VERSION ""

NS_ :

BS_:

BU_: APIM_CISM DSP WCM HUD_ADV ACM GWM _delete APIM IPC GENERIC TSTR

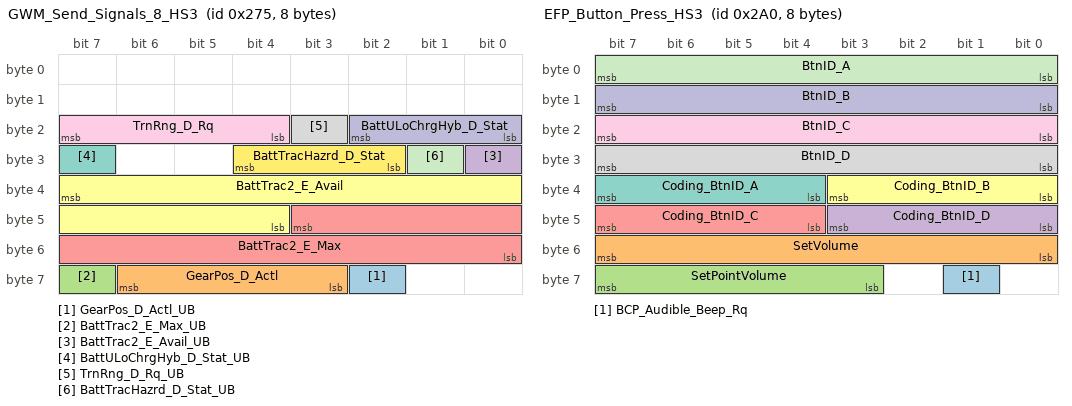
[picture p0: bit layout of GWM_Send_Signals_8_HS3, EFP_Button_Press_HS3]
BO_ 629 GWM_Send_Signals_8_HS3: 8 GWM
 SG_ GearPos_D_Actl_UB : 58|1@0+ (1,0) [0|1] "SED"  APIM_CISM,APIM
 SG_ GearPos_D_Actl : 62|4@0+ (1,0) [0|15] "SED"  APIM_CISM,APIM
 SG_ BattTrac2_E_Max_UB : 63|1@0+ (1,0) [0|1] "SED"  APIM_CISM,APIM
 SG_ BattTrac2_E_Avail_UB : 24|1@0+ (1,0) [0|1] "SED"  APIM
 SG_ BattTrac2_E_Max : 43|12@0+ (50,0) [0|204650] "watt*hour"  APIM_CISM,APIM
 SG_ BattTrac2_E_Avail : 39|12@0+ (50,0) [0|204650] "watt*hour"  APIM
 SG_ BattULoChrgHyb_D_Stat_UB : 31|1@0+ (1,0) [0|1] "SED"  IPC
 SG_ TrnRng_D_Rq_UB : 19|1@0+ (1,0) [0|1] "SED"  APIM_CISM,APIM
 SG_ TrnRng_D_Rq : 23|4@0+ (1,0) [0|15] "SED"  APIM_CISM,APIM
 SG_ BattULoChrgHyb_D_Stat : 18|3@0+ (1,0) [0|7] "SED"  IPC
 SG_ BattTracHazrd_D_Stat_UB : 25|1@0+ (1,0) [0|1] "SED"  IPC
 SG_ BattTracHazrd_D_Stat : 28|3@0+ (1,0) [0|7] "SED"  IPC

BO_ 672 EFP_Button_Press_HS3: 8 GWM
 SG_ BCP_Audible_Beep_Rq : 57|1@0+ (1,0) [0|1] "SED"  ACM,DSP
 SG_ SetVolume : 55|8@0+ (1,-30) [-30|30] "unitless"  DSP,ACM,APIM
 SG_ SetPointVolume : 63|5@0+ (1,0) [0|31] "unitless"  DSP,ACM,APIM
 SG_ Coding_BtnID_D : 43|4@0+ (1,0) [0|15] "SED"  ACM,APIM
 SG_ Coding_BtnID_C : 47|4@0+ (1,0) [0|15] "SED"  ACM,APIM
 SG_ Coding_BtnID_B : 35|4@0+ (1,0) [0|15] "SED"  ACM,APIM
 SG_ Coding_BtnID_A : 39|4@0+ (1,0) [0|15] "SED"  ACM,APIM
 SG_ BtnID_D : 31|8@0+ (1,0) [0|255] "unitless"  ACM,APIM
 SG_ BtnID_C : 23|8@0+ (1,0) [0|255] "unitless"  ACM,APIM
 SG_ BtnID_B : 15|8@0+ (1,0) [0|255] "unitless"  ACM,APIM
 SG_ BtnID_A : 7|8@0+ (1,0) [0|255] "unitless"  ACM,APIM

BO_ 1829 TesterPhysicalReqWCM: 8 TSTR
 SG_ TesterPhysicalReqWCM : 7|64@0+ (1,0) [0|1.84467E+019] "unitless"  WCM

BO_ 601 ECG_MC_WORD_Rx: 8 IPC
 SG_ ECG_MC_WORD_Rx : 7|64@0+ (1,0) [0|1.84467440737096E+019] "unitless"  GWM

BO_ 593 ECG_MC_WORD_Tx: 8 GWM
 SG_ ECG_MC_WORD_Tx : 7|64@0+ (1,0) [0|1.84467440737096E+019] "unitless"  IPC

BO_ 816 APIM_Send_Signals_3: 8 APIM
 SG_ Dimming_Lvl_RqMnu : 63|5@0+ (1,0) [0|31] "SED"  GWM
 SG_ DcacZone3Pw_D_Rq : 55|2@0+ (1,0) [0|3] "SED"  GWM
 SG_ DcacZone2Pw_D_Rq : 35|2@0+ (1,0) [0|3] "SED"  GWM
 SG_ DcacPwScnd_D_Rq : 53|2@0+ (1,0) [0|3] "SED"  GWM
 SG_ DcacPwResetScnd_B_Rq : 24|1@0+ (1,0) [0|1] "SED"  GWM
 SG_ DcacLoFuelLim_L_RqMnu : 32|9@0+ (1,0) [0|511] "kilometer"  GWM
 SG_ DcacAllZone_D_Rq : 37|2@0+ (1,0) [0|3] "SED"  GWM
 SG_ HybMdeSel_D_Rq : 58|3@0+ (1,0) [0|7] "SED"  GWM
 SG_ KeylessIdl_D_Rq : 39|2@0+ (1,0) [0|3] "SED"  GWM
 SG_ KeyPadCodeDgt7_D_Stat : 31|4@0+ (1,0) [0|15] "SED"  GWM
 SG_ KeyPadCodeDgt6_D_Stat : 19|4@0+ (1,0) [0|15] "SED"  GWM
 SG_ KeyPadCodeDgt5_D_Stat : 23|4@0+ (1,0) [0|15] "SED"  GWM
 SG_ KeyPadCodeDgt4_D_Stat : 11|4@0+ (1,0) [0|15] "SED"  GWM
 SG_ KeyPadCodeDgt3_D_Stat : 15|4@0+ (1,0) [0|15] "SED"  GWM
 SG_ KeyPadCodeDgt2_D_Stat : 3|4@0+ (1,0) [0|15] "SED"  GWM
 SG_ KeyPadCodeDgt1_D_Stat : 7|4@0+ (1,0) [0|15] "SED"  GWM
 SG_ CntrStk2_D_RqAssoc : 27|3@0+ (1,0) [0|7] "SED"  GWM

BO_ 636 TCU_Send_Signals_3_HS3: 8 GWM
 SG_ WifiHtsptFqBand_D_Stat : 60|2@0+ (1,0) [0|3] "SED"  APIM_CISM,ACM,APIM
 SG_ WifiHtspt_D_Falt : 51|4@0+ (1,0) [0|15] "SED"  APIM_CISM,ACM,APIM
 SG_ WifiNoDevcCnnct_No_Actl : 47|8@0+ (1,0) [0|255] "unitless"  APIM_CISM,APIM
 SG_ WifiHtsptCnnct_D_Stat : 26|2@0+ (1,0) [0|3] "SED"  APIM_CISM,APIM
 SG_ Telematics_D_Falt : 39|3@0+ (1,0) [0|7] "SED"  APIM_CISM,APIM
 SG_ WifiEnbl_D_Stat : 4|2@0+ (1,0) [0|3] "SED"  APIM_CISM,APIM
 SG_ WifiHtsptVisbl_D_Stat : 13|2@0+ (1,0) [0|3] "SED"  APIM_CISM,APIM
 SG_ WifiHtsptScrty_D_Stat : 15|2@0+ (1,0) [0|3] "SED"  APIM_CISM,APIM
 SG_ WifiHtsptEnbl_D_Stat : 2|2@0+ (1,0) [0|3] "SED"  APIM_CISM,APIM
 SG_ WifiDevcListNew_B_Stat : 5|1@0+ (1,0) [0|1] "SED"  APIM_CISM,APIM
 SG_ WifiDataUsage_Pc_Actl : 20|4@0+ (5,50) [50|125] "percent"  APIM_CISM,APIM
 SG_ WifiDataUsage_D_Stat : 7|2@0+ (1,0) [0|3] "SED"  APIM_CISM,APIM
 SG_ ModemSigStren_D_Stat : 11|3@0+ (1,0) [0|7] "SED"  APIM_CISM,ACM,APIM
 SG_ ModemTechnology_D2_Stat : 31|3@0+ (1,0) [0|7] "SED"  APIM_CISM,HUD_ADV,APIM
 SG_ WifiHtsptCrdntl_B_Stat : 0|1@0+ (1,0) [0|1] "SED"  APIM_CISM,APIM
 SG_ WifiHtsptFq_D_Avail : 63|3@0+ (1,0) [0|7] "SED"  APIM_CISM,ACM,APIM
 SG_ WifiDataUsageOn_D_Stat : 28|2@0+ (1,0) [0|3] "SED"  APIM_CISM,APIM

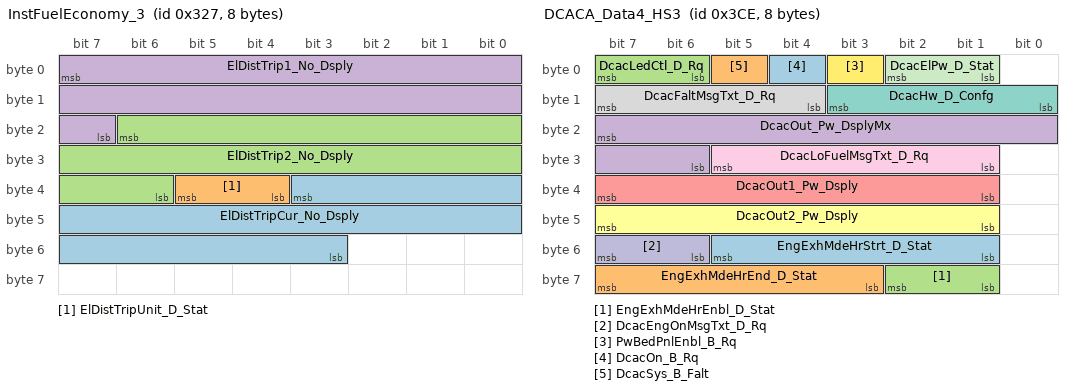
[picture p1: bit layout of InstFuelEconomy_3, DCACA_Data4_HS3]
BO_ 807 InstFuelEconomy_3: 8 IPC
 SG_ ElDistTripCur_No_Dsply : 35|17@0+ (0.1,0) [0|13107.1] "unitless"  APIM
 SG_ ElDistTripUnit_D_Stat : 37|2@0+ (1,0) [0|3] "SED"  APIM
 SG_ ElDistTrip2_No_Dsply : 22|17@0+ (0.1,0) [0|13107.1] "unitless"  APIM
 SG_ ElDistTrip1_No_Dsply : 7|17@0+ (0.1,0) [0|13107.1] "unitless"  APIM

BO_ 974 DCACA_Data4_HS3: 8 GWM
 SG_ EngExhMdeHrStrt_D_Stat : 53|5@0+ (1,0) [0|31] "SED"  APIM
 SG_ EngExhMdeHrEnd_D_Stat : 63|5@0+ (1,0) [0|31] "SED"  APIM
 SG_ EngExhMdeHrEnbl_D_Stat : 58|2@0+ (1,0) [0|3] "SED"  APIM
 SG_ DcacOut_Pw_DsplyMx : 23|10@0+ (10,0) [0|10220] "watts"  APIM
 SG_ DcacOut1_Pw_Dsply : 39|7@0+ (100,0) [0|12600] "watts"  APIM
 SG_ DcacOut2_Pw_Dsply : 47|7@0+ (100,0) [0|12600] "watts"  APIM
 SG_ DcacHw_D_Confg : 11|4@0+ (1,0) [0|15] "SED"  APIM
 SG_ DcacFaltMsgTxt_D_Rq : 15|4@0+ (1,0) [0|15] "SED"  APIM
 SG_ DcacLoFuelMsgTxt_D_Rq : 29|5@0+ (1,0) [0|31] "SED"  APIM
 SG_ DcacEngOnMsgTxt_D_Rq : 55|2@0+ (1,0) [0|3] "SED"  APIM
 SG_ DcacElPw_D_Stat : 2|2@0+ (1,0) [0|3] "SED"  APIM
 SG_ PwBedPnlEnbl_B_Rq : 3|1@0+ (1,0) [0|1] "SED"  GENERIC
 SG_ DcacOn_B_Rq : 4|1@0+ (1,0) [0|1] "SED"  GENERIC
 SG_ DcacSys_B_Falt : 5|1@0+ (1,0) [0|1] "SED"  GENERIC
 SG_ DcacLedCtl_D_Rq : 7|2@0+ (1,0) [0|3] "SED" Vector__XXX

BO_ 805 InstFuelEconomy_2: 8 IPC
 SG_ InstFeTripUnit_D_Stat : 23|4@0+ (1,0) [0|15] "SED"  APIM
 SG_ InstFe_No_Dsply : 7|14@0+ (0.1,0) [0|1638.3] "unitless"  APIM

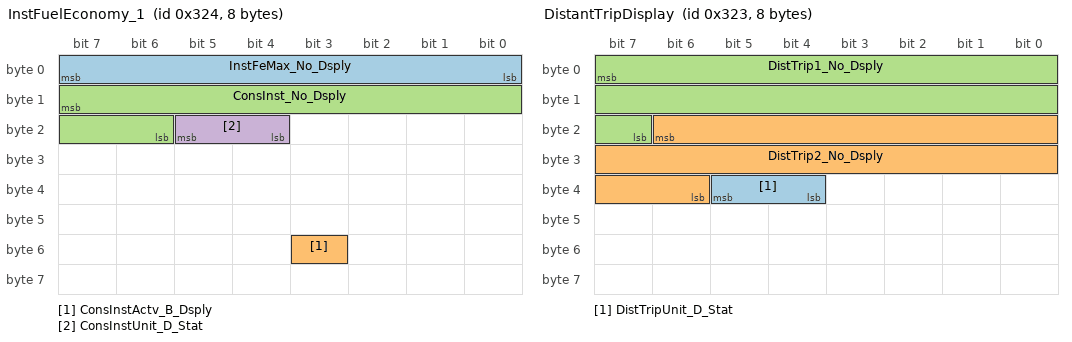
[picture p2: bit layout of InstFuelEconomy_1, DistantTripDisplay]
BO_ 804 InstFuelEconomy_1: 8 IPC
 SG_ InstFeMax_No_Dsply : 7|8@0+ (1,0) [0|255] "unitless"  APIM
 SG_ ConsInstActv_B_Dsply : 51|1@0+ (1,0) [0|1] "SED"  APIM
 SG_ ConsInst_No_Dsply : 15|10@0+ (0.1,0) [0|102.3] "percent"  APIM
 SG_ ConsInstUnit_D_Stat : 21|2@0+ (1,0) [0|3] "SED"  APIM

BO_ 803 DistantTripDisplay: 8 IPC
 SG_ DistTripUnit_D_Stat : 37|2@0+ (1,0) [0|3] "SED"  APIM
 SG_ DistTrip2_No_Dsply : 22|17@0+ (0.1,0) [0|13107.1] "unitless"  APIM
 SG_ DistTrip1_No_Dsply : 7|17@0+ (0.1,0) [0|13107.1] "unitless"  APIM

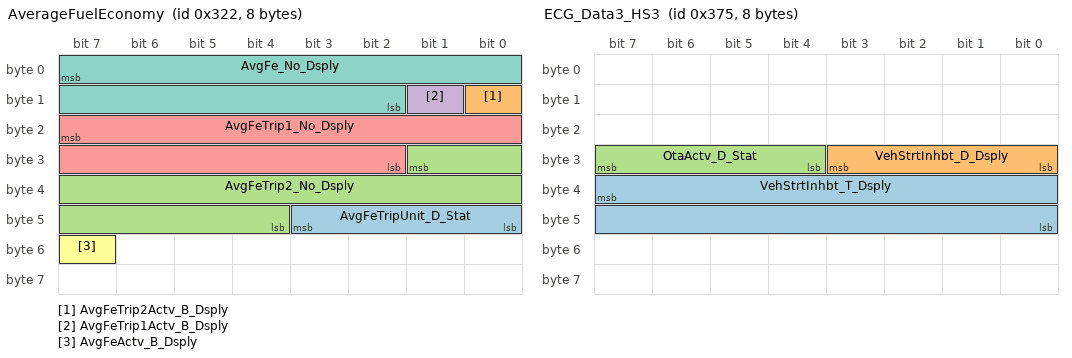
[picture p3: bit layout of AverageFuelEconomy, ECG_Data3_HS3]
BO_ 802 AverageFuelEconomy: 8 IPC
 SG_ AvgFeTripUnit_D_Stat : 43|4@0+ (1,0) [0|15] "SED"  APIM_CISM,APIM
 SG_ AvgFeTrip2Actv_B_Dsply : 8|1@0+ (1,0) [0|1] "SED"  APIM_CISM,APIM
 SG_ AvgFeTrip2_No_Dsply : 25|14@0+ (0.1,0) [0|1638.3] "unitless"  APIM_CISM,APIM
 SG_ AvgFeTrip1Actv_B_Dsply : 9|1@0+ (1,0) [0|1] "SED"  APIM_CISM,APIM
 SG_ AvgFeTrip1_No_Dsply : 23|14@0+ (0.1,0) [0|1638.3] "unitless"  APIM_CISM,APIM
 SG_ AvgFeActv_B_Dsply : 55|1@0+ (1,0) [0|1] "SED"  APIM_CISM,APIM
 SG_ AvgFe_No_Dsply : 7|14@0+ (0.1,0) [0|1638.3] "unitless"  APIM_CISM,APIM

BO_ 812 TimerDisplay_Data: 8 IPC
 SG_ TimerTrip2_T_Dsply : 29|26@0+ (1,0) [0|67108863] "second"  APIM
 SG_ TimerTrip1_T_Dsply : 7|26@0+ (1,0) [0|67108863] "second"  APIM

BO_ 885 ECG_Data3_HS3: 8 GWM
 SG_ VehStrtInhbt_T_Dsply : 39|16@0+ (1,0) [0|65535] "second"  IPC
 SG_ VehStrtInhbt_D_Dsply : 27|4@0+ (1,0) [0|15] "SED"  IPC
 SG_ OtaActv_D_Stat : 31|4@0+ (1,0) [0|15] "SED"  IPC

BO_ 1119 LocationServices_Data2: 8 APIM
 SG_ LocationServices_2 : 7|64@0+ (1,0) [0|1.84467440737096E+019] "unitless"  IPC,GWM

BO_ 1118 LocationServices_Data1: 8 APIM
 SG_ LocationServices_1 : 7|64@0+ (1,0) [0|1.84467440737096E+019] "unitless"  IPC,GWM

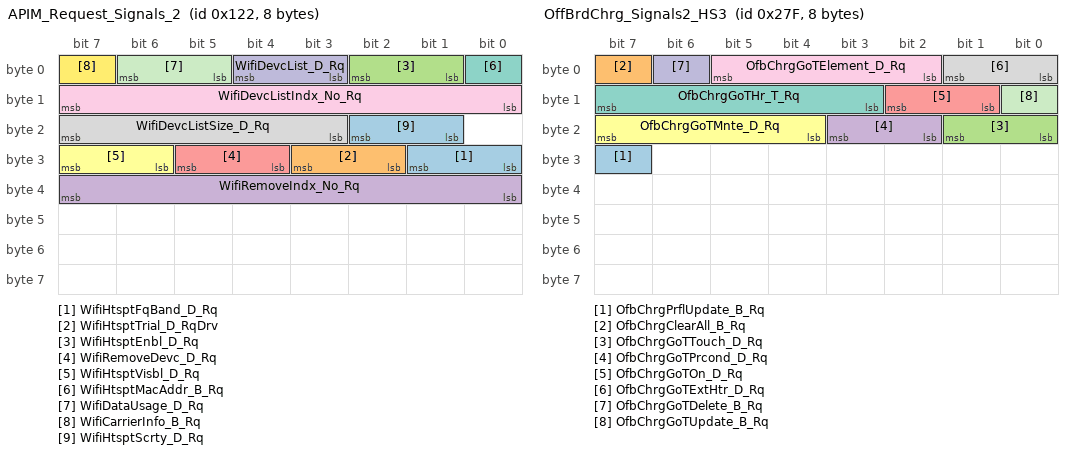
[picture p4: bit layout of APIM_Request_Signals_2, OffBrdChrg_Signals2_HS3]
BO_ 290 APIM_Request_Signals_2: 8 APIM
 SG_ WifiHtsptFqBand_D_Rq : 25|2@0+ (1,0) [0|3] "SED"  GWM
 SG_ WifiHtsptTrial_D_RqDrv : 27|2@0+ (1,0) [0|3] "SED"  GWM
 SG_ WifiHtsptEnbl_D_Rq : 2|2@0+ (1,0) [0|3] "SED"  GWM
 SG_ WifiRemoveIndx_No_Rq : 39|8@0+ (1,0) [0|255] "unitless"  GWM
 SG_ WifiRemoveDevc_D_Rq : 29|2@0+ (1,0) [0|3] "SED"  GWM
 SG_ WifiHtsptVisbl_D_Rq : 31|2@0+ (1,0) [0|3] "SED"  GWM
 SG_ WifiHtsptMacAddr_B_Rq : 0|1@0+ (1,0) [0|1] "SED"  GWM
 SG_ WifiDevcListSize_D_Rq : 23|5@0+ (1,0) [0|31] "unitless"  GWM
 SG_ WifiDevcListIndx_No_Rq : 15|8@0+ (1,0) [0|255] "unitless"  GWM
 SG_ WifiDevcList_D_Rq : 4|2@0+ (1,0) [0|3] "SED"  GWM
 SG_ WifiDataUsage_D_Rq : 6|2@0+ (1,0) [0|3] "SED"  GWM
 SG_ WifiCarrierInfo_B_Rq : 7|1@0+ (1,0) [0|1] "SED"  GWM
 SG_ WifiHtsptScrty_D_Rq : 18|2@0+ (1,0) [0|3] "SED"  GWM

BO_ 2612101336 PARSEDPushFcGWMtoIPC: 8 GWM
 SG_ PARSEDPushFcGWM_ECGtoIPC : 7|29@0+ (1,0) [0|536870911] "unitless"  IPC

BO_ 639 OffBrdChrg_Signals2_HS3: 8 GWM
 SG_ OfbChrgPrflUpdate_B_Rq : 31|1@0+ (1,0) [0|1] "SED"  APIM
 SG_ OfbChrgClearAll_B_Rq : 7|1@0+ (1,0) [0|1] "SED"  GENERIC
 SG_ OfbChrgGoTTouch_D_Rq : 17|2@0+ (1,0) [0|3] "SED"  GENERIC
 SG_ OfbChrgGoTPrcond_D_Rq : 19|2@0+ (1,0) [0|3] "SED"  GENERIC
 SG_ OfbChrgGoTOn_D_Rq : 10|2@0+ (1,0) [0|3] "SED"  GENERIC
 SG_ OfbChrgGoTMnte_D_Rq : 23|4@0+ (1,0) [0|15] "minute"  GENERIC
 SG_ OfbChrgGoTHr_T_Rq : 15|5@0+ (1,0) [0|29] "hour"  GENERIC
 SG_ OfbChrgGoTExtHtr_D_Rq : 1|2@0+ (1,0) [0|3] "SED"  GENERIC
 SG_ OfbChrgGoTElement_D_Rq : 5|4@0+ (1,0) [0|15] "Unitless"  GENERIC
 SG_ OfbChrgGoTDelete_B_Rq : 6|1@0+ (1,0) [0|1] "SED"  GENERIC
 SG_ OfbChrgGoTUpdate_B_Rq : 8|1@0+ (1,0) [0|1] "SED"  APIM

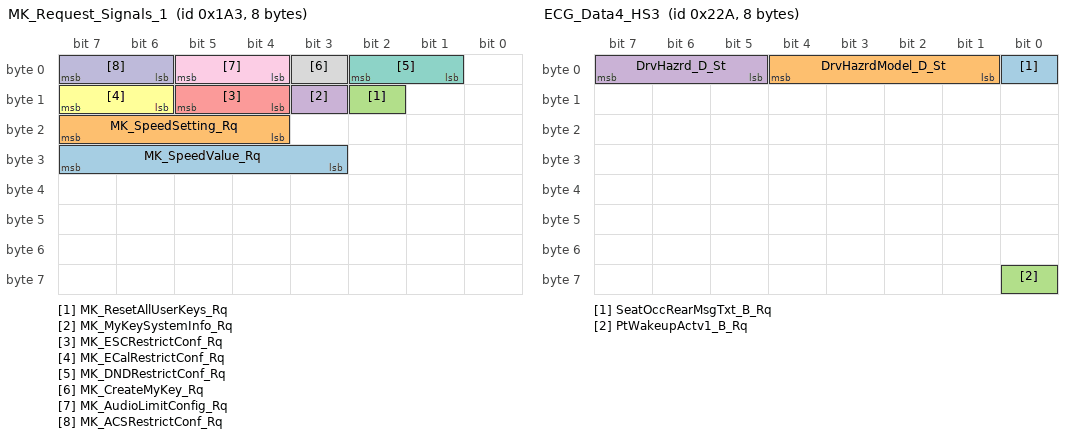
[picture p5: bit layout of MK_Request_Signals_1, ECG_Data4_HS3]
BO_ 419 MK_Request_Signals_1: 8 APIM
 SG_ MK_SpeedValue_Rq : 31|5@0+ (1,0) [0|31] "SED"  IPC
 SG_ MK_SpeedSetting_Rq : 23|4@0+ (1,0) [0|15] "SED"  IPC
 SG_ MK_ResetAllUserKeys_Rq : 10|1@0+ (1,0) [0|1] "SED"  IPC
 SG_ MK_MyKeySystemInfo_Rq : 11|1@0+ (1,0) [0|1] "SED"  IPC
 SG_ MK_ESCRestrictConf_Rq : 13|2@0+ (1,0) [0|3] "SED"  IPC
 SG_ MK_ECalRestrictConf_Rq : 15|2@0+ (1,0) [0|3] "SED"  IPC
 SG_ MK_DNDRestrictConf_Rq : 2|2@0+ (1,0) [0|3] "SED"  IPC
 SG_ MK_CreateMyKey_Rq : 3|1@0+ (1,0) [0|1] "SED"  IPC
 SG_ MK_AudioLimitConfig_Rq : 5|2@0+ (1,0) [0|3] "SED"  IPC
 SG_ MK_ACSRestrictConf_Rq : 7|2@0+ (1,0) [0|3] "SED"  IPC

BO_ 542 LocationServices_3_HS3: 8 GWM
 SG_ LocationServices_3 : 7|64@0+ (1,0) [0|1.84467440737096E+019] "unitless"  APIM_CISM,IPC,APIM,ACM

BO_ 554 ECG_Data4_HS3: 8 GWM
 SG_ SeatOccRearMsgTxt_B_Rq : 0|1@0+ (1,0) [0|1] "SED"  APIM_CISM,APIM
 SG_ DrvHazrdModel_D_St : 4|4@0+ (1,0) [0|15] "SED"  APIM_CISM,IPC,APIM
 SG_ PtWakeupActv1_B_Rq : 56|1@0+ (1,0) [0|1] "SED"  APIM_CISM,APIM
 SG_ DrvHazrd_D_St : 7|3@0+ (1,0) [0|7] "SED"  APIM_CISM,HUD_ADV,APIM,IPC

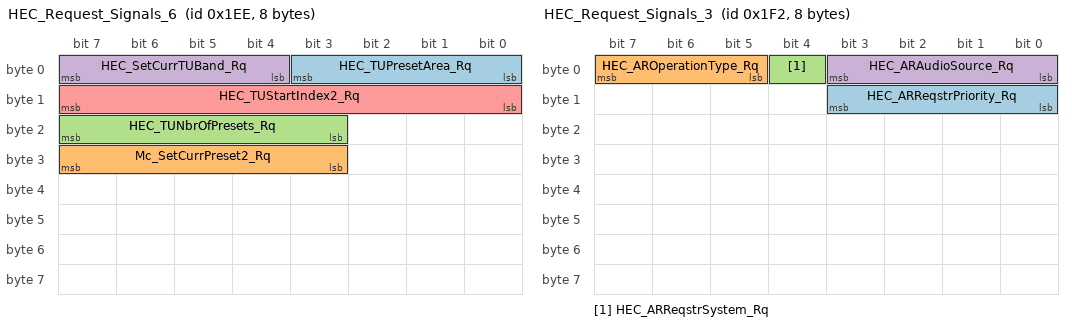
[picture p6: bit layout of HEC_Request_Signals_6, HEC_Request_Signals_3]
BO_ 494 HEC_Request_Signals_6: 8 IPC
 SG_ HEC_TUPresetArea_Rq : 3|4@0+ (1,0) [0|15] "SED"  ACM
 SG_ Mc_SetCurrPreset2_Rq : 31|5@0+ (1,0) [0|30] "SED"  ACM
 SG_ HEC_TUNbrOfPresets_Rq : 23|5@0+ (1,0) [0|30] "unitless"  ACM
 SG_ HEC_SetCurrTUBand_Rq : 7|4@0+ (1,0) [0|15] "SED"  ACM
 SG_ HEC_TUStartIndex2_Rq : 15|8@0+ (1,0) [0|255] "unitless"  ACM

BO_ 498 HEC_Request_Signals_3: 8 IPC
 SG_ HEC_ARReqstrPriority_Rq : 11|4@0+ (1,0) [0|15] "SED"  APIM_CISM,ACM
 SG_ HEC_AROperationType_Rq : 7|3@0+ (1,0) [0|7] "SED"  APIM_CISM,ACM
 SG_ HEC_ARReqstrSystem_Rq : 4|1@0+ (1,0) [0|1] "SED"  APIM_CISM,ACM
 SG_ HEC_ARAudioSource_Rq : 3|4@0+ (1,0) [0|15] "SED"  APIM_CISM,ACM

BO_ 644 GWM_Send_Signals_19_HS3: 8 GWM
 SG_ VehOnSrc_D_Stat_UB : 3|1@0+ (1,0) [0|1] "SED"  APIM_CISM,APIM,IPC
 SG_ VehOnSrc_D_Stat : 7|4@0+ (1,0) [0|15] "SED"  APIM_CISM,APIM,IPC

BO_ 643 GWM_Send_Signals_18_HS3: 8 GWM
 SG_ StrtInGearMsgTxt_D_Rq_UB : 48|1@0+ (1,0) [0|1] "SED"  IPC
 SG_ StrtInGearMsgTxt_D_Rq : 59|4@0+ (1,0) [0|15] "SED"  IPC
 SG_ StabBarCnnct_D_Stat_UB : 49|1@0+ (1,0) [0|1] "SED"  APIM
 SG_ StabBarCnnct_D_Stat : 63|4@0+ (1,0) [0|15] "SED"  APIM
 SG_ FstChrgCmplt_T_Est : 33|10@0+ (1,0) [0|1023] "minute"  IPC,APIM
 SG_ GearPos_D_Trg_UB : 23|1@0+ (1,0) [0|1] "SED"  APIM_CISM,APIM
 SG_ GearPos_D_Trg : 11|4@0+ (1,0) [0|15] "SED"  APIM_CISM,APIM
 SG_ PwTgateStepMsgTxt_B_Rq : 13|1@0+ (1,0) [0|1] "SED"  IPC
 SG_ PwTgateStepMsgTxt_B_Rq_UB : 12|1@0+ (1,0) [0|1] "SED"  IPC
 SG_ PwTgateMsgTxt_B_Rq_UB : 14|1@0+ (1,0) [0|1] "SED"  IPC
 SG_ PwTgateLamp_B_Rq_UB : 0|1@0+ (1,0) [0|1] "SED"  IPC
 SG_ PwTgateMsgTxt_B_Rq : 15|1@0+ (1,0) [0|1] "SED"  IPC
 SG_ PwTgateLamp_B_Rq : 1|1@0+ (1,0) [0|1] "SED"  IPC
 SG_ PwRnngBoardSwtch_D_Stat_UB : 5|1@0+ (1,0) [0|1] "SED"  IPC,APIM
 SG_ PwRnngBoardT_D_Stat_UB : 2|1@0+ (1,0) [0|1] "SED"  IPC,APIM
 SG_ PwRnngBoardT_D_Stat : 4|2@0+ (1,0) [0|3] "SED"  IPC,APIM
 SG_ PwRnngBoardSwtch_D_Stat : 7|2@0+ (1,0) [0|3] "SED"  IPC,APIM
 SG_ OnePdlDrvLamp_B_Rq_UB : 52|1@0+ (1,0) [0|1] "SED"  IPC
 SG_ OnePdlDrv_D_Dsply_UB : 53|1@0+ (1,0) [0|1] "SED"  IPC,APIM
 SG_ OnePdlDrvLamp_B_Rq : 34|1@0+ (1,0) [0|1] "SED"  IPC
 SG_ OnePdlDrv_D_Dsply : 55|2@0+ (1,0) [0|3] "SED"  IPC,APIM
 SG_ SeatSlprPosMsgTxt_B_Rq_UB : 50|1@0+ (1,0) [0|1] "SED"  IPC
 SG_ SeatSlprPosMsgTxt_B_Rq : 51|1@0+ (1,0) [0|1] "SED"  IPC
 SG_ DrPrsntRearPsngr_D_Stat_UB : 36|1@0+ (1,0) [0|1] "SED"  APIM_CISM,IPC,APIM
 SG_ DrPrsntPsngr_D_Stat_UB : 37|1@0+ (1,0) [0|1] "SED"  APIM_CISM,IPC,APIM
 SG_ DrPsngrMsgTxt_B_Rq_UB : 38|1@0+ (1,0) [0|1] "SED"  IPC
 SG_ DrPsngrMsgTxt_B_Rq : 39|1@0+ (1,0) [0|1] "SED"  IPC
 SG_ DrPrsntRearPsngr_D_Stat : 25|2@0+ (1,0) [0|3] "SED"  APIM_CISM,IPC,APIM
 SG_ DrPrsntPsngr_D_Stat : 27|2@0+ (1,0) [0|3] "SED"  APIM_CISM,IPC,APIM
 SG_ DrPrsntRearDrv_D_Stat_UB : 30|1@0+ (1,0) [0|1] "SED"  APIM_CISM,IPC,APIM
 SG_ DrDrvMsgTxt_B_Rq_UB : 28|1@0+ (1,0) [0|1] "SED"  IPC
 SG_ DrPrsntDrv_D_Stat_UB : 31|1@0+ (1,0) [0|1] "SED"  APIM_CISM,APIM,IPC
 SG_ DrPrsntDrv_D_Stat : 19|2@0+ (1,0) [0|3] "SED"  APIM_CISM,APIM,IPC
 SG_ DrPrsntRearDrv_D_Stat : 17|2@0+ (1,0) [0|3] "SED"  APIM_CISM,IPC,APIM
 SG_ DrDrvMsgTxt_B_Rq : 29|1@0+ (1,0) [0|1] "SED"  IPC
 SG_ FstChrgCmplt_T_Est_UB : 35|1@0+ (1,0) [0|1] "SED"  IPC,APIM
 SG_ TrunkFrontOpen_D_Stat_UB : 20|1@0+ (1,0) [0|1] "SED"  APIM
 SG_ TrunkFrontOpen_D_Stat : 22|2@0+ (1,0) [0|3] "SED"  APIM

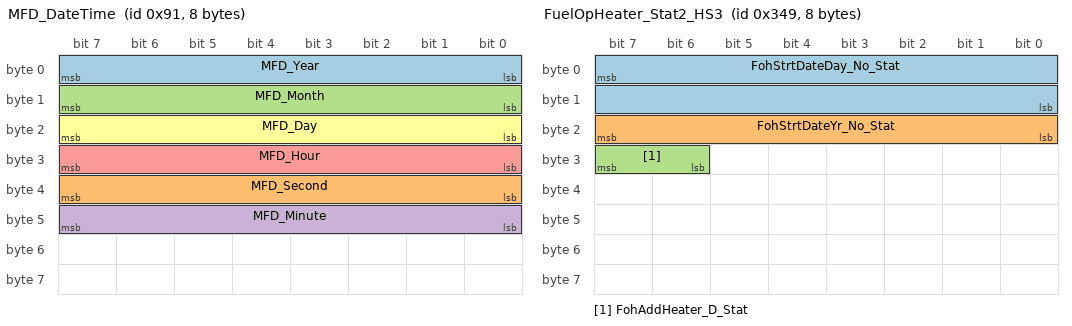
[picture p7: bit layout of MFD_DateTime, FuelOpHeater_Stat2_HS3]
BO_ 145 MFD_DateTime: 8 APIM
 SG_ MFD_Year : 7|8@0+ (1,2000) [2000|2254] "year"  IPC,DSP
 SG_ MFD_Second : 39|8@0+ (1,0) [0|59] "second"  IPC,DSP
 SG_ MFD_Month : 15|8@0+ (1,0) [0|12] "month"  IPC,DSP
 SG_ MFD_Minute : 47|8@0+ (1,0) [0|59] "minute"  IPC,DSP
 SG_ MFD_Hour : 31|8@0+ (1,0) [0|23] "hour"  IPC,DSP
 SG_ MFD_Day : 23|8@0+ (1,0) [0|31] "day"  IPC,DSP

BO_ 841 FuelOpHeater_Stat2_HS3: 8 GWM
 SG_ FohStrtDateDay_No_Stat : 7|16@0+ (1,0) [0|65535] "julian day"  IPC
 SG_ FohStrtDateYr_No_Stat : 23|8@0+ (1,2000) [2000|2255] "year"  IPC
 SG_ FohAddHeater_D_Stat : 31|2@0+ (1,0) [0|3] "SED"  IPC

BO_ 545 DSPAMP_Send_Signals_1: 8 DSP
 SG_ SpkrDgtlRight_D_Stat : 47|2@0+ (1,0) [0|3] "SED" Vector__XXX
 SG_ SpkrDgtlLeft_D_Stat : 45|2@0+ (1,0) [0|3] "SED" Vector__XXX
 SG_ SpkrDgtlCntr_D_Stat : 43|2@0+ (1,0) [0|3] "SED"  APIM_CISM,ACM
 SG_ SurndSndUpmix2_D_Stat : 34|3@0+ (1,0) [0|7] "SED"  APIM_CISM,APIM
 SG_ DSP_Bezel_Diag_St : 23|4@0+ (1,0) [0|15] "SED"  APIM_CISM,APIM
 SG_ SndImmrsnLvl_D_Stat : 55|8@0+ (1,0) [0|255] "SED"  APIM_CISM,APIM
 SG_ DSP_Sur_Sound_st : 7|2@0+ (1,0) [0|3] "SED"  APIM_CISM,APIM
 SG_ DSP_MyKeyVolLimitUp_St : 19|2@0+ (1,0) [0|3] "SED"  APIM_CISM,APIM
 SG_ DSP_MyKeyVolLim_St : 2|2@0+ (1,0) [0|3] "SED"  APIM_CISM,APIM
 SG_ DSP_BeltminderAudio_St : 4|2@0+ (1,0) [0|3] "SED"  APIM_CISM,APIM
 SG_ DSP_Audio_Volume_Up_St : 9|1@0+ (1,0) [0|1] "SED"  APIM_CISM,IPC,HUD_ADV,GWM,APIM
 SG_ DSP_Audio_Vol_Level_St : 15|5@0+ (1,0) [0|30] "unitless"  APIM_CISM,GWM,IPC,WCM,HUD_ADV,ACM,APIM
 SG_ AutoConfigOcc_Rear : 28|1@0+ (1,0) [0|1] "SED"  APIM_CISM,APIM
 SG_ AutoConfigOcc_Front : 30|1@0+ (1,0) [0|1] "SED"  APIM_CISM,APIM
 SG_ AutoConfigOcc_Driver : 31|1@0+ (1,0) [0|1] "SED"  APIM_CISM,APIM
 SG_ AutoConfigOcc_AllSeats : 29|1@0+ (1,0) [0|1] "SED"  APIM_CISM,APIM
 SG_ AudioOccMde_D_Stat : 39|5@0+ (1,0) [0|31] "SED"  APIM_CISM,APIM

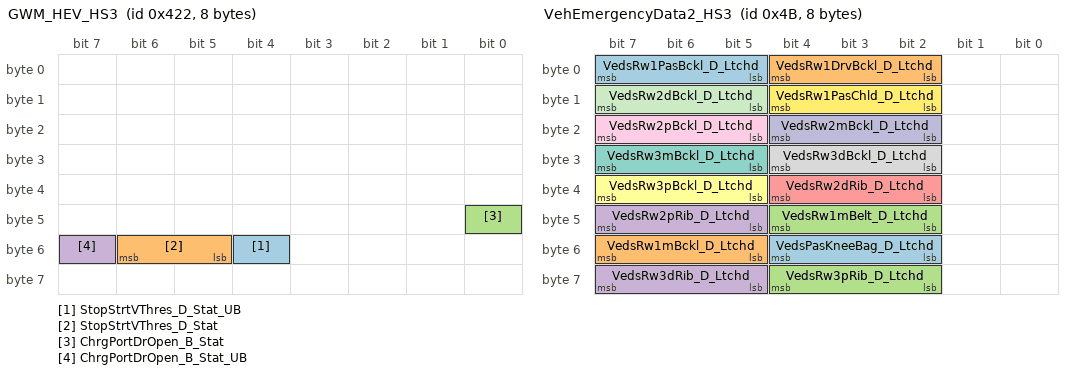
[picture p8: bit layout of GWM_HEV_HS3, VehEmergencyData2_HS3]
BO_ 1058 GWM_HEV_HS3: 8 GWM
 SG_ StopStrtVThres_D_Stat_UB : 52|1@0+ (1,0) [0|1] "SED"  APIM,IPC
 SG_ StopStrtVThres_D_Stat : 54|2@0+ (1,0) [0|3] "SED"  APIM,IPC
 SG_ ChrgPortDrOpen_B_Stat : 40|1@0+ (1,0) [0|1] "SED"  IPC
 SG_ ChrgPortDrOpen_B_Stat_UB : 55|1@0+ (1,0) [0|1] "SED"  IPC

BO_ 633 GWM_Send_Signals_6_HS3: 8 GWM
 SG_ RearDiffLckMsg2_D_Rq_UB : 63|1@0+ (1,0) [0|1] "SED"  IPC
 SG_ RearDiffLckMsg2_D_Rq : 21|4@0+ (1,0) [0|15] "SED"  IPC
 SG_ PwStepMsgTxt_D_Rq_UB : 5|1@0+ (1,0) [0|1] "SED"  IPC
 SG_ PwStepMsgTxt_D_Rq : 7|2@0+ (1,0) [0|3] "SED"  IPC
 SG_ RearDiffLck_D_RqDrv : 39|2@0+ (1,0) [0|3] "SED"  IPC
 SG_ AwdMde_D_RqDrv : 37|3@0+ (1,0) [0|7] "SED"  IPC
 SG_ RearDiffLck_D_RqDrv_UB : 34|1@0+ (1,0) [0|1] "SED"  IPC
 SG_ TsrRegionTxt_D_Stat_UB : 10|1@0+ (1,0) [0|1] "SED"  HUD_ADV,IPC
 SG_ AwdMde_D_RqDrv_UB : 53|1@0+ (1,0) [0|1] "SED"  IPC
 SG_ TsrRegionTxt_D_Stat : 15|5@0+ (1,0) [0|31] "SED"  HUD_ADV,IPC
 SG_ GsmGearMsgTxt_D_Rq_UB : 57|1@0+ (1,0) [0|1] "SED"  IPC
 SG_ GsmGearMsgTxt_D_Rq : 59|2@0+ (1,0) [0|3] "SED"  IPC
 SG_ RearDiffLckLamp_D_Rq2_UB : 54|1@0+ (1,0) [0|1] "SED"  IPC
 SG_ RearDiffLckLamp_D_Rq2 : 23|2@0+ (1,0) [0|3] "SED"  IPC
 SG_ DasAlrtInfo_D_Dsply_UB : 60|1@0+ (1,0) [0|1] "SED"  APIM
 SG_ DasAlrtInfo_D_Dsply : 62|2@0+ (1,0) [0|3] "SED"  APIM
 SG_ Shed_Feature_Group_ID_UB : 56|1@0+ (1,0) [0|1] "SED" Vector__XXX
 SG_ Shed_Feature_Group_ID : 4|5@0+ (1,0) [0|31] "SED" Vector__XXX

BO_ 936 ParkAid_Data_HS3: 8 GWM
 SG_ SAPPStatusCoding : 7|8@0+ (1,0) [0|255] "unitless"  APIM_CISM,APIM
 SG_ ApaButtnPrssd_B_Stat : 58|1@0+ (1,0) [0|1] "SED"  GENERIC
 SG_ ApaSys_D_Stat : 61|3@0+ (1,0) [0|7] "SED"  APIM_CISM,IPC,ACM,APIM
 SG_ ApaSteWhl_D_RqDrv : 63|2@0+ (1,0) [0|3] "SED"  APIM_CISM,ACM,APIM
 SG_ ApaSteScanMde_D_Stat : 49|2@0+ (1,0) [0|3] "SED"  APIM_CISM,ACM,APIM
 SG_ ApaSelSapp_D_Stat : 51|2@0+ (1,0) [0|3] "SED"  APIM_CISM,ACM,APIM
 SG_ ApaSelPpa_D_Stat : 53|2@0+ (1,0) [0|3] "SED"  APIM_CISM,ACM,APIM
 SG_ ApaSelPoa_D_Stat : 55|2@0+ (1,0) [0|3] "SED"  APIM_CISM,ACM,APIM
 SG_ ApaScan_D_Stat : 41|2@0+ (1,0) [0|3] "SED"  APIM_CISM,ACM,APIM
 SG_ ApaLongCtl_D_RqDrv : 44|3@0+ (1,0) [0|7] "SED"  APIM_CISM,ACM,APIM
 SG_ ApaGearShif_D_RqDrv : 47|3@0+ (1,0) [0|7] "SED"  APIM_CISM,ACM,APIM
 SG_ ApaActvSide2_D_Stat : 33|2@0+ (1,0) [0|3] "SED"  APIM_CISM,ACM,APIM
 SG_ ApaAcsy_D_RqDrv : 36|3@0+ (1,0) [0|7] "SED"  APIM_CISM,ACM,APIM
 SG_ ApaChime_D_Rq : 39|3@0+ (1,0) [0|7] "SED"  IPC
 SG_ EPASExtAngleStatReq : 23|1@0+ (1,0) [0|1] "SED" Vector__XXX
 SG_ ExtSteeringAngleReq2 : 22|15@0+ (0.1,-1000) [-1000|2276.5] "Degrees" Vector__XXX
 SG_ ApaTrgtDist_D_Stat : 11|4@0+ (1,0) [0|15] "SED"  APIM_CISM,APIM,ACM
 SG_ ApaMsgTxt_D_Rq : 15|4@0+ (1,0) [0|15] "SED"  APIM_CISM,APIM,ACM

BO_ 75 VehEmergencyData2_HS3: 8 GWM
 SG_ VedsPasKneeBag_D_Ltchd : 52|3@0+ (1,0) [0|7] "SED"  APIM_CISM,APIM,ACM
 SG_ VedsRw1mBckl_D_Ltchd : 55|3@0+ (1,0) [0|7] "SED"  APIM_CISM,APIM
 SG_ VedsRw1mBelt_D_Ltchd : 44|3@0+ (1,0) [0|7] "SED"  APIM_CISM,APIM
 SG_ VedsRw2pRib_D_Ltchd : 47|3@0+ (1,0) [0|7] "SED"  APIM_CISM,APIM
 SG_ VedsRw2dRib_D_Ltchd : 36|3@0+ (1,0) [0|7] "SED"  APIM_CISM,APIM
 SG_ VedsRw3pBckl_D_Ltchd : 39|3@0+ (1,0) [0|7] "SED"  APIM_CISM,APIM
 SG_ VedsRw3mBckl_D_Ltchd : 31|3@0+ (1,0) [0|7] "SED"  APIM_CISM,APIM
 SG_ VedsRw3dBckl_D_Ltchd : 28|3@0+ (1,0) [0|7] "SED"  APIM_CISM,APIM
 SG_ VedsRw2pBckl_D_Ltchd : 23|3@0+ (1,0) [0|7] "SED"  APIM_CISM,APIM
 SG_ VedsRw2mBckl_D_Ltchd : 20|3@0+ (1,0) [0|7] "SED"  APIM_CISM,APIM
 SG_ VedsRw2dBckl_D_Ltchd : 15|3@0+ (1,0) [0|7] "SED"  APIM_CISM,APIM
 SG_ VedsRw1PasChld_D_Ltchd : 12|3@0+ (1,0) [0|7] "SED"  APIM_CISM,APIM
 SG_ VedsRw1PasBckl_D_Ltchd : 7|3@0+ (1,0) [0|7] "SED"  APIM_CISM,APIM
 SG_ VedsRw1DrvBckl_D_Ltchd : 4|3@0+ (1,0) [0|7] "SED"  APIM_CISM,APIM
 SG_ VedsRw3pRib_D_Ltchd : 60|3@0+ (1,0) [0|7] "SED"  APIM_CISM,APIM
 SG_ VedsRw3dRib_D_Ltchd : 63|3@0+ (1,0) [0|7] "SED"  APIM_CISM,APIM

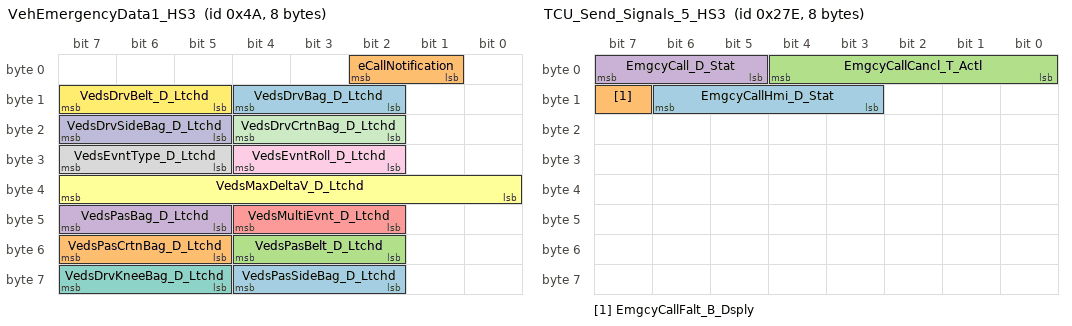
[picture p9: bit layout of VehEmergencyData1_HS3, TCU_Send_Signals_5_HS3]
BO_ 74 VehEmergencyData1_HS3: 8 GWM
 SG_ VedsPasSideBag_D_Ltchd : 60|3@0+ (1,0) [0|7] "SED"  APIM_CISM,APIM
 SG_ VedsPasCrtnBag_D_Ltchd : 55|3@0+ (1,0) [0|7] "SED"  APIM_CISM,APIM
 SG_ VedsPasBelt_D_Ltchd : 52|3@0+ (1,0) [0|7] "SED"  APIM_CISM,APIM
 SG_ VedsPasBag_D_Ltchd : 47|3@0+ (1,0) [0|7] "SED"  APIM_CISM,APIM
 SG_ VedsMultiEvnt_D_Ltchd : 44|3@0+ (1,0) [0|7] "SED"  APIM_CISM,APIM
 SG_ VedsMaxDeltaV_D_Ltchd : 39|8@0+ (1,0) [0|255] "kph"  APIM_CISM,APIM
 SG_ VedsDrvKneeBag_D_Ltchd : 63|3@0+ (1,0) [0|7] "SED"  APIM_CISM,APIM
 SG_ VedsEvntType_D_Ltchd : 31|3@0+ (1,0) [0|7] "SED"  APIM_CISM,APIM
 SG_ VedsEvntRoll_D_Ltchd : 28|3@0+ (1,0) [0|7] "SED"  APIM_CISM,APIM
 SG_ VedsDrvSideBag_D_Ltchd : 23|3@0+ (1,0) [0|7] "SED"  APIM_CISM,APIM
 SG_ VedsDrvCrtnBag_D_Ltchd : 20|3@0+ (1,0) [0|7] "SED"  APIM_CISM,APIM
 SG_ VedsDrvBelt_D_Ltchd : 15|3@0+ (1,0) [0|7] "SED"  APIM_CISM,APIM
 SG_ VedsDrvBag_D_Ltchd : 12|3@0+ (1,0) [0|7] "SED"  APIM_CISM,APIM,ACM
 SG_ eCallNotification : 2|2@0+ (1,0) [0|3] "SED"  APIM_CISM,APIM

BO_ 638 TCU_Send_Signals_5_HS3: 8 GWM
 SG_ EmgcyCallHmi_D_Stat : 14|4@0+ (1,0) [0|15] "SED"  APIM_CISM,APIM
 SG_ EmgcyCallFalt_B_Dsply : 15|1@0+ (1,0) [0|1] "SED"  IPC
 SG_ EmgcyCallCancl_T_Actl : 4|5@0+ (1,0) [0|31] "second"  APIM_CISM,APIM
 SG_ EmgcyCall_D_Stat : 7|3@0+ (1,0) [0|7] "SED"  APIM_CISM,APIM

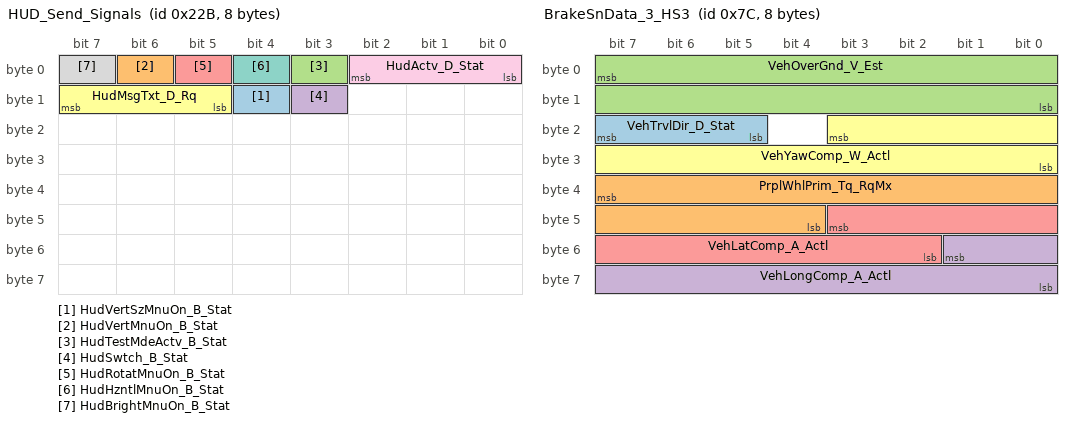
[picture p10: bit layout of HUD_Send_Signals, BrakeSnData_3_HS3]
BO_ 555 HUD_Send_Signals: 8 HUD_ADV
 SG_ HudVertSzMnuOn_B_Stat : 12|1@0+ (1,0) [0|1] "SED"  IPC
 SG_ HudVertMnuOn_B_Stat : 6|1@0+ (1,0) [0|1] "SED"  IPC
 SG_ HudTestMdeActv_B_Stat : 3|1@0+ (1,0) [0|1] "SED"  IPC
 SG_ HudSwtch_B_Stat : 11|1@0+ (1,0) [0|1] "SED"  IPC
 SG_ HudRotatMnuOn_B_Stat : 5|1@0+ (1,0) [0|1] "SED"  IPC
 SG_ HudMsgTxt_D_Rq : 15|3@0+ (1,0) [0|7] "SED"  IPC
 SG_ HudHzntlMnuOn_B_Stat : 4|1@0+ (1,0) [0|1] "SED"  IPC
 SG_ HudBrightMnuOn_B_Stat : 7|1@0+ (1,0) [0|1] "SED"  IPC
 SG_ HudActv_D_Stat : 2|3@0+ (1,0) [0|7] "SED"  IPC

BO_ 124 BrakeSnData_3_HS3: 8 GWM
 SG_ VehTrvlDir_D_Stat : 23|3@0+ (1,0) [0|7] "SED"  GENERIC
 SG_ PrplWhlPrim_Tq_RqMx : 39|12@0+ (8,0) [0|32760] "Nm"  GENERIC
 SG_ VehOverGnd_V_Est : 7|16@0+ (0.01,0) [0|655.33] "kph"  IPC,APIM
 SG_ VehLongComp_A_Actl : 49|10@0+ (0.035,-17.9) [-17.9|17.835] "m/s^2"  IPC,APIM
 SG_ VehLatComp_A_Actl : 43|10@0+ (0.035,-17.9) [-17.9|17.835] "m/s^2"  IPC,APIM
 SG_ VehYawComp_W_Actl : 19|12@0+ (0.03663,-75) [-75|74.92659] "deg/s"  IPC,APIM

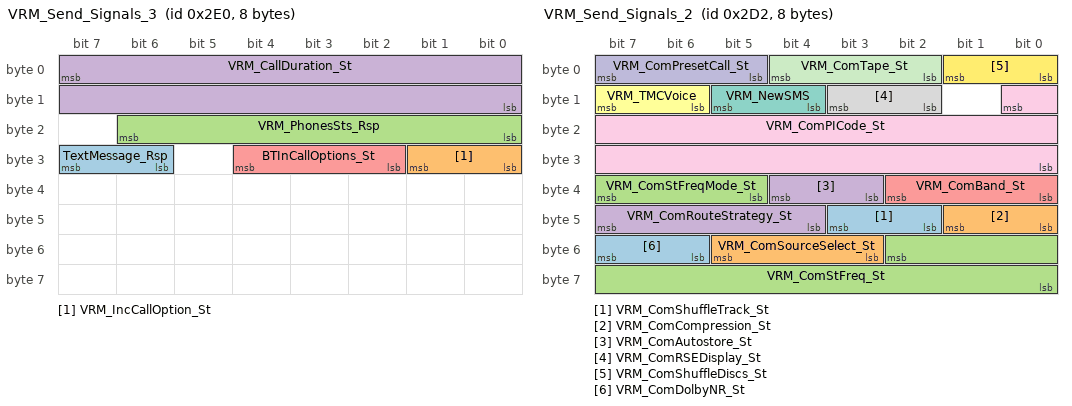
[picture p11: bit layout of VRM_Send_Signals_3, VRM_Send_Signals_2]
BO_ 736 VRM_Send_Signals_3: 8 APIM
 SG_ TextMessage_Rsp : 31|2@0+ (1,0) [0|3] "SED"  IPC,HUD_ADV
 SG_ VRM_IncCallOption_St : 25|2@0+ (1,0) [0|3] "SED"  GENERIC
 SG_ VRM_PhonesSts_Rsp : 22|7@0+ (1,0) [0|127] "unitless"  GENERIC
 SG_ VRM_CallDuration_St : 7|16@0+ (1,0) [0|65534] "second"  IPC
 SG_ BTInCallOptions_St : 28|3@0+ (1,0) [0|7] "SED"  IPC,HUD_ADV

BO_ 722 VRM_Send_Signals_2: 8 APIM
 SG_ VRM_ComShuffleTrack_St : 43|2@0+ (1,0) [0|3] "SED"  GENERIC
 SG_ VRM_ComCompression_St : 41|2@0+ (1,0) [0|3] "SED"  GENERIC
 SG_ VRM_ComStFreqMode_St : 39|3@0+ (1,0) [0|7] "SED"  GENERIC
 SG_ VRM_ComAutostore_St : 36|2@0+ (1,0) [0|3] "SED"  GENERIC
 SG_ VRM_ComBand_St : 34|3@0+ (1,0) [0|7] "SED"  GENERIC
 SG_ VRM_TMCVoice : 15|2@0+ (1,0) [0|3] "SED"  GENERIC
 SG_ VRM_NewSMS : 13|2@0+ (1,0) [0|3] "SED"  IPC,HUD_ADV
 SG_ VRM_ComRSEDisplay_St : 11|2@0+ (1,0) [0|3] "SED"  GENERIC
 SG_ VRM_ComPICode_St : 8|17@0+ (1,0) [0|65535] "unitless"  GENERIC
 SG_ VRM_ComPresetCall_St : 7|3@0+ (1,0) [0|7] "SED"  GENERIC
 SG_ VRM_ComTape_St : 4|3@0+ (1,0) [0|7] "SED"  GENERIC
 SG_ VRM_ComShuffleDiscs_St : 1|2@0+ (1,0) [0|3] "SED"  GENERIC
 SG_ VRM_ComDolbyNR_St : 55|2@0+ (1,0) [0|3] "SED"  GENERIC
 SG_ VRM_ComSourceSelect_St : 53|3@0+ (1,0) [0|7] "SED"  GENERIC
 SG_ VRM_ComStFreq_St : 50|11@0+ (1,0) [0|1557] "unitless"  GENERIC
 SG_ VRM_ComRouteStrategy_St : 47|4@0+ (1,0) [0|15] "SED"  GENERIC

BO_ 721 VRM_Send_Signals_1: 8 APIM
 SG_ VRM_BTDefaultPhone_St : 63|4@0+ (1,0) [0|15] "SED"  IPC
 SG_ VRM_DetourUnit_st : 59|2@0+ (1,0) [0|3] "SED"  GENERIC
 SG_ VRM_Zoom_Option_St : 57|2@0+ (1,0) [0|3] "SED"  GENERIC
 SG_ VRM_ComBTDTMFTone_St : 55|4@0+ (1,0) [0|15] "SED"  GENERIC
 SG_ VRM_SuggestedRoute_St : 51|2@0+ (1,0) [0|3] "SED"  GENERIC
 SG_ VRM_ComDelWaypoint_St : 49|2@0+ (1,0) [0|3] "SED"  GENERIC
 SG_ VRM_ComSelectDisc_St : 47|3@0+ (1,0) [0|7] "SED"  GENERIC
 SG_ VRM_ComTelService_St : 44|3@0+ (1,0) [0|7] "SED"  GENERIC
 SG_ VRM_ComDestHome_St : 41|2@0+ (1,0) [0|3] "SED"  GENERIC
 SG_ VRM_ComSelectTrack_St : 39|7@0+ (1,0) [0|100] "unitless"  GENERIC
 SG_ VRM_ComShowNavInfo_St : 31|3@0+ (1,0) [0|7] "SED"  GENERIC
 SG_ VRM_VoiceRecStatus_St : 28|3@0+ (1,0) [0|7] "SED"  IPC
 SG_ VRM_ComSelTrackSource_St : 25|2@0+ (1,0) [0|3] "SED"  GENERIC
 SG_ VRM_ComDetour_St : 23|4@0+ (1,0) [0|15] "SED"  GENERIC
 SG_ VRM_ComDisplay_St : 19|3@0+ (1,0) [0|7] "SED"  GENERIC
 SG_ VRM_ComDynamicGuidande_St : 15|2@0+ (1,0) [0|3] "SED"  GENERIC
 SG_ VRM_ComZoom_St : 12|5@0+ (1,0) [0|31] "SED"  GENERIC
 SG_ VRM_ComCallControl_St : 7|3@0+ (1,0) [0|7] "SED"  GENERIC
 SG_ VRM_ComGuidance_St : 4|3@0+ (1,0) [0|7] "SED"  GENERIC
 SG_ VRM_ComTrafficInfDsp_St : 1|2@0+ (1,0) [0|3] "SED"  GENERIC

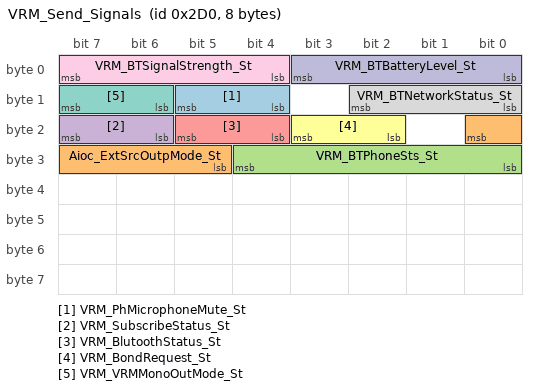
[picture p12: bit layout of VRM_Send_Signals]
BO_ 720 VRM_Send_Signals: 8 APIM
 SG_ VRM_PhMicrophoneMute_St : 13|2@0+ (1,0) [0|3] "SED"  IPC
 SG_ Aioc_ExtSrcOutpMode_St : 16|4@0+ (1,0) [0|15] "SED"  GENERIC
 SG_ VRM_BTPhoneSts_St : 28|5@0+ (1,0) [0|31] "SED"  GWM,HUD_ADV,IPC
 SG_ VRM_SubscribeStatus_St : 23|2@0+ (1,0) [0|3] "SED"  GENERIC
 SG_ VRM_BlutoothStatus_St : 21|2@0+ (1,0) [0|3] "SED"  IPC
 SG_ VRM_BondRequest_St : 19|2@0+ (1,0) [0|3] "SED"  GENERIC
 SG_ VRM_VRMMonoOutMode_St : 15|2@0+ (1,0) [0|3] "SED"  GENERIC
 SG_ VRM_BTNetworkStatus_St : 10|3@0+ (1,0) [0|7] "unitless"  IPC
 SG_ VRM_BTSignalStrength_St : 7|4@0+ (1,0) [0|15] "unitless"  IPC
 SG_ VRM_BTBatteryLevel_St : 3|4@0+ (1,0) [0|15] "unitless"  IPC

BO_ 470 VRM_Response_Signals: 8 APIM
 SG_ VRM_BTIncomingCall_Rsp : 47|2@0+ (1,0) [0|3] "SED"  IPC,HUD_ADV
 SG_ VRM_BTEndTelService_Rsp : 37|2@0+ (1,0) [0|3] "SED"  IPC,HUD_ADV

BO_ 1978 TesterPhysicalResHUD_ADV: 8 HUD_ADV
 SG_ TesterPhysicalResHUD_ADV : 7|64@0+ (1,0) [0|1.84467E+019] "unitless"  TSTR

BO_ 1970 TesterPhysicalReqHUD_ADV: 8 TSTR
 SG_ TesterPhysicalReqHUD_ADV : 7|64@0+ (1,0) [0|1.84467E+019] "unitless"  HUD_ADV

BO_TX_BU_ 816 : APIM_CISM,APIM;
BO_TX_BU_ 1119 : APIM_CISM,APIM;
BO_TX_BU_ 1118 : APIM_CISM,APIM;
BO_TX_BU_ 290 : APIM_CISM,APIM;
BO_TX_BU_ 145 : APIM_CISM,APIM;
BO_TX_BU_ 736 : APIM_CISM,APIM;
BO_TX_BU_ 721 : APIM_CISM,APIM;
BO_TX_BU_ 720 : APIM_CISM,APIM;
BO_TX_BU_ 470 : APIM_CISM,APIM;
CM_ SG_ 629 GearPos_D_Actl "Powersplit HEVs with HF45, HPCM will Tx  this message.  For all other programs it will be Tx by PCM or TCM. ";
CM_ SG_ 629 TrnRng_D_Rq "Powersplit HEVs with HF45, HPCM will Tx  this message.  For all other programs it will be Tx by PCM or TCM. ";
CM_ SG_ 672 BCP_Audible_Beep_Rq "Object.AlertMethod.BCP_Audible_Beep";
CM_ SG_ 672 SetVolume "$0: -30Steps
$1: -29Steps
$2: -28Steps
$1D: -1Step
$1E: NotPressed_Inactive
$1F: +1Step
$20: +2Steps
$21: +3Steps
$3C: +30Steps";
CM_ SG_ 672 SetPointVolume "Method: EFP_Button_Press
0x0:Inactive
$0: Inactive
$1: No_Volume
$2: Volume_Step1
$3: Vol_Step2
$1F: Vol_Step30";
CM_ SG_ 672 Coding_BtnID_D "Object InputControlInterface ICI ButtonCoding_D
Object InputControlInterface ICI ButtonID_D";
CM_ SG_ 672 Coding_BtnID_C "Object InputControlInterface.ICI ButtonCoding_C
Object InputControlInterface.ICI ButtonID_C";
CM_ SG_ 672 Coding_BtnID_B "Object InputControlInterface ICI ButtonCoding_B
Object InputControlInterface.ICI ButtonID_B";
CM_ SG_ 672 Coding_BtnID_A "Object InputControlInterface ICI ButtonCoding_A
Object InputControlInterface.ICI ButtonID A";
CM_ SG_ 672 BtnID_D "Object InputControlInterface ICI ButtonID_D... 0xFF: Inactive";
CM_ SG_ 672 BtnID_C "Object InputControlInterface ICI ButtonID_D... 0xFF: Inactive";
CM_ SG_ 672 BtnID_B "Object InputControlInterface ICI ButtonID_D... 0xFF: Inactive";
CM_ SG_ 672 BtnID_A "Object InputControlInterface ICI ButtonID_D... 0xFF: Inactive";
CM_ BO_ 885 "NOTE: START BITS 8-11 MUST BE OPEN SPEC REQUIREMENT";
CM_ SG_ 1119 LocationServices_2 "Tx by HS3 APIM";
CM_ SG_ 1118 LocationServices_1 "Tx by HS3 APIM";
CM_ SG_ 419 MK_SpeedValue_Rq "Object MyKey.1 SpeedSettingConfig_Rq.SpeedValue (Parameter2)";
CM_ SG_ 419 MK_SpeedSetting_Rq "Object MyKey.1 SpeedSettingConfig_Rq.SpeedSetting (Parameter1)";
CM_ SG_ 419 MK_ResetAllUserKeys_Rq "Object MyKey.ResetAllKeys_Rq";
CM_ SG_ 419 MK_MyKeySystemInfo_Rq "Object MyKey.MyKeySystemInfo_Rq";
CM_ SG_ 419 MK_ESCRestrictConf_Rq "Object MyKey.ESCRestrictionConfig_Rq";
CM_ SG_ 419 MK_ECalRestrictConf_Rq "Object MyKey.ECallRestrictionConfig_Rq";
CM_ SG_ 419 MK_DNDRestrictConf_Rq "Object MyKey.DNDRestrictionConfig_Rq";
CM_ SG_ 419 MK_CreateMyKey_Rq "Object MyKey.CreateMyKey_Rq";
CM_ SG_ 419 MK_AudioLimitConfig_Rq "Object MyKey.AudioLimitConfig_Rq";
CM_ SG_ 419 MK_ACSRestrictConf_Rq "Object MyKey.ACSRestrictionConfig_Rq";
CM_ SG_ 542 LocationServices_3 "Tx by HS3 APIM";
CM_ BO_ 554 "TCU_CPPM Tx";
CM_ SG_ 554 PtWakeupActv1_B_Rq "ECG Application signal";
CM_ SG_ 494 HEC_TUPresetArea_Rq "Object Tuner.GetTUPresetInfo.PresetArea

$5: Get AMAST (MW) Preset Data
$6: Get AM (LW) Preset Data";
CM_ SG_ 494 Mc_SetCurrPreset2_Rq "Object Tuner.SetCurrentPreset2

$1-$1E: Preset 1 to 30
$0: Inactive
";
CM_ SG_ 494 HEC_TUNbrOfPresets_Rq "Object Tuner.GetTUPresetInfo.NumberOfPresets

$1-$1E: Preset 1 to 30";
CM_ SG_ 494 HEC_SetCurrTUBand_Rq "Object Tuner.SetCurrTUBand
$5: AM (LLN, HLN: MW)
$6: AM AST (LLN, HLN: LW)";
CM_ SG_ 494 HEC_TUStartIndex2_Rq "Object Tuner.GetTUPresetInfo.StartIndex2

$1-$FF: Preset 1 to 255";
CM_ SG_ 498 HEC_ARReqstrPriority_Rq "Object Audio Management Audio Client.AudioRequest.Requester Priority";
CM_ SG_ 498 HEC_AROperationType_Rq "Object Audio Management Audio Client.AudioRequest.Operation Type";
CM_ SG_ 498 HEC_ARReqstrSystem_Rq "Object Audio Management Audio Client.AudioRequest.Requester System";
CM_ SG_ 498 HEC_ARAudioSource_Rq "Object Audio Management Audio Client.AudioRequest.Requested Audio Source";
CM_ SG_ 643 GearPos_D_Trg "Powersplit HEVs with HF45, HPCM will Tx  this message.  For all other programs it will be Tx by PCM or TCM. ";
CM_ BO_ 145 "MFD Shall not send this message when configured as a slave

Method: Clock Modes";
CM_ SG_ 145 MFD_Year "Used by MFD to distribute actual Master Clock data to the Slave";
CM_ SG_ 145 MFD_Second "Used by MFD to distribute actual Master Clock data to the Slave";
CM_ SG_ 145 MFD_Month "Used by MFD to distribute actual Master Clock data to the Slave";
CM_ SG_ 145 MFD_Minute "Used by MFD to distribute actual Master Clock data to the Slave";
CM_ SG_ 145 MFD_Hour "Used by MFD to distribute actual Master Clock data to the Slave";
CM_ SG_ 145 MFD_Day "Used by MFD to distribute actual Master Clock data to the Slave";
CM_ SG_ 545 SurndSndUpmix2_D_Stat "Object:Surround_Sound_Upmix2_St";
CM_ SG_ 545 SndImmrsnLvl_D_Stat "ImmersionLevel_D_St";
CM_ SG_ 545 DSP_Sur_Sound_st "Method DSP_Sur_Sound_Upmix.St";
CM_ SG_ 545 DSP_MyKeyVolLimitUp_St "Method MykeyvolumeIsLimited";
CM_ SG_ 545 DSP_MyKeyVolLim_St "Method MykeyvolumeIsLimited";
CM_ SG_ 545 DSP_BeltminderAudio_St "Object.MyKey.BeltminderAudioIsMuted";
CM_ SG_ 545 DSP_Audio_Volume_Up_St "Object.VolumeControl.DSP_Audio_Vol_updated
";
CM_ SG_ 545 DSP_Audio_Vol_Level_St "Object.VolumeControl.DSP_Audio_Vol_Level.St

0x0 No Volume
0x1 Vol_Step1
0x2 Vol_Step2
0x3 Vol_Step3
Cont.
0x1E Vol_Step30";
CM_ SG_ 545 AudioOccMde_D_Stat "Object: Occupancy_Mode.St";
CM_ BO_ 74 "Reserve eCallNotification message";
CM_ SG_ 736 TextMessage_Rsp "Object.BTPhoneServer.TextMessage.Rsp.ResponseCode";
CM_ SG_ 736 VRM_IncCallOption_St "Object Bluetooth Phone.IncCallOption";
CM_ SG_ 736 VRM_PhonesSts_Rsp "Object Bluetooth Phone

Bit 0:  0: invalid, 1: valid
Bit 1: 
0:  Phone on index 1 not  connectable.
1: Phone on index 1 connectable.
.......
Bit 6: 
0:  Phone on index 6 not  connectable.
1: Phone on index 6 connectable.";
CM_ SG_ 736 VRM_CallDuration_St "Object Bluetooth Phone.CallDuration";
CM_ SG_ 736 BTInCallOptions_St "Object.BTPhoneServer.BTInCallOptions.Rsp.Result";
CM_ SG_ 722 VRM_ComShuffleTrack_St "Object Voice Recogniser.ComShuffleTrack";
CM_ SG_ 722 VRM_ComCompression_St "Object Voice Recogniser.ComCompression";
CM_ SG_ 722 VRM_ComStFreqMode_St "Object Voice Recogniser.ComFrequency(Parameter1)
Object Voice Recogniser.ComStation";
CM_ SG_ 722 VRM_ComAutostore_St "Object Voice Recogniser.ComAutostore";
CM_ SG_ 722 VRM_ComBand_St "Object Voice Recogniser.ComBand";
CM_ SG_ 722 VRM_TMCVoice "Object Voice Recogniser.TMC Voice";
CM_ SG_ 722 VRM_NewSMS "Object Bluetooth Phone";
CM_ SG_ 722 VRM_ComRSEDisplay_St "Object Voice Recogniser.ComRSEDisplay
NOT USED";
CM_ SG_ 722 VRM_ComPICode_St "Object Voice Recogniser.ComStation(PI Code)
(Parameter1)

16 bit hex coded PI Code";
CM_ SG_ 722 VRM_ComPresetCall_St "Object Voice Recogniser.ComPresetCall
NOT USED";
CM_ SG_ 722 VRM_ComTape_St "Object Voice Recogniser.ComTape
NOT USED";
CM_ SG_ 722 VRM_ComShuffleDiscs_St "Object Voice Recogniser.ComShuffleDiscs
NOT USED";
CM_ SG_ 722 VRM_ComDolbyNR_St "Object Voice Recogniser.ComDolbyNr
NOT USED";
CM_ SG_ 722 VRM_ComSourceSelect_St "Object Voice Recogniser.ComSourceSelect";
CM_ SG_ 722 VRM_ComStFreq_St "Object Voice Recogniser.ComFrequency(Parameter2)
Object Voice Recogniser.ComStation(Parameter2)

AM: Freq = 153+ Offset kHz. Offset 0..1557
FM: Freq = 76+ Offset*0.05 MHz. Offset 0..640
Selected tuned band determine frequency (kHz or MHz).
";
CM_ SG_ 722 VRM_ComRouteStrategy_St "Object Voice Recogniser.ComRouteStrategy";
CM_ SG_ 721 VRM_BTDefaultPhone_St "Object Voice Recogniser.BTDefaultPhone";
CM_ SG_ 721 VRM_DetourUnit_st "Object Voice Recogniser.DetourUnit";
CM_ SG_ 721 VRM_Zoom_Option_St "Object Voice Recogniser.ComZoom";
CM_ SG_ 721 VRM_ComBTDTMFTone_St "Object Voice Recogniser.ComBTDTMFTone";
CM_ SG_ 721 VRM_SuggestedRoute_St "Object Voice Recogniser.ComSuggestedRoute
NOT USED";
CM_ SG_ 721 VRM_ComDelWaypoint_St "Object Voice Recogniser.ComDelWaypoint";
CM_ SG_ 721 VRM_ComSelectDisc_St "Object Voice Recogniser.ComSelectDisc";
CM_ SG_ 721 VRM_ComTelService_St "Object Voice Recogniser.ComTelematicsService
NOT USED";
CM_ SG_ 721 VRM_ComDestHome_St "Object Voice Recogniser.ComDestHome";
CM_ SG_ 721 VRM_ComSelectTrack_St "Object Voice Recogniser.ComSelectTrack

$01: Command has not been issued";
CM_ SG_ 721 VRM_ComShowNavInfo_St "Object Voice Recogniser.ComShowNavInfo";
CM_ SG_ 721 VRM_VoiceRecStatus_St "Object VoiceRecognizer.VoiceRecStatus";
CM_ SG_ 721 VRM_ComSelTrackSource_St "Object Voice Recogniser.ComSelectTrack, parameter Source";
CM_ SG_ 721 VRM_ComDetour_St "Object Voice Recogniser.ComDetour";
CM_ SG_ 721 VRM_ComDisplay_St "Object Voice Recogniser.ComDisplay";
CM_ SG_ 721 VRM_ComDynamicGuidande_St "Object Voice Recogniser.DynamicRouteGuidance";
CM_ SG_ 721 VRM_ComZoom_St "Object Voice Recogniser.ComZoom";
CM_ SG_ 721 VRM_ComCallControl_St "Object Voice Recogniser.ComCallControl
NOT USED";
CM_ SG_ 721 VRM_ComGuidance_St "Object Voice Recogniser.ComGuidance";
CM_ SG_ 721 VRM_ComTrafficInfDsp_St "Object Voice Recogniser.ComTrafficInformation";
CM_ SG_ 720 VRM_PhMicrophoneMute_St "Object Bluetooth Phone.PhMicrophoneMute";
CM_ SG_ 720 Aioc_ExtSrcOutpMode_St "Object Audio Management Audio Switch.BVCOutputMode";
CM_ SG_ 720 VRM_BTPhoneSts_St "Object Bluetooth Phone.BTPhoneSts";
CM_ SG_ 720 VRM_SubscribeStatus_St "Object Bluetooth Phone";
CM_ SG_ 720 VRM_BlutoothStatus_St "Object Bluetooth Phone (Spelled as BluetoothStatus in OS)";
CM_ SG_ 720 VRM_BondRequest_St "Object Bluetooth Phone";
CM_ SG_ 720 VRM_VRMMonoOutMode_St "Object VRMAudioIOController.VRMMonoOutMode";
CM_ SG_ 720 VRM_BTNetworkStatus_St "Object Bluetooth Phone.BTNetworkStatus";
CM_ SG_ 720 VRM_BTSignalStrength_St "Object Bluetooth Phone.BTSignalStrength";
CM_ SG_ 720 VRM_BTBatteryLevel_St "Object Bluetooth Phone.BTBatteryLevel";
BA_DEF_ BO_  "FrameRouting" STRING ;
BA_DEF_ BO_  "FrameGatewayNetwork" STRING ;
BA_DEF_ BO_  "NetworkInitialization" ENUM  "No","Yes";
BA_DEF_ BO_  "FrameGatewayId" HEX 0 1407;
BA_DEF_ BO_  "EventRateOfChange" INT 10 10000;
BA_DEF_ BO_  "GenMsgStartDelayTime" INT 0 10000;
BA_DEF_ BO_  "GenMsgNrOfRepetition" INT 0 100;
BA_DEF_ BO_  "GenMsgDelayTime" INT 0 1000;
BA_DEF_ BO_  "GenMsgCycleTime" INT 0 100000;
BA_DEF_ BO_  "GenMsgSendType" ENUM  "FixedPeriodic","Event","EnabledPeriodic","NotUsed","NotUsed","EventPeriodic","NotUsed","NotUsed","NoMsgSendType";
BA_DEF_ SG_  "U_CD764_MY2022_Tx" ENUM  "No","Yes";
BA_DEF_ SG_  "U_U55X_MY2022_Tx" ENUM  "No","Yes";
BA_DEF_ SG_  "U_CD542_MY2021_Tx" ENUM  "No","Yes";
BA_DEF_ SG_  "ECGUsedTxSignal" ENUM  "No","Yes";
BA_DEF_ SG_  "U_T6_MCA_MY2020_Tx" ENUM  "No","Yes";
BA_DEF_ SG_  "U_P702_MY2021_Tx" ENUM  "No","Yes";
BA_DEF_ SG_  "U_CX727_MY2021_Tx" ENUM  "No","Yes";
BA_DEF_ SG_  "U_CD764_MY2022_Rx" ENUM  "No","Yes";
BA_DEF_ SG_  "U_FNV2_IVI_Rx" ENUM  "No","Yes";
BA_DEF_ SG_  "U_U55X_MY2022_Rx" ENUM  "No","Yes";
BA_DEF_ SG_  "U_CD542_MY2021_Rx" ENUM  "No","Yes";
BA_DEF_ SG_  "ECGUsedRxSignal" ENUM  "No","Yes";
BA_DEF_ SG_  "U_T6_MCA_MY2020_Rx" ENUM  "No","Yes";
BA_DEF_ SG_  "U_P702_MY2021_Rx" ENUM  "No","Yes";
BA_DEF_ SG_  "U_CX727_MY2021_Rx" ENUM  "No","Yes";
BA_DEF_ SG_  "GenSigStartValue" HEX 0 268435455;
BA_DEF_ SG_  "MetaData" ENUM  "No","Yes";
BA_DEF_ SG_  "ContentDependant" ENUM  "No","Yes";
BA_DEF_ SG_  "GenSigStartValueInteger" INT 0 1000000000;
BA_DEF_ SG_  "UsedOnPgmDBC" ENUM  "No","Yes";
BA_DEF_ SG_  "WakeupSignal" ENUM  "No","Yes";
BA_DEF_ SG_  "GenSigInactiveValue" INT 0 100000;
BA_DEF_ SG_  "GenSigSendType" ENUM  "Cyclic","OnWrite","vector_leerstring","OnChange","vector_leerstring","IfActive","vector_leerstring","NoSigSendType";
BA_DEF_ BO_  "OvtpPushApplication" ENUM  "FALSE","TRUE";
BA_DEF_ BO_  "SCP_FreshnessValueLength" INT 0 512;
BA_DEF_ BO_  "SCP_FreshnessValueTxLength" INT 0 512;
BA_DEF_ BO_  "SCP_AuthInfoTxLength" INT 0 512;
BA_DEF_ BO_  "GenMsgRoutingTimeoutTime" INT 0 5000;
BA_DEF_ BO_  "MessageGateway" ENUM  "No","Yes";
BA_DEF_ BO_  "NmAsrMessage" ENUM  "No","Yes";
BA_DEF_ BO_  "DiagState" ENUM  "No","Yes";
BA_DEF_ BO_  "TpTxIndex" INT 0 536870911;
BA_DEF_ BO_  "DiagRequest" ENUM  "No","Yes";
BA_DEF_ BO_  "DiagResponse" ENUM  "No","Yes";
BA_DEF_ BO_  "GenMsgILSupport" ENUM  "No","Yes";
BA_DEF_DEF_  "FrameRouting" "";
BA_DEF_DEF_  "FrameGatewayNetwork" "NONE";
BA_DEF_DEF_  "NetworkInitialization" "Yes";
BA_DEF_DEF_  "FrameGatewayId" 0;
BA_DEF_DEF_  "EventRateOfChange" 10000;
BA_DEF_DEF_  "GenMsgStartDelayTime" 0;
BA_DEF_DEF_  "GenMsgNrOfRepetition" 1;
BA_DEF_DEF_  "GenMsgDelayTime" 20;
BA_DEF_DEF_  "GenMsgCycleTime" 0;
BA_DEF_DEF_  "GenMsgSendType" "NoMsgSendType";
BA_DEF_DEF_  "U_CD764_MY2022_Tx" "No";
BA_DEF_DEF_  "U_U55X_MY2022_Tx" "No";
BA_DEF_DEF_  "U_CD542_MY2021_Tx" "No";
BA_DEF_DEF_  "ECGUsedTxSignal" "No";
BA_DEF_DEF_  "U_T6_MCA_MY2020_Tx" "No";
BA_DEF_DEF_  "U_P702_MY2021_Tx" "No";
BA_DEF_DEF_  "U_CX727_MY2021_Tx" "No";
BA_DEF_DEF_  "U_CD764_MY2022_Rx" "No";
BA_DEF_DEF_  "U_FNV2_IVI_Rx" "No";
BA_DEF_DEF_  "U_U55X_MY2022_Rx" "No";
BA_DEF_DEF_  "U_CD542_MY2021_Rx" "No";
BA_DEF_DEF_  "ECGUsedRxSignal" "No";
BA_DEF_DEF_  "U_T6_MCA_MY2020_Rx" "No";
BA_DEF_DEF_  "U_P702_MY2021_Rx" "No";
BA_DEF_DEF_  "U_CX727_MY2021_Rx" "No";
BA_DEF_DEF_  "GenSigStartValue" 0;
BA_DEF_DEF_  "MetaData" "No";
BA_DEF_DEF_  "ContentDependant" "No";
BA_DEF_DEF_  "GenSigStartValueInteger" 0;
BA_DEF_DEF_  "UsedOnPgmDBC" "Yes";
BA_DEF_DEF_  "WakeupSignal" "No";
BA_DEF_DEF_  "GenSigInactiveValue" 0;
BA_DEF_DEF_  "GenSigSendType" "NoSigSendType";
BA_DEF_DEF_  "OvtpPushApplication" "FALSE";
BA_DEF_DEF_  "SCP_FreshnessValueLength" 64;
BA_DEF_DEF_  "SCP_FreshnessValueTxLength" 11;
BA_DEF_DEF_  "SCP_AuthInfoTxLength" 53;
BA_DEF_DEF_  "GenMsgRoutingTimeoutTime" 0;
BA_DEF_DEF_  "MessageGateway" "No";
BA_DEF_DEF_  "NmAsrMessage" "No";
BA_DEF_DEF_  "DiagState" "No";
BA_DEF_DEF_  "TpTxIndex" 0;
BA_DEF_DEF_  "DiagRequest" "No";
BA_DEF_DEF_  "DiagResponse" "No";
BA_DEF_DEF_  "GenMsgILSupport" "Yes";
BA_ "GenMsgSendType" BO_ 629 5;
BA_ "GenMsgCycleTime" BO_ 629 1000;
BA_ "GenMsgSendType" BO_ 672 5;
BA_ "GenMsgCycleTime" BO_ 672 1000;
BA_ "GenMsgStartDelayTime" BO_ 672 150;
BA_ "GenMsgILSupport" BO_ 1829 0;
BA_ "DiagRequest" BO_ 1829 1;
BA_ "GenMsgSendType" BO_ 1829 1;
BA_ "GenMsgDelayTime" BO_ 1829 0;
BA_ "NetworkInitialization" BO_ 1829 0;
BA_ "TpTxIndex" BO_ 601 58;
BA_ "NetworkInitialization" BO_ 601 0;
BA_ "TpTxIndex" BO_ 593 58;
BA_ "GenMsgSendType" BO_ 816 5;
BA_ "GenMsgCycleTime" BO_ 816 1000;
BA_ "FrameGatewayId" BO_ 636 636;
BA_ "FrameGatewayNetwork" BO_ 636 "HS4_CAN";
BA_ "FrameRouting" BO_ 636 "HS4_CAN,0x27C";
BA_ "GenMsgSendType" BO_ 807 5;
BA_ "GenMsgCycleTime" BO_ 807 1000;
BA_ "FrameGatewayId" BO_ 974 878;
BA_ "FrameGatewayNetwork" BO_ 974 "FD1_CAN";
BA_ "FrameRouting" BO_ 974 "FD1_CAN,0x36E;";
BA_ "GenMsgSendType" BO_ 805 0;
BA_ "GenMsgCycleTime" BO_ 805 100;
BA_ "GenMsgSendType" BO_ 804 5;
BA_ "GenMsgCycleTime" BO_ 804 1000;
BA_ "GenMsgSendType" BO_ 803 5;
BA_ "GenMsgCycleTime" BO_ 803 1000;
BA_ "GenMsgSendType" BO_ 802 5;
BA_ "GenMsgCycleTime" BO_ 802 1000;
BA_ "GenMsgSendType" BO_ 812 5;
BA_ "GenMsgCycleTime" BO_ 812 1000;
BA_ "GenMsgSendType" BO_ 885 0;
BA_ "GenMsgCycleTime" BO_ 885 200;
BA_ "GenMsgSendType" BO_ 1119 1;
BA_ "GenMsgSendType" BO_ 1118 1;
BA_ "GenMsgSendType" BO_ 290 1;
BA_ "TpTxIndex" BO_ 2612101336 464617688;
BA_ "OvtpPushApplication" BO_ 2612101336 1;
BA_ "GenMsgSendType" BO_ 2612101336 1;
BA_ "GenMsgDelayTime" BO_ 2612101336 0;
BA_ "NetworkInitialization" BO_ 2612101336 0;
BA_ "GenMsgSendType" BO_ 639 5;
BA_ "GenMsgCycleTime" BO_ 639 1000;
BA_ "GenMsgSendType" BO_ 419 1;
BA_ "FrameGatewayId" BO_ 542 542;
BA_ "FrameGatewayNetwork" BO_ 542 "HS4_CAN";
BA_ "FrameRouting" BO_ 542 "HS4_CAN,0x21E;";
BA_ "GenMsgSendType" BO_ 554 5;
BA_ "GenMsgCycleTime" BO_ 554 1000;
BA_ "GenMsgSendType" BO_ 494 1;
BA_ "NetworkInitialization" BO_ 494 0;
BA_ "GenMsgSendType" BO_ 498 1;
BA_ "NetworkInitialization" BO_ 498 0;
BA_ "GenMsgSendType" BO_ 644 0;
BA_ "GenMsgCycleTime" BO_ 644 100;
BA_ "GenMsgSendType" BO_ 643 5;
BA_ "GenMsgCycleTime" BO_ 643 1000;
BA_ "GenMsgSendType" BO_ 145 1;
BA_ "FrameGatewayId" BO_ 841 841;
BA_ "FrameGatewayNetwork" BO_ 841 "MS1_CAN";
BA_ "FrameRouting" BO_ 841 "MS1_CAN,0x349;";
BA_ "GenMsgSendType" BO_ 545 5;
BA_ "GenMsgCycleTime" BO_ 545 1000;
BA_ "GenMsgSendType" BO_ 1058 0;
BA_ "GenMsgCycleTime" BO_ 1058 1000;
BA_ "GenMsgSendType" BO_ 633 5;
BA_ "GenMsgCycleTime" BO_ 633 1000;
BA_ "MessageGateway" BO_ 936 1;
BA_ "GenMsgRoutingTimeoutTime" BO_ 936 60;
BA_ "GenMsgSendType" BO_ 936 5;
BA_ "GenMsgCycleTime" BO_ 936 1000;
BA_ "MessageGateway" BO_ 75 1;
BA_ "GenMsgRoutingTimeoutTime" BO_ 75 300;
BA_ "GenMsgSendType" BO_ 75 5;
BA_ "GenMsgCycleTime" BO_ 75 1000;
BA_ "MessageGateway" BO_ 74 1;
BA_ "GenMsgRoutingTimeoutTime" BO_ 74 300;
BA_ "GenMsgSendType" BO_ 74 5;
BA_ "GenMsgCycleTime" BO_ 74 1000;
BA_ "FrameGatewayId" BO_ 638 638;
BA_ "FrameGatewayNetwork" BO_ 638 "HS4_CAN";
BA_ "FrameRouting" BO_ 638 "HS4_CAN,0x27E";
BA_ "GenMsgSendType" BO_ 555 5;
BA_ "GenMsgCycleTime" BO_ 555 1000;
BA_ "FrameGatewayId" BO_ 124 119;
BA_ "FrameGatewayNetwork" BO_ 124 "FD1_CAN";
BA_ "FrameRouting" BO_ 124 "FD1_CAN,0x77;";
BA_ "GenMsgSendType" BO_ 736 5;
BA_ "GenMsgCycleTime" BO_ 736 1000;
BA_ "GenMsgSendType" BO_ 722 5;
BA_ "GenMsgCycleTime" BO_ 722 1000;
BA_ "GenMsgSendType" BO_ 721 5;
BA_ "GenMsgCycleTime" BO_ 721 1000;
BA_ "GenMsgSendType" BO_ 720 5;
BA_ "GenMsgCycleTime" BO_ 720 1000;
BA_ "GenMsgSendType" BO_ 470 1;
BA_ "GenMsgILSupport" BO_ 1978 0;
BA_ "DiagResponse" BO_ 1978 1;
BA_ "GenMsgSendType" BO_ 1978 1;
BA_ "GenMsgDelayTime" BO_ 1978 0;
BA_ "NetworkInitialization" BO_ 1978 0;
BA_ "GenMsgILSupport" BO_ 1970 0;
BA_ "DiagRequest" BO_ 1970 1;
BA_ "GenMsgSendType" BO_ 1970 1;
BA_ "GenMsgDelayTime" BO_ 1970 0;
BA_ "NetworkInitialization" BO_ 1970 0;
BA_ "U_T6_MCA_MY2020_Rx" SG_ 629 GearPos_D_Actl_UB 1;
BA_ "U_U55X_MY2022_Rx" SG_ 629 GearPos_D_Actl_UB 1;
BA_ "GenSigStartValueInteger" SG_ 629 GearPos_D_Actl 15;
BA_ "ContentDependant" SG_ 629 GearPos_D_Actl 1;
BA_ "GenSigStartValue" SG_ 629 GearPos_D_Actl 15;
BA_ "GenSigSendType" SG_ 629 GearPos_D_Actl 3;
BA_ "U_T6_MCA_MY2020_Rx" SG_ 629 GearPos_D_Actl 1;
BA_ "U_U55X_MY2022_Rx" SG_ 629 GearPos_D_Actl 1;
BA_ "U_CD542_MY2021_Rx" SG_ 629 BattTrac2_E_Max_UB 1;
BA_ "U_U55X_MY2022_Rx" SG_ 629 BattTrac2_E_Max_UB 1;
BA_ "U_CD764_MY2022_Rx" SG_ 629 BattTrac2_E_Max_UB 1;
BA_ "U_CD542_MY2021_Rx" SG_ 629 BattTrac2_E_Avail_UB 1;
BA_ "U_U55X_MY2022_Rx" SG_ 629 BattTrac2_E_Avail_UB 1;
BA_ "U_CD764_MY2022_Rx" SG_ 629 BattTrac2_E_Avail_UB 1;
BA_ "GenSigStartValueInteger" SG_ 629 BattTrac2_E_Max 4094;
BA_ "GenSigStartValue" SG_ 629 BattTrac2_E_Max 4094;
BA_ "U_CD542_MY2021_Rx" SG_ 629 BattTrac2_E_Max 1;
BA_ "U_U55X_MY2022_Rx" SG_ 629 BattTrac2_E_Max 1;
BA_ "U_CD764_MY2022_Rx" SG_ 629 BattTrac2_E_Max 1;
BA_ "U_CD542_MY2021_Rx" SG_ 629 BattTrac2_E_Avail 1;
BA_ "U_U55X_MY2022_Rx" SG_ 629 BattTrac2_E_Avail 1;
BA_ "U_CD764_MY2022_Rx" SG_ 629 BattTrac2_E_Avail 1;
BA_ "U_T6_MCA_MY2020_Rx" SG_ 629 BattULoChrgHyb_D_Stat_UB 1;
BA_ "U_CD542_MY2021_Rx" SG_ 629 TrnRng_D_Rq_UB 1;
BA_ "U_T6_MCA_MY2020_Rx" SG_ 629 TrnRng_D_Rq_UB 1;
BA_ "U_U55X_MY2022_Rx" SG_ 629 TrnRng_D_Rq_UB 1;
BA_ "GenSigStartValueInteger" SG_ 629 TrnRng_D_Rq 14;
BA_ "ContentDependant" SG_ 629 TrnRng_D_Rq 1;
BA_ "GenSigStartValue" SG_ 629 TrnRng_D_Rq 14;
BA_ "GenSigSendType" SG_ 629 TrnRng_D_Rq 3;
BA_ "U_CD542_MY2021_Rx" SG_ 629 TrnRng_D_Rq 1;
BA_ "U_T6_MCA_MY2020_Rx" SG_ 629 TrnRng_D_Rq 1;
BA_ "U_U55X_MY2022_Rx" SG_ 629 TrnRng_D_Rq 1;
BA_ "GenSigSendType" SG_ 629 BattULoChrgHyb_D_Stat 3;
BA_ "U_T6_MCA_MY2020_Rx" SG_ 629 BattULoChrgHyb_D_Stat 1;
BA_ "U_CD542_MY2021_Rx" SG_ 629 BattULoChrgHyb_D_Stat 1;
BA_ "U_CD542_MY2021_Rx" SG_ 629 BattTracHazrd_D_Stat_UB 1;
BA_ "GenSigSendType" SG_ 629 BattTracHazrd_D_Stat 3;
BA_ "U_CD542_MY2021_Rx" SG_ 629 BattTracHazrd_D_Stat 1;
BA_ "U_CD764_MY2022_Rx" SG_ 672 BCP_Audible_Beep_Rq 1;
BA_ "U_U55X_MY2022_Rx" SG_ 672 BCP_Audible_Beep_Rq 1;
BA_ "WakeupSignal" SG_ 672 SetVolume 1;
BA_ "GenSigStartValueInteger" SG_ 672 SetVolume 30;
BA_ "GenSigStartValue" SG_ 672 SetVolume 30;
BA_ "GenSigSendType" SG_ 672 SetVolume 3;
BA_ "U_T6_MCA_MY2020_Rx" SG_ 672 SetVolume 1;
BA_ "U_U55X_MY2022_Rx" SG_ 672 SetVolume 1;
BA_ "U_CD764_MY2022_Rx" SG_ 672 SetVolume 1;
BA_ "WakeupSignal" SG_ 672 SetPointVolume 1;
BA_ "GenSigSendType" SG_ 672 SetPointVolume 3;
BA_ "U_T6_MCA_MY2020_Rx" SG_ 672 SetPointVolume 1;
BA_ "U_U55X_MY2022_Rx" SG_ 672 SetPointVolume 1;
BA_ "U_CD764_MY2022_Rx" SG_ 672 SetPointVolume 1;
BA_ "WakeupSignal" SG_ 672 Coding_BtnID_D 1;
BA_ "GenSigSendType" SG_ 672 Coding_BtnID_D 3;
BA_ "U_T6_MCA_MY2020_Rx" SG_ 672 Coding_BtnID_D 1;
BA_ "U_U55X_MY2022_Rx" SG_ 672 Coding_BtnID_D 1;
BA_ "U_CD542_MY2021_Rx" SG_ 672 Coding_BtnID_D 1;
BA_ "U_CD764_MY2022_Rx" SG_ 672 Coding_BtnID_D 1;
BA_ "WakeupSignal" SG_ 672 Coding_BtnID_C 1;
BA_ "GenSigSendType" SG_ 672 Coding_BtnID_C 3;
BA_ "U_T6_MCA_MY2020_Rx" SG_ 672 Coding_BtnID_C 1;
BA_ "U_U55X_MY2022_Rx" SG_ 672 Coding_BtnID_C 1;
BA_ "U_CD542_MY2021_Rx" SG_ 672 Coding_BtnID_C 1;
BA_ "U_CD764_MY2022_Rx" SG_ 672 Coding_BtnID_C 1;
BA_ "WakeupSignal" SG_ 672 Coding_BtnID_B 1;
BA_ "GenSigSendType" SG_ 672 Coding_BtnID_B 3;
BA_ "U_T6_MCA_MY2020_Rx" SG_ 672 Coding_BtnID_B 1;
BA_ "U_U55X_MY2022_Rx" SG_ 672 Coding_BtnID_B 1;
BA_ "U_CD542_MY2021_Rx" SG_ 672 Coding_BtnID_B 1;
BA_ "U_CD764_MY2022_Rx" SG_ 672 Coding_BtnID_B 1;
BA_ "WakeupSignal" SG_ 672 Coding_BtnID_A 1;
BA_ "GenSigSendType" SG_ 672 Coding_BtnID_A 3;
BA_ "U_T6_MCA_MY2020_Rx" SG_ 672 Coding_BtnID_A 1;
BA_ "U_U55X_MY2022_Rx" SG_ 672 Coding_BtnID_A 1;
BA_ "U_CD542_MY2021_Rx" SG_ 672 Coding_BtnID_A 1;
BA_ "U_CD764_MY2022_Rx" SG_ 672 Coding_BtnID_A 1;
BA_ "WakeupSignal" SG_ 672 BtnID_D 1;
BA_ "GenSigStartValueInteger" SG_ 672 BtnID_D 255;
BA_ "GenSigStartValue" SG_ 672 BtnID_D 255;
BA_ "U_T6_MCA_MY2020_Rx" SG_ 672 BtnID_D 1;
BA_ "U_U55X_MY2022_Rx" SG_ 672 BtnID_D 1;
BA_ "U_CD542_MY2021_Rx" SG_ 672 BtnID_D 1;
BA_ "U_CD764_MY2022_Rx" SG_ 672 BtnID_D 1;
BA_ "WakeupSignal" SG_ 672 BtnID_C 1;
BA_ "GenSigStartValueInteger" SG_ 672 BtnID_C 255;
BA_ "GenSigStartValue" SG_ 672 BtnID_C 255;
BA_ "U_T6_MCA_MY2020_Rx" SG_ 672 BtnID_C 1;
BA_ "U_U55X_MY2022_Rx" SG_ 672 BtnID_C 1;
BA_ "U_CD542_MY2021_Rx" SG_ 672 BtnID_C 1;
BA_ "U_CD764_MY2022_Rx" SG_ 672 BtnID_C 1;
BA_ "WakeupSignal" SG_ 672 BtnID_B 1;
BA_ "GenSigStartValueInteger" SG_ 672 BtnID_B 255;
BA_ "GenSigStartValue" SG_ 672 BtnID_B 255;
BA_ "U_T6_MCA_MY2020_Rx" SG_ 672 BtnID_B 1;
BA_ "U_U55X_MY2022_Rx" SG_ 672 BtnID_B 1;
BA_ "U_CD542_MY2021_Rx" SG_ 672 BtnID_B 1;
BA_ "U_CD764_MY2022_Rx" SG_ 672 BtnID_B 1;
BA_ "WakeupSignal" SG_ 672 BtnID_A 1;
BA_ "GenSigStartValueInteger" SG_ 672 BtnID_A 255;
BA_ "GenSigStartValue" SG_ 672 BtnID_A 255;
BA_ "U_T6_MCA_MY2020_Rx" SG_ 672 BtnID_A 1;
BA_ "U_U55X_MY2022_Rx" SG_ 672 BtnID_A 1;
BA_ "U_CD542_MY2021_Rx" SG_ 672 BtnID_A 1;
BA_ "U_CD764_MY2022_Rx" SG_ 672 BtnID_A 1;
BA_ "GenSigSendType" SG_ 1829 TesterPhysicalReqWCM 3;
BA_ "U_CX727_MY2021_Rx" SG_ 1829 TesterPhysicalReqWCM 1;
BA_ "U_P702_MY2021_Rx" SG_ 1829 TesterPhysicalReqWCM 1;
BA_ "U_T6_MCA_MY2020_Rx" SG_ 1829 TesterPhysicalReqWCM 1;
BA_ "U_CD542_MY2021_Rx" SG_ 1829 TesterPhysicalReqWCM 1;
BA_ "U_U55X_MY2022_Rx" SG_ 1829 TesterPhysicalReqWCM 1;
BA_ "U_CD764_MY2022_Rx" SG_ 1829 TesterPhysicalReqWCM 1;
BA_ "U_T6_MCA_MY2020_Rx" SG_ 601 ECG_MC_WORD_Rx 1;
BA_ "ECGUsedRxSignal" SG_ 601 ECG_MC_WORD_Rx 1;
BA_ "U_CD542_MY2021_Rx" SG_ 601 ECG_MC_WORD_Rx 1;
BA_ "U_U55X_MY2022_Rx" SG_ 601 ECG_MC_WORD_Rx 1;
BA_ "U_CD764_MY2022_Rx" SG_ 601 ECG_MC_WORD_Rx 1;
BA_ "U_T6_MCA_MY2020_Tx" SG_ 601 ECG_MC_WORD_Rx 1;
BA_ "U_CD764_MY2022_Tx" SG_ 601 ECG_MC_WORD_Rx 1;
BA_ "U_T6_MCA_MY2020_Rx" SG_ 593 ECG_MC_WORD_Tx 1;
BA_ "U_CD542_MY2021_Rx" SG_ 593 ECG_MC_WORD_Tx 1;
BA_ "U_CD764_MY2022_Rx" SG_ 593 ECG_MC_WORD_Tx 1;
BA_ "U_T6_MCA_MY2020_Tx" SG_ 593 ECG_MC_WORD_Tx 1;
BA_ "ECGUsedTxSignal" SG_ 593 ECG_MC_WORD_Tx 1;
BA_ "U_CD542_MY2021_Tx" SG_ 593 ECG_MC_WORD_Tx 1;
BA_ "U_U55X_MY2022_Tx" SG_ 593 ECG_MC_WORD_Tx 1;
BA_ "U_CD764_MY2022_Tx" SG_ 593 ECG_MC_WORD_Tx 1;
BA_ "GenSigSendType" SG_ 816 Dimming_Lvl_RqMnu 3;
BA_ "GenSigStartValue" SG_ 816 Dimming_Lvl_RqMnu 1;
BA_ "GenSigSendType" SG_ 816 DcacZone3Pw_D_Rq 3;
BA_ "GenSigSendType" SG_ 816 DcacZone2Pw_D_Rq 3;
BA_ "GenSigSendType" SG_ 816 DcacPwScnd_D_Rq 3;
BA_ "GenSigSendType" SG_ 816 DcacPwResetScnd_B_Rq 3;
BA_ "GenSigSendType" SG_ 816 DcacLoFuelLim_L_RqMnu 3;
BA_ "GenSigStartValue" SG_ 816 DcacLoFuelLim_L_RqMnu 510;
BA_ "ECGUsedRxSignal" SG_ 816 DcacLoFuelLim_L_RqMnu 1;
BA_ "GenSigSendType" SG_ 816 DcacAllZone_D_Rq 3;
BA_ "GenSigSendType" SG_ 816 KeylessIdl_D_Rq 3;
BA_ "U_T6_MCA_MY2020_Tx" SG_ 816 KeylessIdl_D_Rq 1;
BA_ "U_CD542_MY2021_Tx" SG_ 816 KeylessIdl_D_Rq 1;
BA_ "U_U55X_MY2022_Tx" SG_ 816 KeylessIdl_D_Rq 1;
BA_ "WakeupSignal" SG_ 816 KeyPadCodeDgt7_D_Stat 1;
BA_ "GenSigSendType" SG_ 816 KeyPadCodeDgt7_D_Stat 3;
BA_ "U_T6_MCA_MY2020_Tx" SG_ 816 KeyPadCodeDgt7_D_Stat 1;
BA_ "U_CD542_MY2021_Tx" SG_ 816 KeyPadCodeDgt7_D_Stat 1;
BA_ "U_U55X_MY2022_Tx" SG_ 816 KeyPadCodeDgt7_D_Stat 1;
BA_ "U_CD764_MY2022_Tx" SG_ 816 KeyPadCodeDgt7_D_Stat 1;
BA_ "WakeupSignal" SG_ 816 KeyPadCodeDgt6_D_Stat 1;
BA_ "GenSigSendType" SG_ 816 KeyPadCodeDgt6_D_Stat 3;
BA_ "U_T6_MCA_MY2020_Tx" SG_ 816 KeyPadCodeDgt6_D_Stat 1;
BA_ "U_CD542_MY2021_Tx" SG_ 816 KeyPadCodeDgt6_D_Stat 1;
BA_ "U_U55X_MY2022_Tx" SG_ 816 KeyPadCodeDgt6_D_Stat 1;
BA_ "U_CD764_MY2022_Tx" SG_ 816 KeyPadCodeDgt6_D_Stat 1;
BA_ "WakeupSignal" SG_ 816 KeyPadCodeDgt5_D_Stat 1;
BA_ "GenSigSendType" SG_ 816 KeyPadCodeDgt5_D_Stat 3;
BA_ "U_T6_MCA_MY2020_Tx" SG_ 816 KeyPadCodeDgt5_D_Stat 1;
BA_ "U_CD542_MY2021_Tx" SG_ 816 KeyPadCodeDgt5_D_Stat 1;
BA_ "U_U55X_MY2022_Tx" SG_ 816 KeyPadCodeDgt5_D_Stat 1;
BA_ "U_CD764_MY2022_Tx" SG_ 816 KeyPadCodeDgt5_D_Stat 1;
BA_ "WakeupSignal" SG_ 816 KeyPadCodeDgt4_D_Stat 1;
BA_ "GenSigSendType" SG_ 816 KeyPadCodeDgt4_D_Stat 3;
BA_ "U_T6_MCA_MY2020_Tx" SG_ 816 KeyPadCodeDgt4_D_Stat 1;
BA_ "U_CD542_MY2021_Tx" SG_ 816 KeyPadCodeDgt4_D_Stat 1;
BA_ "U_U55X_MY2022_Tx" SG_ 816 KeyPadCodeDgt4_D_Stat 1;
BA_ "U_CD764_MY2022_Tx" SG_ 816 KeyPadCodeDgt4_D_Stat 1;
BA_ "WakeupSignal" SG_ 816 KeyPadCodeDgt3_D_Stat 1;
BA_ "GenSigSendType" SG_ 816 KeyPadCodeDgt3_D_Stat 3;
BA_ "U_T6_MCA_MY2020_Tx" SG_ 816 KeyPadCodeDgt3_D_Stat 1;
BA_ "U_CD542_MY2021_Tx" SG_ 816 KeyPadCodeDgt3_D_Stat 1;
BA_ "U_U55X_MY2022_Tx" SG_ 816 KeyPadCodeDgt3_D_Stat 1;
BA_ "U_CD764_MY2022_Tx" SG_ 816 KeyPadCodeDgt3_D_Stat 1;
BA_ "WakeupSignal" SG_ 816 KeyPadCodeDgt2_D_Stat 1;
BA_ "GenSigSendType" SG_ 816 KeyPadCodeDgt2_D_Stat 3;
BA_ "U_T6_MCA_MY2020_Tx" SG_ 816 KeyPadCodeDgt2_D_Stat 1;
BA_ "U_CD542_MY2021_Tx" SG_ 816 KeyPadCodeDgt2_D_Stat 1;
BA_ "U_U55X_MY2022_Tx" SG_ 816 KeyPadCodeDgt2_D_Stat 1;
BA_ "U_CD764_MY2022_Tx" SG_ 816 KeyPadCodeDgt2_D_Stat 1;
BA_ "WakeupSignal" SG_ 816 KeyPadCodeDgt1_D_Stat 1;
BA_ "GenSigSendType" SG_ 816 KeyPadCodeDgt1_D_Stat 3;
BA_ "U_T6_MCA_MY2020_Tx" SG_ 816 KeyPadCodeDgt1_D_Stat 1;
BA_ "U_CD542_MY2021_Tx" SG_ 816 KeyPadCodeDgt1_D_Stat 1;
BA_ "U_U55X_MY2022_Tx" SG_ 816 KeyPadCodeDgt1_D_Stat 1;
BA_ "U_CD764_MY2022_Tx" SG_ 816 KeyPadCodeDgt1_D_Stat 1;
BA_ "WakeupSignal" SG_ 816 CntrStk2_D_RqAssoc 1;
BA_ "GenSigStartValueInteger" SG_ 816 CntrStk2_D_RqAssoc 3;
BA_ "GenSigStartValue" SG_ 816 CntrStk2_D_RqAssoc 3;
BA_ "GenSigSendType" SG_ 816 CntrStk2_D_RqAssoc 3;
BA_ "U_T6_MCA_MY2020_Tx" SG_ 816 CntrStk2_D_RqAssoc 1;
BA_ "U_CD542_MY2021_Tx" SG_ 816 CntrStk2_D_RqAssoc 1;
BA_ "U_U55X_MY2022_Tx" SG_ 816 CntrStk2_D_RqAssoc 1;
BA_ "U_CD764_MY2022_Tx" SG_ 816 CntrStk2_D_RqAssoc 1;
BA_ "U_CD542_MY2021_Rx" SG_ 636 WifiHtsptFqBand_D_Stat 1;
BA_ "U_CD764_MY2022_Rx" SG_ 636 WifiHtsptFqBand_D_Stat 1;
BA_ "U_P702_MY2021_Rx" SG_ 636 WifiHtsptFqBand_D_Stat 1;
BA_ "U_T6_MCA_MY2020_Rx" SG_ 636 WifiHtsptFqBand_D_Stat 1;
BA_ "U_CD542_MY2021_Rx" SG_ 636 WifiHtspt_D_Falt 1;
BA_ "U_CD764_MY2022_Rx" SG_ 636 WifiHtspt_D_Falt 1;
BA_ "U_P702_MY2021_Rx" SG_ 636 WifiHtspt_D_Falt 1;
BA_ "U_T6_MCA_MY2020_Rx" SG_ 636 WifiHtspt_D_Falt 1;
BA_ "U_CD542_MY2021_Rx" SG_ 636 WifiNoDevcCnnct_No_Actl 1;
BA_ "U_CD764_MY2022_Rx" SG_ 636 WifiNoDevcCnnct_No_Actl 1;
BA_ "U_P702_MY2021_Rx" SG_ 636 WifiNoDevcCnnct_No_Actl 1;
BA_ "U_T6_MCA_MY2020_Rx" SG_ 636 WifiNoDevcCnnct_No_Actl 1;
BA_ "U_U55X_MY2022_Rx" SG_ 636 WifiNoDevcCnnct_No_Actl 1;
BA_ "U_CD542_MY2021_Rx" SG_ 636 WifiHtsptCnnct_D_Stat 1;
BA_ "U_CD764_MY2022_Rx" SG_ 636 WifiHtsptCnnct_D_Stat 1;
BA_ "U_P702_MY2021_Rx" SG_ 636 WifiHtsptCnnct_D_Stat 1;
BA_ "U_T6_MCA_MY2020_Rx" SG_ 636 WifiHtsptCnnct_D_Stat 1;
BA_ "U_U55X_MY2022_Rx" SG_ 636 WifiHtsptCnnct_D_Stat 1;
BA_ "U_CD542_MY2021_Rx" SG_ 636 Telematics_D_Falt 1;
BA_ "U_CD764_MY2022_Rx" SG_ 636 Telematics_D_Falt 1;
BA_ "U_P702_MY2021_Rx" SG_ 636 Telematics_D_Falt 1;
BA_ "U_T6_MCA_MY2020_Rx" SG_ 636 Telematics_D_Falt 1;
BA_ "U_U55X_MY2022_Rx" SG_ 636 Telematics_D_Falt 1;
BA_ "U_CD542_MY2021_Rx" SG_ 636 WifiEnbl_D_Stat 1;
BA_ "U_CD764_MY2022_Rx" SG_ 636 WifiEnbl_D_Stat 1;
BA_ "U_P702_MY2021_Rx" SG_ 636 WifiEnbl_D_Stat 1;
BA_ "U_T6_MCA_MY2020_Rx" SG_ 636 WifiEnbl_D_Stat 1;
BA_ "U_U55X_MY2022_Rx" SG_ 636 WifiEnbl_D_Stat 1;
BA_ "U_CD542_MY2021_Rx" SG_ 636 WifiHtsptVisbl_D_Stat 1;
BA_ "U_CD764_MY2022_Rx" SG_ 636 WifiHtsptVisbl_D_Stat 1;
BA_ "U_P702_MY2021_Rx" SG_ 636 WifiHtsptVisbl_D_Stat 1;
BA_ "U_T6_MCA_MY2020_Rx" SG_ 636 WifiHtsptVisbl_D_Stat 1;
BA_ "U_U55X_MY2022_Rx" SG_ 636 WifiHtsptVisbl_D_Stat 1;
BA_ "U_CD542_MY2021_Rx" SG_ 636 WifiHtsptScrty_D_Stat 1;
BA_ "U_CD764_MY2022_Rx" SG_ 636 WifiHtsptScrty_D_Stat 1;
BA_ "U_P702_MY2021_Rx" SG_ 636 WifiHtsptScrty_D_Stat 1;
BA_ "U_T6_MCA_MY2020_Rx" SG_ 636 WifiHtsptScrty_D_Stat 1;
BA_ "U_U55X_MY2022_Rx" SG_ 636 WifiHtsptScrty_D_Stat 1;
BA_ "U_CD542_MY2021_Rx" SG_ 636 WifiHtsptEnbl_D_Stat 1;
BA_ "U_CD764_MY2022_Rx" SG_ 636 WifiHtsptEnbl_D_Stat 1;
BA_ "U_P702_MY2021_Rx" SG_ 636 WifiHtsptEnbl_D_Stat 1;
BA_ "U_T6_MCA_MY2020_Rx" SG_ 636 WifiHtsptEnbl_D_Stat 1;
BA_ "U_U55X_MY2022_Rx" SG_ 636 WifiHtsptEnbl_D_Stat 1;
BA_ "U_CD542_MY2021_Rx" SG_ 636 WifiDevcListNew_B_Stat 1;
BA_ "U_CD764_MY2022_Rx" SG_ 636 WifiDevcListNew_B_Stat 1;
BA_ "U_P702_MY2021_Rx" SG_ 636 WifiDevcListNew_B_Stat 1;
BA_ "U_T6_MCA_MY2020_Rx" SG_ 636 WifiDevcListNew_B_Stat 1;
BA_ "U_U55X_MY2022_Rx" SG_ 636 WifiDevcListNew_B_Stat 1;
BA_ "U_CD542_MY2021_Rx" SG_ 636 WifiDataUsage_Pc_Actl 1;
BA_ "U_CD764_MY2022_Rx" SG_ 636 WifiDataUsage_Pc_Actl 1;
BA_ "U_P702_MY2021_Rx" SG_ 636 WifiDataUsage_Pc_Actl 1;
BA_ "U_T6_MCA_MY2020_Rx" SG_ 636 WifiDataUsage_Pc_Actl 1;
BA_ "U_U55X_MY2022_Rx" SG_ 636 WifiDataUsage_Pc_Actl 1;
BA_ "U_CD542_MY2021_Rx" SG_ 636 WifiDataUsage_D_Stat 1;
BA_ "U_CD764_MY2022_Rx" SG_ 636 WifiDataUsage_D_Stat 1;
BA_ "U_P702_MY2021_Rx" SG_ 636 WifiDataUsage_D_Stat 1;
BA_ "U_T6_MCA_MY2020_Rx" SG_ 636 WifiDataUsage_D_Stat 1;
BA_ "U_U55X_MY2022_Rx" SG_ 636 WifiDataUsage_D_Stat 1;
BA_ "GenSigStartValueInteger" SG_ 636 ModemSigStren_D_Stat 6;
BA_ "GenSigStartValue" SG_ 636 ModemSigStren_D_Stat 6;
BA_ "U_CD542_MY2021_Rx" SG_ 636 ModemSigStren_D_Stat 1;
BA_ "U_CD764_MY2022_Rx" SG_ 636 ModemSigStren_D_Stat 1;
BA_ "U_P702_MY2021_Rx" SG_ 636 ModemSigStren_D_Stat 1;
BA_ "U_T6_MCA_MY2020_Rx" SG_ 636 ModemSigStren_D_Stat 1;
BA_ "U_CD542_MY2021_Rx" SG_ 636 ModemTechnology_D2_Stat 1;
BA_ "U_CD764_MY2022_Rx" SG_ 636 ModemTechnology_D2_Stat 1;
BA_ "U_T6_MCA_MY2020_Rx" SG_ 636 ModemTechnology_D2_Stat 1;
BA_ "U_U55X_MY2022_Rx" SG_ 636 ModemTechnology_D2_Stat 1;
BA_ "U_P702_MY2021_Rx" SG_ 636 ModemTechnology_D2_Stat 1;
BA_ "U_CD542_MY2021_Rx" SG_ 636 WifiHtsptCrdntl_B_Stat 1;
BA_ "U_CD764_MY2022_Rx" SG_ 636 WifiHtsptCrdntl_B_Stat 1;
BA_ "U_T6_MCA_MY2020_Rx" SG_ 636 WifiHtsptCrdntl_B_Stat 1;
BA_ "U_U55X_MY2022_Rx" SG_ 636 WifiHtsptCrdntl_B_Stat 1;
BA_ "U_CD542_MY2021_Rx" SG_ 636 WifiHtsptFq_D_Avail 1;
BA_ "U_CD764_MY2022_Rx" SG_ 636 WifiHtsptFq_D_Avail 1;
BA_ "U_P702_MY2021_Rx" SG_ 636 WifiHtsptFq_D_Avail 1;
BA_ "U_T6_MCA_MY2020_Rx" SG_ 636 WifiHtsptFq_D_Avail 1;
BA_ "U_CD542_MY2021_Rx" SG_ 636 WifiDataUsageOn_D_Stat 1;
BA_ "U_CD764_MY2022_Rx" SG_ 636 WifiDataUsageOn_D_Stat 1;
BA_ "U_P702_MY2021_Rx" SG_ 636 WifiDataUsageOn_D_Stat 1;
BA_ "U_T6_MCA_MY2020_Rx" SG_ 636 WifiDataUsageOn_D_Stat 1;
BA_ "U_U55X_MY2022_Rx" SG_ 636 WifiDataUsageOn_D_Stat 1;
BA_ "GenSigSendType" SG_ 807 ElDistTripCur_No_Dsply 3;
BA_ "U_CD542_MY2021_Rx" SG_ 807 ElDistTripCur_No_Dsply 1;
BA_ "U_U55X_MY2022_Rx" SG_ 807 ElDistTripCur_No_Dsply 1;
BA_ "U_CD542_MY2021_Tx" SG_ 807 ElDistTripCur_No_Dsply 1;
BA_ "U_U55X_MY2022_Tx" SG_ 807 ElDistTripCur_No_Dsply 1;
BA_ "U_CD764_MY2022_Tx" SG_ 807 ElDistTripCur_No_Dsply 1;
BA_ "GenSigSendType" SG_ 807 ElDistTripUnit_D_Stat 3;
BA_ "U_T6_MCA_MY2020_Rx" SG_ 807 ElDistTripUnit_D_Stat 1;
BA_ "U_CD542_MY2021_Rx" SG_ 807 ElDistTripUnit_D_Stat 1;
BA_ "U_U55X_MY2022_Rx" SG_ 807 ElDistTripUnit_D_Stat 1;
BA_ "U_T6_MCA_MY2020_Tx" SG_ 807 ElDistTripUnit_D_Stat 1;
BA_ "U_CD542_MY2021_Tx" SG_ 807 ElDistTripUnit_D_Stat 1;
BA_ "U_U55X_MY2022_Tx" SG_ 807 ElDistTripUnit_D_Stat 1;
BA_ "U_CD764_MY2022_Tx" SG_ 807 ElDistTripUnit_D_Stat 1;
BA_ "GenSigSendType" SG_ 807 ElDistTrip2_No_Dsply 3;
BA_ "U_T6_MCA_MY2020_Rx" SG_ 807 ElDistTrip2_No_Dsply 1;
BA_ "U_CD542_MY2021_Rx" SG_ 807 ElDistTrip2_No_Dsply 1;
BA_ "U_U55X_MY2022_Rx" SG_ 807 ElDistTrip2_No_Dsply 1;
BA_ "U_T6_MCA_MY2020_Tx" SG_ 807 ElDistTrip2_No_Dsply 1;
BA_ "U_CD542_MY2021_Tx" SG_ 807 ElDistTrip2_No_Dsply 1;
BA_ "U_U55X_MY2022_Tx" SG_ 807 ElDistTrip2_No_Dsply 1;
BA_ "U_CD764_MY2022_Tx" SG_ 807 ElDistTrip2_No_Dsply 1;
BA_ "GenSigSendType" SG_ 807 ElDistTrip1_No_Dsply 3;
BA_ "U_T6_MCA_MY2020_Rx" SG_ 807 ElDistTrip1_No_Dsply 1;
BA_ "U_CD542_MY2021_Rx" SG_ 807 ElDistTrip1_No_Dsply 1;
BA_ "U_U55X_MY2022_Rx" SG_ 807 ElDistTrip1_No_Dsply 1;
BA_ "U_T6_MCA_MY2020_Tx" SG_ 807 ElDistTrip1_No_Dsply 1;
BA_ "U_CD542_MY2021_Tx" SG_ 807 ElDistTrip1_No_Dsply 1;
BA_ "U_U55X_MY2022_Tx" SG_ 807 ElDistTrip1_No_Dsply 1;
BA_ "U_CD764_MY2022_Tx" SG_ 807 ElDistTrip1_No_Dsply 1;
BA_ "U_U55X_MY2022_Rx" SG_ 974 EngExhMdeHrStrt_D_Stat 1;
BA_ "U_CD764_MY2022_Rx" SG_ 974 EngExhMdeHrStrt_D_Stat 1;
BA_ "U_U55X_MY2022_Rx" SG_ 974 EngExhMdeHrEnd_D_Stat 1;
BA_ "U_CD764_MY2022_Rx" SG_ 974 EngExhMdeHrEnd_D_Stat 1;
BA_ "U_U55X_MY2022_Rx" SG_ 974 EngExhMdeHrEnbl_D_Stat 1;
BA_ "U_CD764_MY2022_Rx" SG_ 974 EngExhMdeHrEnbl_D_Stat 1;
BA_ "U_CD542_MY2021_Rx" SG_ 974 DcacOut_Pw_DsplyMx 1;
BA_ "U_U55X_MY2022_Rx" SG_ 974 DcacOut_Pw_DsplyMx 1;
BA_ "U_CD764_MY2022_Rx" SG_ 974 DcacOut_Pw_DsplyMx 1;
BA_ "U_CD542_MY2021_Rx" SG_ 974 DcacOut1_Pw_Dsply 1;
BA_ "U_U55X_MY2022_Rx" SG_ 974 DcacOut1_Pw_Dsply 1;
BA_ "U_CD764_MY2022_Rx" SG_ 974 DcacOut1_Pw_Dsply 1;
BA_ "U_CD542_MY2021_Rx" SG_ 974 DcacOut2_Pw_Dsply 1;
BA_ "U_U55X_MY2022_Rx" SG_ 974 DcacOut2_Pw_Dsply 1;
BA_ "GenSigStartValueInteger" SG_ 974 DcacHw_D_Confg 1;
BA_ "U_CD542_MY2021_Rx" SG_ 974 DcacHw_D_Confg 1;
BA_ "U_U55X_MY2022_Rx" SG_ 974 DcacHw_D_Confg 1;
BA_ "GenSigStartValueInteger" SG_ 974 DcacFaltMsgTxt_D_Rq 1;
BA_ "U_CD542_MY2021_Rx" SG_ 974 DcacFaltMsgTxt_D_Rq 1;
BA_ "U_U55X_MY2022_Rx" SG_ 974 DcacFaltMsgTxt_D_Rq 1;
BA_ "U_CD542_MY2021_Rx" SG_ 974 DcacLoFuelMsgTxt_D_Rq 1;
BA_ "U_U55X_MY2022_Rx" SG_ 974 DcacLoFuelMsgTxt_D_Rq 1;
BA_ "U_CD542_MY2021_Rx" SG_ 974 DcacEngOnMsgTxt_D_Rq 1;
BA_ "U_U55X_MY2022_Rx" SG_ 974 DcacEngOnMsgTxt_D_Rq 1;
BA_ "GenSigStartValueInteger" SG_ 974 DcacElPw_D_Stat 1;
BA_ "GenSigStartValue" SG_ 974 DcacElPw_D_Stat 1;
BA_ "U_CD542_MY2021_Rx" SG_ 974 DcacElPw_D_Stat 1;
BA_ "U_U55X_MY2022_Rx" SG_ 974 DcacElPw_D_Stat 1;
BA_ "U_T6_MCA_MY2020_Rx" SG_ 805 InstFeTripUnit_D_Stat 1;
BA_ "U_U55X_MY2022_Rx" SG_ 805 InstFeTripUnit_D_Stat 1;
BA_ "U_CD542_MY2021_Rx" SG_ 805 InstFeTripUnit_D_Stat 1;
BA_ "U_T6_MCA_MY2020_Tx" SG_ 805 InstFeTripUnit_D_Stat 1;
BA_ "U_CD542_MY2021_Tx" SG_ 805 InstFeTripUnit_D_Stat 1;
BA_ "U_U55X_MY2022_Tx" SG_ 805 InstFeTripUnit_D_Stat 1;
BA_ "U_CD764_MY2022_Tx" SG_ 805 InstFeTripUnit_D_Stat 1;
BA_ "U_T6_MCA_MY2020_Rx" SG_ 805 InstFe_No_Dsply 1;
BA_ "U_U55X_MY2022_Rx" SG_ 805 InstFe_No_Dsply 1;
BA_ "U_CD542_MY2021_Rx" SG_ 805 InstFe_No_Dsply 1;
BA_ "U_T6_MCA_MY2020_Tx" SG_ 805 InstFe_No_Dsply 1;
BA_ "U_CD542_MY2021_Tx" SG_ 805 InstFe_No_Dsply 1;
BA_ "U_U55X_MY2022_Tx" SG_ 805 InstFe_No_Dsply 1;
BA_ "U_CD764_MY2022_Tx" SG_ 805 InstFe_No_Dsply 1;
BA_ "GenSigSendType" SG_ 804 InstFeMax_No_Dsply 3;
BA_ "U_T6_MCA_MY2020_Rx" SG_ 804 InstFeMax_No_Dsply 1;
BA_ "U_U55X_MY2022_Rx" SG_ 804 InstFeMax_No_Dsply 1;
BA_ "U_CD542_MY2021_Rx" SG_ 804 InstFeMax_No_Dsply 1;
BA_ "U_T6_MCA_MY2020_Tx" SG_ 804 InstFeMax_No_Dsply 1;
BA_ "U_CD542_MY2021_Tx" SG_ 804 InstFeMax_No_Dsply 1;
BA_ "U_U55X_MY2022_Tx" SG_ 804 InstFeMax_No_Dsply 1;
BA_ "U_CD764_MY2022_Tx" SG_ 804 InstFeMax_No_Dsply 1;
BA_ "GenSigSendType" SG_ 804 ConsInstActv_B_Dsply 3;
BA_ "U_T6_MCA_MY2020_Rx" SG_ 804 ConsInstActv_B_Dsply 1;
BA_ "U_U55X_MY2022_Rx" SG_ 804 ConsInstActv_B_Dsply 1;
BA_ "U_CD542_MY2021_Rx" SG_ 804 ConsInstActv_B_Dsply 1;
BA_ "U_T6_MCA_MY2020_Tx" SG_ 804 ConsInstActv_B_Dsply 1;
BA_ "U_CD542_MY2021_Tx" SG_ 804 ConsInstActv_B_Dsply 1;
BA_ "U_U55X_MY2022_Tx" SG_ 804 ConsInstActv_B_Dsply 1;
BA_ "U_CD764_MY2022_Tx" SG_ 804 ConsInstActv_B_Dsply 1;
BA_ "GenSigSendType" SG_ 804 ConsInst_No_Dsply 3;
BA_ "U_T6_MCA_MY2020_Rx" SG_ 804 ConsInst_No_Dsply 1;
BA_ "U_U55X_MY2022_Rx" SG_ 804 ConsInst_No_Dsply 1;
BA_ "U_CD542_MY2021_Rx" SG_ 804 ConsInst_No_Dsply 1;
BA_ "U_T6_MCA_MY2020_Tx" SG_ 804 ConsInst_No_Dsply 1;
BA_ "U_CD542_MY2021_Tx" SG_ 804 ConsInst_No_Dsply 1;
BA_ "U_U55X_MY2022_Tx" SG_ 804 ConsInst_No_Dsply 1;
BA_ "U_CD764_MY2022_Tx" SG_ 804 ConsInst_No_Dsply 1;
BA_ "GenSigSendType" SG_ 804 ConsInstUnit_D_Stat 3;
BA_ "U_T6_MCA_MY2020_Rx" SG_ 804 ConsInstUnit_D_Stat 1;
BA_ "U_U55X_MY2022_Rx" SG_ 804 ConsInstUnit_D_Stat 1;
BA_ "U_CD764_MY2022_Rx" SG_ 804 ConsInstUnit_D_Stat 1;
BA_ "U_CD542_MY2021_Tx" SG_ 804 ConsInstUnit_D_Stat 1;
BA_ "U_U55X_MY2022_Tx" SG_ 804 ConsInstUnit_D_Stat 1;
BA_ "U_CD764_MY2022_Tx" SG_ 804 ConsInstUnit_D_Stat 1;
BA_ "GenSigSendType" SG_ 803 DistTripUnit_D_Stat 3;
BA_ "U_T6_MCA_MY2020_Rx" SG_ 803 DistTripUnit_D_Stat 1;
BA_ "U_CD542_MY2021_Rx" SG_ 803 DistTripUnit_D_Stat 1;
BA_ "U_U55X_MY2022_Rx" SG_ 803 DistTripUnit_D_Stat 1;
BA_ "U_T6_MCA_MY2020_Tx" SG_ 803 DistTripUnit_D_Stat 1;
BA_ "U_CD542_MY2021_Tx" SG_ 803 DistTripUnit_D_Stat 1;
BA_ "U_U55X_MY2022_Tx" SG_ 803 DistTripUnit_D_Stat 1;
BA_ "U_CD764_MY2022_Tx" SG_ 803 DistTripUnit_D_Stat 1;
BA_ "GenSigSendType" SG_ 803 DistTrip2_No_Dsply 3;
BA_ "U_T6_MCA_MY2020_Rx" SG_ 803 DistTrip2_No_Dsply 1;
BA_ "U_CD542_MY2021_Rx" SG_ 803 DistTrip2_No_Dsply 1;
BA_ "U_U55X_MY2022_Rx" SG_ 803 DistTrip2_No_Dsply 1;
BA_ "U_T6_MCA_MY2020_Tx" SG_ 803 DistTrip2_No_Dsply 1;
BA_ "U_CD542_MY2021_Tx" SG_ 803 DistTrip2_No_Dsply 1;
BA_ "U_U55X_MY2022_Tx" SG_ 803 DistTrip2_No_Dsply 1;
BA_ "U_CD764_MY2022_Tx" SG_ 803 DistTrip2_No_Dsply 1;
BA_ "GenSigSendType" SG_ 803 DistTrip1_No_Dsply 3;
BA_ "U_T6_MCA_MY2020_Rx" SG_ 803 DistTrip1_No_Dsply 1;
BA_ "U_CD542_MY2021_Rx" SG_ 803 DistTrip1_No_Dsply 1;
BA_ "U_U55X_MY2022_Rx" SG_ 803 DistTrip1_No_Dsply 1;
BA_ "U_T6_MCA_MY2020_Tx" SG_ 803 DistTrip1_No_Dsply 1;
BA_ "U_CD542_MY2021_Tx" SG_ 803 DistTrip1_No_Dsply 1;
BA_ "U_U55X_MY2022_Tx" SG_ 803 DistTrip1_No_Dsply 1;
BA_ "U_CD764_MY2022_Tx" SG_ 803 DistTrip1_No_Dsply 1;
BA_ "GenSigSendType" SG_ 802 AvgFeTripUnit_D_Stat 3;
BA_ "U_T6_MCA_MY2020_Rx" SG_ 802 AvgFeTripUnit_D_Stat 1;
BA_ "U_U55X_MY2022_Rx" SG_ 802 AvgFeTripUnit_D_Stat 1;
BA_ "U_CD542_MY2021_Rx" SG_ 802 AvgFeTripUnit_D_Stat 1;
BA_ "U_T6_MCA_MY2020_Tx" SG_ 802 AvgFeTripUnit_D_Stat 1;
BA_ "U_CD542_MY2021_Tx" SG_ 802 AvgFeTripUnit_D_Stat 1;
BA_ "U_U55X_MY2022_Tx" SG_ 802 AvgFeTripUnit_D_Stat 1;
BA_ "U_CD764_MY2022_Tx" SG_ 802 AvgFeTripUnit_D_Stat 1;
BA_ "GenSigSendType" SG_ 802 AvgFeTrip2Actv_B_Dsply 3;
BA_ "U_T6_MCA_MY2020_Rx" SG_ 802 AvgFeTrip2Actv_B_Dsply 1;
BA_ "U_U55X_MY2022_Rx" SG_ 802 AvgFeTrip2Actv_B_Dsply 1;
BA_ "U_CD542_MY2021_Rx" SG_ 802 AvgFeTrip2Actv_B_Dsply 1;
BA_ "U_T6_MCA_MY2020_Tx" SG_ 802 AvgFeTrip2Actv_B_Dsply 1;
BA_ "U_CD542_MY2021_Tx" SG_ 802 AvgFeTrip2Actv_B_Dsply 1;
BA_ "U_U55X_MY2022_Tx" SG_ 802 AvgFeTrip2Actv_B_Dsply 1;
BA_ "U_CD764_MY2022_Tx" SG_ 802 AvgFeTrip2Actv_B_Dsply 1;
BA_ "GenSigSendType" SG_ 802 AvgFeTrip2_No_Dsply 3;
BA_ "U_T6_MCA_MY2020_Rx" SG_ 802 AvgFeTrip2_No_Dsply 1;
BA_ "U_U55X_MY2022_Rx" SG_ 802 AvgFeTrip2_No_Dsply 1;
BA_ "U_CD542_MY2021_Rx" SG_ 802 AvgFeTrip2_No_Dsply 1;
BA_ "U_T6_MCA_MY2020_Tx" SG_ 802 AvgFeTrip2_No_Dsply 1;
BA_ "U_CD542_MY2021_Tx" SG_ 802 AvgFeTrip2_No_Dsply 1;
BA_ "U_U55X_MY2022_Tx" SG_ 802 AvgFeTrip2_No_Dsply 1;
BA_ "U_CD764_MY2022_Tx" SG_ 802 AvgFeTrip2_No_Dsply 1;
BA_ "GenSigSendType" SG_ 802 AvgFeTrip1Actv_B_Dsply 3;
BA_ "U_T6_MCA_MY2020_Rx" SG_ 802 AvgFeTrip1Actv_B_Dsply 1;
BA_ "U_U55X_MY2022_Rx" SG_ 802 AvgFeTrip1Actv_B_Dsply 1;
BA_ "U_CD542_MY2021_Rx" SG_ 802 AvgFeTrip1Actv_B_Dsply 1;
BA_ "U_T6_MCA_MY2020_Tx" SG_ 802 AvgFeTrip1Actv_B_Dsply 1;
BA_ "U_CD542_MY2021_Tx" SG_ 802 AvgFeTrip1Actv_B_Dsply 1;
BA_ "U_U55X_MY2022_Tx" SG_ 802 AvgFeTrip1Actv_B_Dsply 1;
BA_ "U_CD764_MY2022_Tx" SG_ 802 AvgFeTrip1Actv_B_Dsply 1;
BA_ "GenSigSendType" SG_ 802 AvgFeTrip1_No_Dsply 3;
BA_ "U_T6_MCA_MY2020_Rx" SG_ 802 AvgFeTrip1_No_Dsply 1;
BA_ "U_U55X_MY2022_Rx" SG_ 802 AvgFeTrip1_No_Dsply 1;
BA_ "U_CD542_MY2021_Rx" SG_ 802 AvgFeTrip1_No_Dsply 1;
BA_ "U_T6_MCA_MY2020_Tx" SG_ 802 AvgFeTrip1_No_Dsply 1;
BA_ "U_CD542_MY2021_Tx" SG_ 802 AvgFeTrip1_No_Dsply 1;
BA_ "U_U55X_MY2022_Tx" SG_ 802 AvgFeTrip1_No_Dsply 1;
BA_ "U_CD764_MY2022_Tx" SG_ 802 AvgFeTrip1_No_Dsply 1;
BA_ "GenSigSendType" SG_ 802 AvgFeActv_B_Dsply 3;
BA_ "U_T6_MCA_MY2020_Rx" SG_ 802 AvgFeActv_B_Dsply 1;
BA_ "U_U55X_MY2022_Rx" SG_ 802 AvgFeActv_B_Dsply 1;
BA_ "U_CD542_MY2021_Rx" SG_ 802 AvgFeActv_B_Dsply 1;
BA_ "U_T6_MCA_MY2020_Tx" SG_ 802 AvgFeActv_B_Dsply 1;
BA_ "U_CD542_MY2021_Tx" SG_ 802 AvgFeActv_B_Dsply 1;
BA_ "U_U55X_MY2022_Tx" SG_ 802 AvgFeActv_B_Dsply 1;
BA_ "U_CD764_MY2022_Tx" SG_ 802 AvgFeActv_B_Dsply 1;
BA_ "GenSigSendType" SG_ 802 AvgFe_No_Dsply 3;
BA_ "U_T6_MCA_MY2020_Rx" SG_ 802 AvgFe_No_Dsply 1;
BA_ "U_U55X_MY2022_Rx" SG_ 802 AvgFe_No_Dsply 1;
BA_ "U_CD542_MY2021_Rx" SG_ 802 AvgFe_No_Dsply 1;
BA_ "U_T6_MCA_MY2020_Tx" SG_ 802 AvgFe_No_Dsply 1;
BA_ "U_CD542_MY2021_Tx" SG_ 802 AvgFe_No_Dsply 1;
BA_ "U_U55X_MY2022_Tx" SG_ 802 AvgFe_No_Dsply 1;
BA_ "U_CD764_MY2022_Tx" SG_ 802 AvgFe_No_Dsply 1;
BA_ "GenSigSendType" SG_ 812 TimerTrip2_T_Dsply 3;
BA_ "U_T6_MCA_MY2020_Rx" SG_ 812 TimerTrip2_T_Dsply 1;
BA_ "U_CD542_MY2021_Rx" SG_ 812 TimerTrip2_T_Dsply 1;
BA_ "U_U55X_MY2022_Rx" SG_ 812 TimerTrip2_T_Dsply 1;
BA_ "U_T6_MCA_MY2020_Tx" SG_ 812 TimerTrip2_T_Dsply 1;
BA_ "U_U55X_MY2022_Tx" SG_ 812 TimerTrip2_T_Dsply 1;
BA_ "U_CD764_MY2022_Tx" SG_ 812 TimerTrip2_T_Dsply 1;
BA_ "GenSigSendType" SG_ 812 TimerTrip1_T_Dsply 3;
BA_ "U_T6_MCA_MY2020_Rx" SG_ 812 TimerTrip1_T_Dsply 1;
BA_ "U_CD542_MY2021_Rx" SG_ 812 TimerTrip1_T_Dsply 1;
BA_ "U_U55X_MY2022_Rx" SG_ 812 TimerTrip1_T_Dsply 1;
BA_ "U_T6_MCA_MY2020_Tx" SG_ 812 TimerTrip1_T_Dsply 1;
BA_ "U_CD542_MY2021_Tx" SG_ 812 TimerTrip1_T_Dsply 1;
BA_ "U_U55X_MY2022_Tx" SG_ 812 TimerTrip1_T_Dsply 1;
BA_ "U_CD764_MY2022_Tx" SG_ 812 TimerTrip1_T_Dsply 1;
BA_ "U_T6_MCA_MY2020_Rx" SG_ 885 VehStrtInhbt_T_Dsply 1;
BA_ "U_CD542_MY2021_Rx" SG_ 885 VehStrtInhbt_T_Dsply 1;
BA_ "U_U55X_MY2022_Rx" SG_ 885 VehStrtInhbt_T_Dsply 1;
BA_ "U_CD764_MY2022_Rx" SG_ 885 VehStrtInhbt_T_Dsply 1;
BA_ "U_T6_MCA_MY2020_Tx" SG_ 885 VehStrtInhbt_T_Dsply 1;
BA_ "ECGUsedTxSignal" SG_ 885 VehStrtInhbt_T_Dsply 1;
BA_ "U_CD542_MY2021_Tx" SG_ 885 VehStrtInhbt_T_Dsply 1;
BA_ "U_U55X_MY2022_Tx" SG_ 885 VehStrtInhbt_T_Dsply 1;
BA_ "U_CD764_MY2022_Tx" SG_ 885 VehStrtInhbt_T_Dsply 1;
BA_ "U_T6_MCA_MY2020_Rx" SG_ 885 VehStrtInhbt_D_Dsply 1;
BA_ "U_CD542_MY2021_Rx" SG_ 885 VehStrtInhbt_D_Dsply 1;
BA_ "U_U55X_MY2022_Rx" SG_ 885 VehStrtInhbt_D_Dsply 1;
BA_ "U_CD764_MY2022_Rx" SG_ 885 VehStrtInhbt_D_Dsply 1;
BA_ "U_T6_MCA_MY2020_Tx" SG_ 885 VehStrtInhbt_D_Dsply 1;
BA_ "ECGUsedTxSignal" SG_ 885 VehStrtInhbt_D_Dsply 1;
BA_ "U_CD542_MY2021_Tx" SG_ 885 VehStrtInhbt_D_Dsply 1;
BA_ "U_U55X_MY2022_Tx" SG_ 885 VehStrtInhbt_D_Dsply 1;
BA_ "U_CD764_MY2022_Tx" SG_ 885 VehStrtInhbt_D_Dsply 1;
BA_ "U_T6_MCA_MY2020_Rx" SG_ 885 OtaActv_D_Stat 1;
BA_ "U_CD542_MY2021_Rx" SG_ 885 OtaActv_D_Stat 1;
BA_ "U_U55X_MY2022_Rx" SG_ 885 OtaActv_D_Stat 1;
BA_ "U_CD764_MY2022_Rx" SG_ 885 OtaActv_D_Stat 1;
BA_ "U_T6_MCA_MY2020_Tx" SG_ 885 OtaActv_D_Stat 1;
BA_ "ECGUsedTxSignal" SG_ 885 OtaActv_D_Stat 1;
BA_ "U_CD542_MY2021_Tx" SG_ 885 OtaActv_D_Stat 1;
BA_ "U_U55X_MY2022_Tx" SG_ 885 OtaActv_D_Stat 1;
BA_ "U_CD764_MY2022_Tx" SG_ 885 OtaActv_D_Stat 1;
BA_ "GenSigSendType" SG_ 1119 LocationServices_2 1;
BA_ "U_T6_MCA_MY2020_Rx" SG_ 1119 LocationServices_2 1;
BA_ "ECGUsedRxSignal" SG_ 1119 LocationServices_2 1;
BA_ "U_CD542_MY2021_Rx" SG_ 1119 LocationServices_2 1;
BA_ "U_U55X_MY2022_Rx" SG_ 1119 LocationServices_2 1;
BA_ "U_CD764_MY2022_Rx" SG_ 1119 LocationServices_2 1;
BA_ "U_P702_MY2021_Tx" SG_ 1119 LocationServices_2 1;
BA_ "U_T6_MCA_MY2020_Tx" SG_ 1119 LocationServices_2 1;
BA_ "U_CD542_MY2021_Tx" SG_ 1119 LocationServices_2 1;
BA_ "U_U55X_MY2022_Tx" SG_ 1119 LocationServices_2 1;
BA_ "U_CD764_MY2022_Tx" SG_ 1119 LocationServices_2 1;
BA_ "GenSigSendType" SG_ 1118 LocationServices_1 1;
BA_ "U_T6_MCA_MY2020_Rx" SG_ 1118 LocationServices_1 1;
BA_ "ECGUsedRxSignal" SG_ 1118 LocationServices_1 1;
BA_ "U_CD542_MY2021_Rx" SG_ 1118 LocationServices_1 1;
BA_ "U_U55X_MY2022_Rx" SG_ 1118 LocationServices_1 1;
BA_ "U_CD764_MY2022_Rx" SG_ 1118 LocationServices_1 1;
BA_ "U_P702_MY2021_Tx" SG_ 1118 LocationServices_1 1;
BA_ "U_T6_MCA_MY2020_Tx" SG_ 1118 LocationServices_1 1;
BA_ "U_CD542_MY2021_Tx" SG_ 1118 LocationServices_1 1;
BA_ "U_U55X_MY2022_Tx" SG_ 1118 LocationServices_1 1;
BA_ "U_CD764_MY2022_Tx" SG_ 1118 LocationServices_1 1;
BA_ "GenSigSendType" SG_ 290 WifiHtsptFqBand_D_Rq 3;
BA_ "U_CD542_MY2021_Tx" SG_ 290 WifiHtsptFqBand_D_Rq 1;
BA_ "U_U55X_MY2022_Tx" SG_ 290 WifiHtsptFqBand_D_Rq 1;
BA_ "U_CD764_MY2022_Tx" SG_ 290 WifiHtsptFqBand_D_Rq 1;
BA_ "U_P702_MY2021_Tx" SG_ 290 WifiHtsptFqBand_D_Rq 1;
BA_ "U_T6_MCA_MY2020_Tx" SG_ 290 WifiHtsptFqBand_D_Rq 1;
BA_ "GenSigSendType" SG_ 290 WifiHtsptTrial_D_RqDrv 3;
BA_ "U_CD542_MY2021_Tx" SG_ 290 WifiHtsptTrial_D_RqDrv 1;
BA_ "U_U55X_MY2022_Tx" SG_ 290 WifiHtsptTrial_D_RqDrv 1;
BA_ "U_CD764_MY2022_Tx" SG_ 290 WifiHtsptTrial_D_RqDrv 1;
BA_ "U_P702_MY2021_Tx" SG_ 290 WifiHtsptTrial_D_RqDrv 1;
BA_ "U_T6_MCA_MY2020_Tx" SG_ 290 WifiHtsptTrial_D_RqDrv 1;
BA_ "GenSigSendType" SG_ 290 WifiHtsptEnbl_D_Rq 3;
BA_ "U_CD542_MY2021_Tx" SG_ 290 WifiHtsptEnbl_D_Rq 1;
BA_ "U_U55X_MY2022_Tx" SG_ 290 WifiHtsptEnbl_D_Rq 1;
BA_ "U_CD764_MY2022_Tx" SG_ 290 WifiHtsptEnbl_D_Rq 1;
BA_ "U_P702_MY2021_Tx" SG_ 290 WifiHtsptEnbl_D_Rq 1;
BA_ "U_T6_MCA_MY2020_Tx" SG_ 290 WifiHtsptEnbl_D_Rq 1;
BA_ "GenSigStartValueInteger" SG_ 290 WifiRemoveIndx_No_Rq 20;
BA_ "GenSigStartValue" SG_ 290 WifiRemoveIndx_No_Rq 20;
BA_ "U_P702_MY2021_Tx" SG_ 290 WifiRemoveIndx_No_Rq 1;
BA_ "U_T6_MCA_MY2020_Tx" SG_ 290 WifiRemoveIndx_No_Rq 1;
BA_ "U_CD542_MY2021_Tx" SG_ 290 WifiRemoveIndx_No_Rq 1;
BA_ "U_U55X_MY2022_Tx" SG_ 290 WifiRemoveIndx_No_Rq 1;
BA_ "U_CD764_MY2022_Tx" SG_ 290 WifiRemoveIndx_No_Rq 1;
BA_ "GenSigSendType" SG_ 290 WifiRemoveDevc_D_Rq 3;
BA_ "U_P702_MY2021_Tx" SG_ 290 WifiRemoveDevc_D_Rq 1;
BA_ "U_T6_MCA_MY2020_Tx" SG_ 290 WifiRemoveDevc_D_Rq 1;
BA_ "U_CD542_MY2021_Tx" SG_ 290 WifiRemoveDevc_D_Rq 1;
BA_ "U_U55X_MY2022_Tx" SG_ 290 WifiRemoveDevc_D_Rq 1;
BA_ "U_CD764_MY2022_Tx" SG_ 290 WifiRemoveDevc_D_Rq 1;
BA_ "GenSigSendType" SG_ 290 WifiHtsptVisbl_D_Rq 3;
BA_ "U_P702_MY2021_Tx" SG_ 290 WifiHtsptVisbl_D_Rq 1;
BA_ "U_T6_MCA_MY2020_Tx" SG_ 290 WifiHtsptVisbl_D_Rq 1;
BA_ "U_CD542_MY2021_Tx" SG_ 290 WifiHtsptVisbl_D_Rq 1;
BA_ "U_U55X_MY2022_Tx" SG_ 290 WifiHtsptVisbl_D_Rq 1;
BA_ "U_CD764_MY2022_Tx" SG_ 290 WifiHtsptVisbl_D_Rq 1;
BA_ "GenSigSendType" SG_ 290 WifiHtsptMacAddr_B_Rq 3;
BA_ "U_P702_MY2021_Tx" SG_ 290 WifiHtsptMacAddr_B_Rq 1;
BA_ "U_T6_MCA_MY2020_Tx" SG_ 290 WifiHtsptMacAddr_B_Rq 1;
BA_ "U_CD542_MY2021_Tx" SG_ 290 WifiHtsptMacAddr_B_Rq 1;
BA_ "U_U55X_MY2022_Tx" SG_ 290 WifiHtsptMacAddr_B_Rq 1;
BA_ "U_CD764_MY2022_Tx" SG_ 290 WifiHtsptMacAddr_B_Rq 1;
BA_ "U_P702_MY2021_Tx" SG_ 290 WifiDevcListSize_D_Rq 1;
BA_ "U_T6_MCA_MY2020_Tx" SG_ 290 WifiDevcListSize_D_Rq 1;
BA_ "U_CD542_MY2021_Tx" SG_ 290 WifiDevcListSize_D_Rq 1;
BA_ "U_U55X_MY2022_Tx" SG_ 290 WifiDevcListSize_D_Rq 1;
BA_ "U_CD764_MY2022_Tx" SG_ 290 WifiDevcListSize_D_Rq 1;
BA_ "GenSigStartValueInteger" SG_ 290 WifiDevcListIndx_No_Rq 22;
BA_ "GenSigStartValue" SG_ 290 WifiDevcListIndx_No_Rq 22;
BA_ "U_P702_MY2021_Tx" SG_ 290 WifiDevcListIndx_No_Rq 1;
BA_ "U_T6_MCA_MY2020_Tx" SG_ 290 WifiDevcListIndx_No_Rq 1;
BA_ "U_CD542_MY2021_Tx" SG_ 290 WifiDevcListIndx_No_Rq 1;
BA_ "U_U55X_MY2022_Tx" SG_ 290 WifiDevcListIndx_No_Rq 1;
BA_ "U_CD764_MY2022_Tx" SG_ 290 WifiDevcListIndx_No_Rq 1;
BA_ "GenSigSendType" SG_ 290 WifiDevcList_D_Rq 3;
BA_ "U_P702_MY2021_Tx" SG_ 290 WifiDevcList_D_Rq 1;
BA_ "U_T6_MCA_MY2020_Tx" SG_ 290 WifiDevcList_D_Rq 1;
BA_ "U_CD542_MY2021_Tx" SG_ 290 WifiDevcList_D_Rq 1;
BA_ "U_U55X_MY2022_Tx" SG_ 290 WifiDevcList_D_Rq 1;
BA_ "U_CD764_MY2022_Tx" SG_ 290 WifiDevcList_D_Rq 1;
BA_ "GenSigSendType" SG_ 290 WifiDataUsage_D_Rq 3;
BA_ "U_P702_MY2021_Tx" SG_ 290 WifiDataUsage_D_Rq 1;
BA_ "U_T6_MCA_MY2020_Tx" SG_ 290 WifiDataUsage_D_Rq 1;
BA_ "U_CD542_MY2021_Tx" SG_ 290 WifiDataUsage_D_Rq 1;
BA_ "U_U55X_MY2022_Tx" SG_ 290 WifiDataUsage_D_Rq 1;
BA_ "U_CD764_MY2022_Tx" SG_ 290 WifiDataUsage_D_Rq 1;
BA_ "GenSigSendType" SG_ 290 WifiCarrierInfo_B_Rq 3;
BA_ "U_P702_MY2021_Tx" SG_ 290 WifiCarrierInfo_B_Rq 1;
BA_ "U_T6_MCA_MY2020_Tx" SG_ 290 WifiCarrierInfo_B_Rq 1;
BA_ "U_CD542_MY2021_Tx" SG_ 290 WifiCarrierInfo_B_Rq 1;
BA_ "U_U55X_MY2022_Tx" SG_ 290 WifiCarrierInfo_B_Rq 1;
BA_ "U_CD764_MY2022_Tx" SG_ 290 WifiCarrierInfo_B_Rq 1;
BA_ "GenSigSendType" SG_ 290 WifiHtsptScrty_D_Rq 3;
BA_ "U_CD542_MY2021_Tx" SG_ 290 WifiHtsptScrty_D_Rq 1;
BA_ "U_U55X_MY2022_Tx" SG_ 290 WifiHtsptScrty_D_Rq 1;
BA_ "U_P702_MY2021_Tx" SG_ 290 WifiHtsptScrty_D_Rq 1;
BA_ "U_T6_MCA_MY2020_Tx" SG_ 290 WifiHtsptScrty_D_Rq 1;
BA_ "GenSigSendType" SG_ 2612101336 PARSEDPushFcGWM_ECGtoIPC 3;
BA_ "U_T6_MCA_MY2020_Rx" SG_ 2612101336 PARSEDPushFcGWM_ECGtoIPC 1;
BA_ "U_CD542_MY2021_Rx" SG_ 2612101336 PARSEDPushFcGWM_ECGtoIPC 1;
BA_ "U_U55X_MY2022_Rx" SG_ 2612101336 PARSEDPushFcGWM_ECGtoIPC 1;
BA_ "U_CD764_MY2022_Rx" SG_ 2612101336 PARSEDPushFcGWM_ECGtoIPC 1;
BA_ "U_T6_MCA_MY2020_Tx" SG_ 2612101336 PARSEDPushFcGWM_ECGtoIPC 1;
BA_ "ECGUsedTxSignal" SG_ 2612101336 PARSEDPushFcGWM_ECGtoIPC 1;
BA_ "U_CD542_MY2021_Tx" SG_ 2612101336 PARSEDPushFcGWM_ECGtoIPC 1;
BA_ "U_U55X_MY2022_Tx" SG_ 2612101336 PARSEDPushFcGWM_ECGtoIPC 1;
BA_ "U_CD764_MY2022_Tx" SG_ 2612101336 PARSEDPushFcGWM_ECGtoIPC 1;
BA_ "GenSigSendType" SG_ 639 OfbChrgPrflUpdate_B_Rq 3;
BA_ "U_CD542_MY2021_Rx" SG_ 639 OfbChrgPrflUpdate_B_Rq 1;
BA_ "U_U55X_MY2022_Rx" SG_ 639 OfbChrgPrflUpdate_B_Rq 1;
BA_ "ECGUsedTxSignal" SG_ 639 OfbChrgPrflUpdate_B_Rq 1;
BA_ "U_CD542_MY2021_Tx" SG_ 639 OfbChrgPrflUpdate_B_Rq 1;
BA_ "U_U55X_MY2022_Tx" SG_ 639 OfbChrgPrflUpdate_B_Rq 1;
BA_ "GenSigSendType" SG_ 639 OfbChrgClearAll_B_Rq 3;
BA_ "ECGUsedTxSignal" SG_ 639 OfbChrgClearAll_B_Rq 1;
BA_ "U_CD542_MY2021_Tx" SG_ 639 OfbChrgClearAll_B_Rq 1;
BA_ "U_U55X_MY2022_Tx" SG_ 639 OfbChrgClearAll_B_Rq 1;
BA_ "GenSigSendType" SG_ 639 OfbChrgGoTTouch_D_Rq 3;
BA_ "ECGUsedTxSignal" SG_ 639 OfbChrgGoTTouch_D_Rq 1;
BA_ "U_CD542_MY2021_Tx" SG_ 639 OfbChrgGoTTouch_D_Rq 1;
BA_ "U_U55X_MY2022_Tx" SG_ 639 OfbChrgGoTTouch_D_Rq 1;
BA_ "ECGUsedTxSignal" SG_ 639 OfbChrgGoTPrcond_D_Rq 1;
BA_ "U_CD542_MY2021_Tx" SG_ 639 OfbChrgGoTPrcond_D_Rq 1;
BA_ "U_U55X_MY2022_Tx" SG_ 639 OfbChrgGoTPrcond_D_Rq 1;
BA_ "GenSigStartValueInteger" SG_ 639 OfbChrgGoTOn_D_Rq 2;
BA_ "GenSigSendType" SG_ 639 OfbChrgGoTOn_D_Rq 3;
BA_ "ECGUsedTxSignal" SG_ 639 OfbChrgGoTOn_D_Rq 1;
BA_ "U_CD542_MY2021_Tx" SG_ 639 OfbChrgGoTOn_D_Rq 1;
BA_ "U_U55X_MY2022_Tx" SG_ 639 OfbChrgGoTOn_D_Rq 1;
BA_ "ECGUsedTxSignal" SG_ 639 OfbChrgGoTMnte_D_Rq 1;
BA_ "U_CD542_MY2021_Tx" SG_ 639 OfbChrgGoTMnte_D_Rq 1;
BA_ "U_U55X_MY2022_Tx" SG_ 639 OfbChrgGoTMnte_D_Rq 1;
BA_ "GenSigStartValueInteger" SG_ 639 OfbChrgGoTHr_T_Rq 30;
BA_ "GenSigStartValue" SG_ 639 OfbChrgGoTHr_T_Rq 30;
BA_ "ECGUsedTxSignal" SG_ 639 OfbChrgGoTHr_T_Rq 1;
BA_ "U_CD542_MY2021_Tx" SG_ 639 OfbChrgGoTHr_T_Rq 1;
BA_ "U_U55X_MY2022_Tx" SG_ 639 OfbChrgGoTHr_T_Rq 1;
BA_ "GenSigSendType" SG_ 639 OfbChrgGoTExtHtr_D_Rq 3;
BA_ "ECGUsedTxSignal" SG_ 639 OfbChrgGoTExtHtr_D_Rq 1;
BA_ "U_CD542_MY2021_Tx" SG_ 639 OfbChrgGoTExtHtr_D_Rq 1;
BA_ "U_U55X_MY2022_Tx" SG_ 639 OfbChrgGoTExtHtr_D_Rq 1;
BA_ "GenSigSendType" SG_ 639 OfbChrgGoTElement_D_Rq 3;
BA_ "ECGUsedTxSignal" SG_ 639 OfbChrgGoTElement_D_Rq 1;
BA_ "U_CD542_MY2021_Tx" SG_ 639 OfbChrgGoTElement_D_Rq 1;
BA_ "U_U55X_MY2022_Tx" SG_ 639 OfbChrgGoTElement_D_Rq 1;
BA_ "ECGUsedTxSignal" SG_ 639 OfbChrgGoTDelete_B_Rq 1;
BA_ "U_CD542_MY2021_Tx" SG_ 639 OfbChrgGoTDelete_B_Rq 1;
BA_ "U_U55X_MY2022_Tx" SG_ 639 OfbChrgGoTDelete_B_Rq 1;
BA_ "GenSigSendType" SG_ 639 OfbChrgGoTUpdate_B_Rq 3;
BA_ "U_P702_MY2021_Rx" SG_ 639 OfbChrgGoTUpdate_B_Rq 1;
BA_ "U_CD542_MY2021_Rx" SG_ 639 OfbChrgGoTUpdate_B_Rq 1;
BA_ "U_U55X_MY2022_Rx" SG_ 639 OfbChrgGoTUpdate_B_Rq 1;
BA_ "ECGUsedTxSignal" SG_ 639 OfbChrgGoTUpdate_B_Rq 1;
BA_ "U_CD542_MY2021_Tx" SG_ 639 OfbChrgGoTUpdate_B_Rq 1;
BA_ "U_U55X_MY2022_Tx" SG_ 639 OfbChrgGoTUpdate_B_Rq 1;
BA_ "U_T6_MCA_MY2020_Rx" SG_ 419 MK_SpeedValue_Rq 1;
BA_ "U_CD542_MY2021_Rx" SG_ 419 MK_SpeedValue_Rq 1;
BA_ "U_U55X_MY2022_Rx" SG_ 419 MK_SpeedValue_Rq 1;
BA_ "U_T6_MCA_MY2020_Tx" SG_ 419 MK_SpeedValue_Rq 1;
BA_ "U_CD542_MY2021_Tx" SG_ 419 MK_SpeedValue_Rq 1;
BA_ "U_U55X_MY2022_Tx" SG_ 419 MK_SpeedValue_Rq 1;
BA_ "GenSigSendType" SG_ 419 MK_SpeedSetting_Rq 3;
BA_ "U_T6_MCA_MY2020_Rx" SG_ 419 MK_SpeedSetting_Rq 1;
BA_ "U_CD542_MY2021_Rx" SG_ 419 MK_SpeedSetting_Rq 1;
BA_ "U_U55X_MY2022_Rx" SG_ 419 MK_SpeedSetting_Rq 1;
BA_ "U_T6_MCA_MY2020_Tx" SG_ 419 MK_SpeedSetting_Rq 1;
BA_ "U_CD542_MY2021_Tx" SG_ 419 MK_SpeedSetting_Rq 1;
BA_ "U_U55X_MY2022_Tx" SG_ 419 MK_SpeedSetting_Rq 1;
BA_ "GenSigSendType" SG_ 419 MK_ResetAllUserKeys_Rq 3;
BA_ "U_T6_MCA_MY2020_Rx" SG_ 419 MK_ResetAllUserKeys_Rq 1;
BA_ "U_CD542_MY2021_Rx" SG_ 419 MK_ResetAllUserKeys_Rq 1;
BA_ "U_U55X_MY2022_Rx" SG_ 419 MK_ResetAllUserKeys_Rq 1;
BA_ "U_T6_MCA_MY2020_Tx" SG_ 419 MK_ResetAllUserKeys_Rq 1;
BA_ "U_CD542_MY2021_Tx" SG_ 419 MK_ResetAllUserKeys_Rq 1;
BA_ "U_U55X_MY2022_Tx" SG_ 419 MK_ResetAllUserKeys_Rq 1;
BA_ "GenSigSendType" SG_ 419 MK_MyKeySystemInfo_Rq 3;
BA_ "U_T6_MCA_MY2020_Rx" SG_ 419 MK_MyKeySystemInfo_Rq 1;
BA_ "U_CD542_MY2021_Rx" SG_ 419 MK_MyKeySystemInfo_Rq 1;
BA_ "U_U55X_MY2022_Rx" SG_ 419 MK_MyKeySystemInfo_Rq 1;
BA_ "U_T6_MCA_MY2020_Tx" SG_ 419 MK_MyKeySystemInfo_Rq 1;
BA_ "U_CD542_MY2021_Tx" SG_ 419 MK_MyKeySystemInfo_Rq 1;
BA_ "U_U55X_MY2022_Tx" SG_ 419 MK_MyKeySystemInfo_Rq 1;
BA_ "GenSigSendType" SG_ 419 MK_ESCRestrictConf_Rq 3;
BA_ "U_T6_MCA_MY2020_Rx" SG_ 419 MK_ESCRestrictConf_Rq 1;
BA_ "U_CD542_MY2021_Rx" SG_ 419 MK_ESCRestrictConf_Rq 1;
BA_ "U_U55X_MY2022_Rx" SG_ 419 MK_ESCRestrictConf_Rq 1;
BA_ "U_T6_MCA_MY2020_Tx" SG_ 419 MK_ESCRestrictConf_Rq 1;
BA_ "U_CD542_MY2021_Tx" SG_ 419 MK_ESCRestrictConf_Rq 1;
BA_ "U_U55X_MY2022_Tx" SG_ 419 MK_ESCRestrictConf_Rq 1;
BA_ "GenSigSendType" SG_ 419 MK_ECalRestrictConf_Rq 3;
BA_ "U_T6_MCA_MY2020_Rx" SG_ 419 MK_ECalRestrictConf_Rq 1;
BA_ "U_CD542_MY2021_Rx" SG_ 419 MK_ECalRestrictConf_Rq 1;
BA_ "U_U55X_MY2022_Rx" SG_ 419 MK_ECalRestrictConf_Rq 1;
BA_ "U_T6_MCA_MY2020_Tx" SG_ 419 MK_ECalRestrictConf_Rq 1;
BA_ "U_CD542_MY2021_Tx" SG_ 419 MK_ECalRestrictConf_Rq 1;
BA_ "U_U55X_MY2022_Tx" SG_ 419 MK_ECalRestrictConf_Rq 1;
BA_ "GenSigSendType" SG_ 419 MK_DNDRestrictConf_Rq 3;
BA_ "U_T6_MCA_MY2020_Rx" SG_ 419 MK_DNDRestrictConf_Rq 1;
BA_ "U_CD542_MY2021_Rx" SG_ 419 MK_DNDRestrictConf_Rq 1;
BA_ "U_U55X_MY2022_Rx" SG_ 419 MK_DNDRestrictConf_Rq 1;
BA_ "U_T6_MCA_MY2020_Tx" SG_ 419 MK_DNDRestrictConf_Rq 1;
BA_ "U_CD542_MY2021_Tx" SG_ 419 MK_DNDRestrictConf_Rq 1;
BA_ "U_U55X_MY2022_Tx" SG_ 419 MK_DNDRestrictConf_Rq 1;
BA_ "GenSigSendType" SG_ 419 MK_CreateMyKey_Rq 3;
BA_ "U_T6_MCA_MY2020_Rx" SG_ 419 MK_CreateMyKey_Rq 1;
BA_ "U_CD542_MY2021_Rx" SG_ 419 MK_CreateMyKey_Rq 1;
BA_ "U_U55X_MY2022_Rx" SG_ 419 MK_CreateMyKey_Rq 1;
BA_ "U_T6_MCA_MY2020_Tx" SG_ 419 MK_CreateMyKey_Rq 1;
BA_ "U_CD542_MY2021_Tx" SG_ 419 MK_CreateMyKey_Rq 1;
BA_ "U_U55X_MY2022_Tx" SG_ 419 MK_CreateMyKey_Rq 1;
BA_ "GenSigSendType" SG_ 419 MK_AudioLimitConfig_Rq 3;
BA_ "U_T6_MCA_MY2020_Rx" SG_ 419 MK_AudioLimitConfig_Rq 1;
BA_ "U_CD542_MY2021_Rx" SG_ 419 MK_AudioLimitConfig_Rq 1;
BA_ "U_U55X_MY2022_Rx" SG_ 419 MK_AudioLimitConfig_Rq 1;
BA_ "U_T6_MCA_MY2020_Tx" SG_ 419 MK_AudioLimitConfig_Rq 1;
BA_ "U_CD542_MY2021_Tx" SG_ 419 MK_AudioLimitConfig_Rq 1;
BA_ "U_U55X_MY2022_Tx" SG_ 419 MK_AudioLimitConfig_Rq 1;
BA_ "GenSigSendType" SG_ 419 MK_ACSRestrictConf_Rq 3;
BA_ "U_T6_MCA_MY2020_Rx" SG_ 419 MK_ACSRestrictConf_Rq 1;
BA_ "U_CD542_MY2021_Rx" SG_ 419 MK_ACSRestrictConf_Rq 1;
BA_ "U_U55X_MY2022_Rx" SG_ 419 MK_ACSRestrictConf_Rq 1;
BA_ "U_T6_MCA_MY2020_Tx" SG_ 419 MK_ACSRestrictConf_Rq 1;
BA_ "U_CD542_MY2021_Tx" SG_ 419 MK_ACSRestrictConf_Rq 1;
BA_ "U_U55X_MY2022_Tx" SG_ 419 MK_ACSRestrictConf_Rq 1;
BA_ "U_P702_MY2021_Rx" SG_ 542 LocationServices_3 1;
BA_ "U_T6_MCA_MY2020_Rx" SG_ 542 LocationServices_3 1;
BA_ "U_U55X_MY2022_Rx" SG_ 542 LocationServices_3 1;
BA_ "U_CD542_MY2021_Rx" SG_ 542 LocationServices_3 1;
BA_ "U_CD764_MY2022_Rx" SG_ 542 LocationServices_3 1;
BA_ "GenSigSendType" SG_ 554 SeatOccRearMsgTxt_B_Rq 3;
BA_ "U_CD764_MY2022_Rx" SG_ 554 SeatOccRearMsgTxt_B_Rq 1;
BA_ "ECGUsedTxSignal" SG_ 554 SeatOccRearMsgTxt_B_Rq 1;
BA_ "U_CD764_MY2022_Tx" SG_ 554 SeatOccRearMsgTxt_B_Rq 1;
BA_ "GenSigSendType" SG_ 554 DrvHazrdModel_D_St 3;
BA_ "U_CD764_MY2022_Rx" SG_ 554 DrvHazrdModel_D_St 1;
BA_ "U_T6_MCA_MY2020_Rx" SG_ 554 DrvHazrdModel_D_St 1;
BA_ "U_U55X_MY2022_Rx" SG_ 554 DrvHazrdModel_D_St 1;
BA_ "U_T6_MCA_MY2020_Tx" SG_ 554 DrvHazrdModel_D_St 1;
BA_ "ECGUsedTxSignal" SG_ 554 DrvHazrdModel_D_St 1;
BA_ "U_CD542_MY2021_Tx" SG_ 554 DrvHazrdModel_D_St 1;
BA_ "U_U55X_MY2022_Tx" SG_ 554 DrvHazrdModel_D_St 1;
BA_ "U_CD764_MY2022_Tx" SG_ 554 DrvHazrdModel_D_St 1;
BA_ "WakeupSignal" SG_ 554 PtWakeupActv1_B_Rq 1;
BA_ "GenSigSendType" SG_ 554 PtWakeupActv1_B_Rq 3;
BA_ "U_T6_MCA_MY2020_Rx" SG_ 554 PtWakeupActv1_B_Rq 1;
BA_ "U_CD542_MY2021_Rx" SG_ 554 PtWakeupActv1_B_Rq 1;
BA_ "U_U55X_MY2022_Rx" SG_ 554 PtWakeupActv1_B_Rq 1;
BA_ "ECGUsedTxSignal" SG_ 554 PtWakeupActv1_B_Rq 1;
BA_ "U_CD542_MY2021_Tx" SG_ 554 PtWakeupActv1_B_Rq 1;
BA_ "U_U55X_MY2022_Tx" SG_ 554 PtWakeupActv1_B_Rq 1;
BA_ "U_CD764_MY2022_Tx" SG_ 554 PtWakeupActv1_B_Rq 1;
BA_ "GenSigSendType" SG_ 554 DrvHazrd_D_St 3;
BA_ "U_T6_MCA_MY2020_Rx" SG_ 554 DrvHazrd_D_St 1;
BA_ "U_CD764_MY2022_Rx" SG_ 554 DrvHazrd_D_St 1;
BA_ "U_U55X_MY2022_Rx" SG_ 554 DrvHazrd_D_St 1;
BA_ "U_T6_MCA_MY2020_Tx" SG_ 554 DrvHazrd_D_St 1;
BA_ "ECGUsedTxSignal" SG_ 554 DrvHazrd_D_St 1;
BA_ "U_CD542_MY2021_Tx" SG_ 554 DrvHazrd_D_St 1;
BA_ "U_U55X_MY2022_Tx" SG_ 554 DrvHazrd_D_St 1;
BA_ "U_CD764_MY2022_Tx" SG_ 554 DrvHazrd_D_St 1;
BA_ "GenSigSendType" SG_ 494 HEC_TUPresetArea_Rq 3;
BA_ "U_T6_MCA_MY2020_Rx" SG_ 494 HEC_TUPresetArea_Rq 1;
BA_ "U_U55X_MY2022_Rx" SG_ 494 HEC_TUPresetArea_Rq 1;
BA_ "U_CD764_MY2022_Rx" SG_ 494 HEC_TUPresetArea_Rq 1;
BA_ "U_T6_MCA_MY2020_Tx" SG_ 494 HEC_TUPresetArea_Rq 1;
BA_ "U_U55X_MY2022_Tx" SG_ 494 HEC_TUPresetArea_Rq 1;
BA_ "GenSigSendType" SG_ 494 Mc_SetCurrPreset2_Rq 3;
BA_ "U_T6_MCA_MY2020_Rx" SG_ 494 Mc_SetCurrPreset2_Rq 1;
BA_ "U_U55X_MY2022_Rx" SG_ 494 Mc_SetCurrPreset2_Rq 1;
BA_ "U_CD764_MY2022_Rx" SG_ 494 Mc_SetCurrPreset2_Rq 1;
BA_ "U_T6_MCA_MY2020_Tx" SG_ 494 Mc_SetCurrPreset2_Rq 1;
BA_ "U_U55X_MY2022_Tx" SG_ 494 Mc_SetCurrPreset2_Rq 1;
BA_ "U_T6_MCA_MY2020_Rx" SG_ 494 HEC_TUNbrOfPresets_Rq 1;
BA_ "U_U55X_MY2022_Rx" SG_ 494 HEC_TUNbrOfPresets_Rq 1;
BA_ "U_CD764_MY2022_Rx" SG_ 494 HEC_TUNbrOfPresets_Rq 1;
BA_ "U_T6_MCA_MY2020_Tx" SG_ 494 HEC_TUNbrOfPresets_Rq 1;
BA_ "U_U55X_MY2022_Tx" SG_ 494 HEC_TUNbrOfPresets_Rq 1;
BA_ "GenSigSendType" SG_ 494 HEC_SetCurrTUBand_Rq 3;
BA_ "U_T6_MCA_MY2020_Rx" SG_ 494 HEC_SetCurrTUBand_Rq 1;
BA_ "U_U55X_MY2022_Rx" SG_ 494 HEC_SetCurrTUBand_Rq 1;
BA_ "U_CD764_MY2022_Rx" SG_ 494 HEC_SetCurrTUBand_Rq 1;
BA_ "U_T6_MCA_MY2020_Tx" SG_ 494 HEC_SetCurrTUBand_Rq 1;
BA_ "U_U55X_MY2022_Tx" SG_ 494 HEC_SetCurrTUBand_Rq 1;
BA_ "U_T6_MCA_MY2020_Rx" SG_ 494 HEC_TUStartIndex2_Rq 1;
BA_ "U_U55X_MY2022_Rx" SG_ 494 HEC_TUStartIndex2_Rq 1;
BA_ "U_CD764_MY2022_Rx" SG_ 494 HEC_TUStartIndex2_Rq 1;
BA_ "U_T6_MCA_MY2020_Tx" SG_ 494 HEC_TUStartIndex2_Rq 1;
BA_ "U_U55X_MY2022_Tx" SG_ 494 HEC_TUStartIndex2_Rq 1;
BA_ "U_T6_MCA_MY2020_Rx" SG_ 498 HEC_ARReqstrPriority_Rq 1;
BA_ "U_U55X_MY2022_Rx" SG_ 498 HEC_ARReqstrPriority_Rq 1;
BA_ "U_CD764_MY2022_Rx" SG_ 498 HEC_ARReqstrPriority_Rq 1;
BA_ "U_T6_MCA_MY2020_Tx" SG_ 498 HEC_ARReqstrPriority_Rq 1;
BA_ "U_CD542_MY2021_Tx" SG_ 498 HEC_ARReqstrPriority_Rq 1;
BA_ "U_U55X_MY2022_Tx" SG_ 498 HEC_ARReqstrPriority_Rq 1;
BA_ "GenSigSendType" SG_ 498 HEC_AROperationType_Rq 3;
BA_ "U_T6_MCA_MY2020_Rx" SG_ 498 HEC_AROperationType_Rq 1;
BA_ "U_U55X_MY2022_Rx" SG_ 498 HEC_AROperationType_Rq 1;
BA_ "U_CD764_MY2022_Rx" SG_ 498 HEC_AROperationType_Rq 1;
BA_ "U_T6_MCA_MY2020_Tx" SG_ 498 HEC_AROperationType_Rq 1;
BA_ "U_CD542_MY2021_Tx" SG_ 498 HEC_AROperationType_Rq 1;
BA_ "U_U55X_MY2022_Tx" SG_ 498 HEC_AROperationType_Rq 1;
BA_ "U_T6_MCA_MY2020_Rx" SG_ 498 HEC_ARReqstrSystem_Rq 1;
BA_ "U_U55X_MY2022_Rx" SG_ 498 HEC_ARReqstrSystem_Rq 1;
BA_ "U_CD764_MY2022_Rx" SG_ 498 HEC_ARReqstrSystem_Rq 1;
BA_ "U_T6_MCA_MY2020_Tx" SG_ 498 HEC_ARReqstrSystem_Rq 1;
BA_ "U_CD542_MY2021_Tx" SG_ 498 HEC_ARReqstrSystem_Rq 1;
BA_ "U_U55X_MY2022_Tx" SG_ 498 HEC_ARReqstrSystem_Rq 1;
BA_ "U_T6_MCA_MY2020_Rx" SG_ 498 HEC_ARAudioSource_Rq 1;
BA_ "U_U55X_MY2022_Rx" SG_ 498 HEC_ARAudioSource_Rq 1;
BA_ "U_CD764_MY2022_Rx" SG_ 498 HEC_ARAudioSource_Rq 1;
BA_ "U_T6_MCA_MY2020_Tx" SG_ 498 HEC_ARAudioSource_Rq 1;
BA_ "U_CD542_MY2021_Tx" SG_ 498 HEC_ARAudioSource_Rq 1;
BA_ "U_U55X_MY2022_Tx" SG_ 498 HEC_ARAudioSource_Rq 1;
BA_ "U_T6_MCA_MY2020_Rx" SG_ 644 VehOnSrc_D_Stat_UB 1;
BA_ "U_U55X_MY2022_Rx" SG_ 644 VehOnSrc_D_Stat_UB 1;
BA_ "U_CD764_MY2022_Rx" SG_ 644 VehOnSrc_D_Stat_UB 1;
BA_ "U_CD542_MY2021_Rx" SG_ 644 VehOnSrc_D_Stat_UB 1;
BA_ "U_T6_MCA_MY2020_Rx" SG_ 644 VehOnSrc_D_Stat 1;
BA_ "U_U55X_MY2022_Rx" SG_ 644 VehOnSrc_D_Stat 1;
BA_ "U_CD764_MY2022_Rx" SG_ 644 VehOnSrc_D_Stat 1;
BA_ "U_CD542_MY2021_Rx" SG_ 644 VehOnSrc_D_Stat 1;
BA_ "U_T6_MCA_MY2020_Rx" SG_ 643 StrtInGearMsgTxt_D_Rq_UB 1;
BA_ "U_CD764_MY2022_Rx" SG_ 643 StrtInGearMsgTxt_D_Rq_UB 1;
BA_ "GenSigSendType" SG_ 643 StrtInGearMsgTxt_D_Rq 3;
BA_ "U_T6_MCA_MY2020_Rx" SG_ 643 StrtInGearMsgTxt_D_Rq 1;
BA_ "U_CD764_MY2022_Rx" SG_ 643 StrtInGearMsgTxt_D_Rq 1;
BA_ "U_T6_MCA_MY2020_Rx" SG_ 643 StabBarCnnct_D_Stat_UB 1;
BA_ "U_U55X_MY2022_Rx" SG_ 643 StabBarCnnct_D_Stat_UB 1;
BA_ "U_CD764_MY2022_Rx" SG_ 643 StabBarCnnct_D_Stat_UB 1;
BA_ "GenSigSendType" SG_ 643 StabBarCnnct_D_Stat 3;
BA_ "U_T6_MCA_MY2020_Rx" SG_ 643 StabBarCnnct_D_Stat 1;
BA_ "U_U55X_MY2022_Rx" SG_ 643 StabBarCnnct_D_Stat 1;
BA_ "U_CD764_MY2022_Rx" SG_ 643 StabBarCnnct_D_Stat 1;
BA_ "U_T6_MCA_MY2020_Rx" SG_ 643 FstChrgCmplt_T_Est 1;
BA_ "U_CD764_MY2022_Rx" SG_ 643 FstChrgCmplt_T_Est 1;
BA_ "U_CD542_MY2021_Rx" SG_ 643 FstChrgCmplt_T_Est 1;
BA_ "U_U55X_MY2022_Rx" SG_ 643 FstChrgCmplt_T_Est 1;
BA_ "U_T6_MCA_MY2020_Rx" SG_ 643 GearPos_D_Trg_UB 1;
BA_ "U_CD542_MY2021_Rx" SG_ 643 GearPos_D_Trg_UB 1;
BA_ "U_U55X_MY2022_Rx" SG_ 643 GearPos_D_Trg_UB 1;
BA_ "U_CD764_MY2022_Rx" SG_ 643 GearPos_D_Trg_UB 1;
BA_ "GenSigStartValueInteger" SG_ 643 GearPos_D_Trg 15;
BA_ "ContentDependant" SG_ 643 GearPos_D_Trg 1;
BA_ "GenSigStartValue" SG_ 643 GearPos_D_Trg 15;
BA_ "GenSigSendType" SG_ 643 GearPos_D_Trg 3;
BA_ "U_T6_MCA_MY2020_Rx" SG_ 643 GearPos_D_Trg 1;
BA_ "U_CD542_MY2021_Rx" SG_ 643 GearPos_D_Trg 1;
BA_ "U_U55X_MY2022_Rx" SG_ 643 GearPos_D_Trg 1;
BA_ "U_CD764_MY2022_Rx" SG_ 643 GearPos_D_Trg 1;
BA_ "GenSigSendType" SG_ 643 PwTgateStepMsgTxt_B_Rq 3;
BA_ "U_T6_MCA_MY2020_Rx" SG_ 643 PwTgateStepMsgTxt_B_Rq 1;
BA_ "U_U55X_MY2022_Rx" SG_ 643 PwTgateStepMsgTxt_B_Rq 1;
BA_ "U_CD764_MY2022_Rx" SG_ 643 PwTgateStepMsgTxt_B_Rq 1;
BA_ "U_T6_MCA_MY2020_Rx" SG_ 643 PwTgateStepMsgTxt_B_Rq_UB 1;
BA_ "U_U55X_MY2022_Rx" SG_ 643 PwTgateStepMsgTxt_B_Rq_UB 1;
BA_ "U_CD764_MY2022_Rx" SG_ 643 PwTgateStepMsgTxt_B_Rq_UB 1;
BA_ "U_T6_MCA_MY2020_Rx" SG_ 643 PwTgateMsgTxt_B_Rq_UB 1;
BA_ "U_U55X_MY2022_Rx" SG_ 643 PwTgateMsgTxt_B_Rq_UB 1;
BA_ "U_CD764_MY2022_Rx" SG_ 643 PwTgateMsgTxt_B_Rq_UB 1;
BA_ "U_T6_MCA_MY2020_Rx" SG_ 643 PwTgateLamp_B_Rq_UB 1;
BA_ "U_U55X_MY2022_Rx" SG_ 643 PwTgateLamp_B_Rq_UB 1;
BA_ "U_CD764_MY2022_Rx" SG_ 643 PwTgateLamp_B_Rq_UB 1;
BA_ "GenSigSendType" SG_ 643 PwTgateMsgTxt_B_Rq 3;
BA_ "U_T6_MCA_MY2020_Rx" SG_ 643 PwTgateMsgTxt_B_Rq 1;
BA_ "U_U55X_MY2022_Rx" SG_ 643 PwTgateMsgTxt_B_Rq 1;
BA_ "U_CD764_MY2022_Rx" SG_ 643 PwTgateMsgTxt_B_Rq 1;
BA_ "GenSigSendType" SG_ 643 PwTgateLamp_B_Rq 3;
BA_ "U_T6_MCA_MY2020_Rx" SG_ 643 PwTgateLamp_B_Rq 1;
BA_ "U_U55X_MY2022_Rx" SG_ 643 PwTgateLamp_B_Rq 1;
BA_ "U_CD764_MY2022_Rx" SG_ 643 PwTgateLamp_B_Rq 1;
BA_ "U_T6_MCA_MY2020_Rx" SG_ 643 PwRnngBoardSwtch_D_Stat_UB 1;
BA_ "U_U55X_MY2022_Rx" SG_ 643 PwRnngBoardSwtch_D_Stat_UB 1;
BA_ "U_CD764_MY2022_Rx" SG_ 643 PwRnngBoardSwtch_D_Stat_UB 1;
BA_ "U_CD542_MY2021_Rx" SG_ 643 PwRnngBoardSwtch_D_Stat_UB 1;
BA_ "U_T6_MCA_MY2020_Rx" SG_ 643 PwRnngBoardT_D_Stat_UB 1;
BA_ "U_U55X_MY2022_Rx" SG_ 643 PwRnngBoardT_D_Stat_UB 1;
BA_ "U_CD764_MY2022_Rx" SG_ 643 PwRnngBoardT_D_Stat_UB 1;
BA_ "U_CD542_MY2021_Rx" SG_ 643 PwRnngBoardT_D_Stat_UB 1;
BA_ "GenSigSendType" SG_ 643 PwRnngBoardT_D_Stat 3;
BA_ "U_T6_MCA_MY2020_Rx" SG_ 643 PwRnngBoardT_D_Stat 1;
BA_ "U_U55X_MY2022_Rx" SG_ 643 PwRnngBoardT_D_Stat 1;
BA_ "U_CD764_MY2022_Rx" SG_ 643 PwRnngBoardT_D_Stat 1;
BA_ "U_CD542_MY2021_Rx" SG_ 643 PwRnngBoardT_D_Stat 1;
BA_ "GenSigSendType" SG_ 643 PwRnngBoardSwtch_D_Stat 3;
BA_ "U_T6_MCA_MY2020_Rx" SG_ 643 PwRnngBoardSwtch_D_Stat 1;
BA_ "U_CD542_MY2021_Rx" SG_ 643 PwRnngBoardSwtch_D_Stat 1;
BA_ "U_U55X_MY2022_Rx" SG_ 643 PwRnngBoardSwtch_D_Stat 1;
BA_ "U_CD764_MY2022_Rx" SG_ 643 PwRnngBoardSwtch_D_Stat 1;
BA_ "U_T6_MCA_MY2020_Rx" SG_ 643 OnePdlDrvLamp_B_Rq_UB 1;
BA_ "U_CD764_MY2022_Rx" SG_ 643 OnePdlDrvLamp_B_Rq_UB 1;
BA_ "U_CD542_MY2021_Rx" SG_ 643 OnePdlDrv_D_Dsply_UB 1;
BA_ "U_U55X_MY2022_Rx" SG_ 643 OnePdlDrv_D_Dsply_UB 1;
BA_ "U_T6_MCA_MY2020_Rx" SG_ 643 OnePdlDrv_D_Dsply_UB 1;
BA_ "U_CD764_MY2022_Rx" SG_ 643 OnePdlDrv_D_Dsply_UB 1;
BA_ "GenSigSendType" SG_ 643 OnePdlDrvLamp_B_Rq 3;
BA_ "U_T6_MCA_MY2020_Rx" SG_ 643 OnePdlDrvLamp_B_Rq 1;
BA_ "U_CD764_MY2022_Rx" SG_ 643 OnePdlDrvLamp_B_Rq 1;
BA_ "GenSigSendType" SG_ 643 OnePdlDrv_D_Dsply 3;
BA_ "U_CD542_MY2021_Rx" SG_ 643 OnePdlDrv_D_Dsply 1;
BA_ "U_U55X_MY2022_Rx" SG_ 643 OnePdlDrv_D_Dsply 1;
BA_ "U_T6_MCA_MY2020_Rx" SG_ 643 OnePdlDrv_D_Dsply 1;
BA_ "U_CD764_MY2022_Rx" SG_ 643 OnePdlDrv_D_Dsply 1;
BA_ "U_CD764_MY2022_Rx" SG_ 643 SeatSlprPosMsgTxt_B_Rq_UB 1;
BA_ "GenSigSendType" SG_ 643 SeatSlprPosMsgTxt_B_Rq 3;
BA_ "U_CD764_MY2022_Rx" SG_ 643 SeatSlprPosMsgTxt_B_Rq 1;
BA_ "U_T6_MCA_MY2020_Rx" SG_ 643 DrPrsntRearPsngr_D_Stat_UB 1;
BA_ "U_CD764_MY2022_Rx" SG_ 643 DrPrsntRearPsngr_D_Stat_UB 1;
BA_ "U_CD764_MY2022_Rx" SG_ 643 DrPrsntPsngr_D_Stat_UB 1;
BA_ "U_T6_MCA_MY2020_Rx" SG_ 643 DrPsngrMsgTxt_B_Rq_UB 1;
BA_ "U_CD764_MY2022_Rx" SG_ 643 DrPsngrMsgTxt_B_Rq_UB 1;
BA_ "GenSigSendType" SG_ 643 DrPsngrMsgTxt_B_Rq 3;
BA_ "U_T6_MCA_MY2020_Rx" SG_ 643 DrPsngrMsgTxt_B_Rq 1;
BA_ "U_CD764_MY2022_Rx" SG_ 643 DrPsngrMsgTxt_B_Rq 1;
BA_ "WakeupSignal" SG_ 643 DrPrsntRearPsngr_D_Stat 1;
BA_ "GenSigSendType" SG_ 643 DrPrsntRearPsngr_D_Stat 3;
BA_ "U_T6_MCA_MY2020_Rx" SG_ 643 DrPrsntRearPsngr_D_Stat 1;
BA_ "U_CD764_MY2022_Rx" SG_ 643 DrPrsntRearPsngr_D_Stat 1;
BA_ "WakeupSignal" SG_ 643 DrPrsntPsngr_D_Stat 1;
BA_ "GenSigSendType" SG_ 643 DrPrsntPsngr_D_Stat 3;
BA_ "U_CD764_MY2022_Rx" SG_ 643 DrPrsntPsngr_D_Stat 1;
BA_ "U_T6_MCA_MY2020_Rx" SG_ 643 DrPrsntRearDrv_D_Stat_UB 1;
BA_ "U_CD764_MY2022_Rx" SG_ 643 DrPrsntRearDrv_D_Stat_UB 1;
BA_ "U_T6_MCA_MY2020_Rx" SG_ 643 DrDrvMsgTxt_B_Rq_UB 1;
BA_ "U_CD764_MY2022_Rx" SG_ 643 DrDrvMsgTxt_B_Rq_UB 1;
BA_ "U_T6_MCA_MY2020_Rx" SG_ 643 DrPrsntDrv_D_Stat_UB 1;
BA_ "U_CD764_MY2022_Rx" SG_ 643 DrPrsntDrv_D_Stat_UB 1;
BA_ "WakeupSignal" SG_ 643 DrPrsntDrv_D_Stat 1;
BA_ "GenSigSendType" SG_ 643 DrPrsntDrv_D_Stat 3;
BA_ "U_T6_MCA_MY2020_Rx" SG_ 643 DrPrsntDrv_D_Stat 1;
BA_ "U_CD764_MY2022_Rx" SG_ 643 DrPrsntDrv_D_Stat 1;
BA_ "WakeupSignal" SG_ 643 DrPrsntRearDrv_D_Stat 1;
BA_ "GenSigSendType" SG_ 643 DrPrsntRearDrv_D_Stat 3;
BA_ "U_T6_MCA_MY2020_Rx" SG_ 643 DrPrsntRearDrv_D_Stat 1;
BA_ "U_CD764_MY2022_Rx" SG_ 643 DrPrsntRearDrv_D_Stat 1;
BA_ "GenSigSendType" SG_ 643 DrDrvMsgTxt_B_Rq 3;
BA_ "U_T6_MCA_MY2020_Rx" SG_ 643 DrDrvMsgTxt_B_Rq 1;
BA_ "U_CD764_MY2022_Rx" SG_ 643 DrDrvMsgTxt_B_Rq 1;
BA_ "U_T6_MCA_MY2020_Rx" SG_ 643 FstChrgCmplt_T_Est_UB 1;
BA_ "U_CD764_MY2022_Rx" SG_ 643 FstChrgCmplt_T_Est_UB 1;
BA_ "U_CD542_MY2021_Rx" SG_ 643 FstChrgCmplt_T_Est_UB 1;
BA_ "U_U55X_MY2022_Rx" SG_ 643 FstChrgCmplt_T_Est_UB 1;
BA_ "U_T6_MCA_MY2020_Rx" SG_ 643 TrunkFrontOpen_D_Stat_UB 1;
BA_ "U_CD542_MY2021_Rx" SG_ 643 TrunkFrontOpen_D_Stat_UB 1;
BA_ "U_U55X_MY2022_Rx" SG_ 643 TrunkFrontOpen_D_Stat_UB 1;
BA_ "WakeupSignal" SG_ 643 TrunkFrontOpen_D_Stat 1;
BA_ "GenSigStartValue" SG_ 643 TrunkFrontOpen_D_Stat 2;
BA_ "GenSigSendType" SG_ 643 TrunkFrontOpen_D_Stat 3;
BA_ "U_T6_MCA_MY2020_Rx" SG_ 643 TrunkFrontOpen_D_Stat 1;
BA_ "U_CD542_MY2021_Rx" SG_ 643 TrunkFrontOpen_D_Stat 1;
BA_ "U_U55X_MY2022_Rx" SG_ 643 TrunkFrontOpen_D_Stat 1;
BA_ "U_U55X_MY2022_Rx" SG_ 145 MFD_Year 1;
BA_ "U_T6_MCA_MY2020_Rx" SG_ 145 MFD_Year 1;
BA_ "U_T6_MCA_MY2020_Tx" SG_ 145 MFD_Year 1;
BA_ "U_CD542_MY2021_Tx" SG_ 145 MFD_Year 1;
BA_ "U_U55X_MY2022_Tx" SG_ 145 MFD_Year 1;
BA_ "U_CD764_MY2022_Tx" SG_ 145 MFD_Year 1;
BA_ "GenSigSendType" SG_ 145 MFD_Second 3;
BA_ "U_U55X_MY2022_Rx" SG_ 145 MFD_Second 1;
BA_ "U_T6_MCA_MY2020_Rx" SG_ 145 MFD_Second 1;
BA_ "U_T6_MCA_MY2020_Tx" SG_ 145 MFD_Second 1;
BA_ "U_CD542_MY2021_Tx" SG_ 145 MFD_Second 1;
BA_ "U_U55X_MY2022_Tx" SG_ 145 MFD_Second 1;
BA_ "U_CD764_MY2022_Tx" SG_ 145 MFD_Second 1;
BA_ "U_U55X_MY2022_Rx" SG_ 145 MFD_Month 1;
BA_ "U_T6_MCA_MY2020_Rx" SG_ 145 MFD_Month 1;
BA_ "U_T6_MCA_MY2020_Tx" SG_ 145 MFD_Month 1;
BA_ "U_CD542_MY2021_Tx" SG_ 145 MFD_Month 1;
BA_ "U_U55X_MY2022_Tx" SG_ 145 MFD_Month 1;
BA_ "U_CD764_MY2022_Tx" SG_ 145 MFD_Month 1;
BA_ "U_U55X_MY2022_Rx" SG_ 145 MFD_Minute 1;
BA_ "U_T6_MCA_MY2020_Rx" SG_ 145 MFD_Minute 1;
BA_ "U_T6_MCA_MY2020_Tx" SG_ 145 MFD_Minute 1;
BA_ "U_CD542_MY2021_Tx" SG_ 145 MFD_Minute 1;
BA_ "U_U55X_MY2022_Tx" SG_ 145 MFD_Minute 1;
BA_ "U_CD764_MY2022_Tx" SG_ 145 MFD_Minute 1;
BA_ "U_U55X_MY2022_Rx" SG_ 145 MFD_Hour 1;
BA_ "U_T6_MCA_MY2020_Rx" SG_ 145 MFD_Hour 1;
BA_ "U_T6_MCA_MY2020_Tx" SG_ 145 MFD_Hour 1;
BA_ "U_CD542_MY2021_Tx" SG_ 145 MFD_Hour 1;
BA_ "U_U55X_MY2022_Tx" SG_ 145 MFD_Hour 1;
BA_ "U_CD764_MY2022_Tx" SG_ 145 MFD_Hour 1;
BA_ "U_U55X_MY2022_Rx" SG_ 145 MFD_Day 1;
BA_ "U_T6_MCA_MY2020_Rx" SG_ 145 MFD_Day 1;
BA_ "U_T6_MCA_MY2020_Tx" SG_ 145 MFD_Day 1;
BA_ "U_CD542_MY2021_Tx" SG_ 145 MFD_Day 1;
BA_ "U_U55X_MY2022_Tx" SG_ 145 MFD_Day 1;
BA_ "U_CD764_MY2022_Tx" SG_ 145 MFD_Day 1;
BA_ "U_T6_MCA_MY2020_Rx" SG_ 841 FohStrtDateDay_No_Stat 1;
BA_ "U_T6_MCA_MY2020_Rx" SG_ 841 FohStrtDateYr_No_Stat 1;
BA_ "U_T6_MCA_MY2020_Rx" SG_ 841 FohAddHeater_D_Stat 1;
BA_ "GenSigSendType" SG_ 545 SpkrDgtlRight_D_Stat 3;
BA_ "U_P702_MY2021_Tx" SG_ 545 SpkrDgtlRight_D_Stat 1;
BA_ "U_T6_MCA_MY2020_Tx" SG_ 545 SpkrDgtlRight_D_Stat 1;
BA_ "U_CD542_MY2021_Tx" SG_ 545 SpkrDgtlRight_D_Stat 1;
BA_ "U_U55X_MY2022_Tx" SG_ 545 SpkrDgtlRight_D_Stat 1;
BA_ "U_CD764_MY2022_Tx" SG_ 545 SpkrDgtlRight_D_Stat 1;
BA_ "GenSigSendType" SG_ 545 SpkrDgtlLeft_D_Stat 3;
BA_ "U_P702_MY2021_Tx" SG_ 545 SpkrDgtlLeft_D_Stat 1;
BA_ "U_T6_MCA_MY2020_Tx" SG_ 545 SpkrDgtlLeft_D_Stat 1;
BA_ "U_CD542_MY2021_Tx" SG_ 545 SpkrDgtlLeft_D_Stat 1;
BA_ "U_U55X_MY2022_Tx" SG_ 545 SpkrDgtlLeft_D_Stat 1;
BA_ "U_CD764_MY2022_Tx" SG_ 545 SpkrDgtlLeft_D_Stat 1;
BA_ "GenSigSendType" SG_ 545 SpkrDgtlCntr_D_Stat 3;
BA_ "U_T6_MCA_MY2020_Rx" SG_ 545 SpkrDgtlCntr_D_Stat 1;
BA_ "U_CD764_MY2022_Rx" SG_ 545 SpkrDgtlCntr_D_Stat 1;
BA_ "U_P702_MY2021_Tx" SG_ 545 SpkrDgtlCntr_D_Stat 1;
BA_ "U_T6_MCA_MY2020_Tx" SG_ 545 SpkrDgtlCntr_D_Stat 1;
BA_ "U_CD542_MY2021_Tx" SG_ 545 SpkrDgtlCntr_D_Stat 1;
BA_ "U_U55X_MY2022_Tx" SG_ 545 SpkrDgtlCntr_D_Stat 1;
BA_ "U_CD764_MY2022_Tx" SG_ 545 SpkrDgtlCntr_D_Stat 1;
BA_ "GenSigSendType" SG_ 545 SurndSndUpmix2_D_Stat 3;
BA_ "U_P702_MY2021_Rx" SG_ 545 SurndSndUpmix2_D_Stat 1;
BA_ "U_T6_MCA_MY2020_Rx" SG_ 545 SurndSndUpmix2_D_Stat 1;
BA_ "U_CD542_MY2021_Rx" SG_ 545 SurndSndUpmix2_D_Stat 1;
BA_ "U_U55X_MY2022_Rx" SG_ 545 SurndSndUpmix2_D_Stat 1;
BA_ "U_CD764_MY2022_Rx" SG_ 545 SurndSndUpmix2_D_Stat 1;
BA_ "U_P702_MY2021_Tx" SG_ 545 SurndSndUpmix2_D_Stat 1;
BA_ "U_T6_MCA_MY2020_Tx" SG_ 545 SurndSndUpmix2_D_Stat 1;
BA_ "U_CD542_MY2021_Tx" SG_ 545 SurndSndUpmix2_D_Stat 1;
BA_ "U_U55X_MY2022_Tx" SG_ 545 SurndSndUpmix2_D_Stat 1;
BA_ "U_CD764_MY2022_Tx" SG_ 545 SurndSndUpmix2_D_Stat 1;
BA_ "GenSigSendType" SG_ 545 DSP_Bezel_Diag_St 3;
BA_ "U_P702_MY2021_Rx" SG_ 545 DSP_Bezel_Diag_St 1;
BA_ "U_T6_MCA_MY2020_Rx" SG_ 545 DSP_Bezel_Diag_St 1;
BA_ "U_CD542_MY2021_Rx" SG_ 545 DSP_Bezel_Diag_St 1;
BA_ "U_U55X_MY2022_Rx" SG_ 545 DSP_Bezel_Diag_St 1;
BA_ "U_CD764_MY2022_Rx" SG_ 545 DSP_Bezel_Diag_St 1;
BA_ "U_T6_MCA_MY2020_Tx" SG_ 545 DSP_Bezel_Diag_St 1;
BA_ "U_CD542_MY2021_Tx" SG_ 545 DSP_Bezel_Diag_St 1;
BA_ "U_U55X_MY2022_Tx" SG_ 545 DSP_Bezel_Diag_St 1;
BA_ "U_CD764_MY2022_Tx" SG_ 545 DSP_Bezel_Diag_St 1;
BA_ "GenSigSendType" SG_ 545 SndImmrsnLvl_D_Stat 3;
BA_ "U_P702_MY2021_Rx" SG_ 545 SndImmrsnLvl_D_Stat 1;
BA_ "U_T6_MCA_MY2020_Rx" SG_ 545 SndImmrsnLvl_D_Stat 1;
BA_ "U_CD542_MY2021_Rx" SG_ 545 SndImmrsnLvl_D_Stat 1;
BA_ "U_U55X_MY2022_Rx" SG_ 545 SndImmrsnLvl_D_Stat 1;
BA_ "U_CD764_MY2022_Rx" SG_ 545 SndImmrsnLvl_D_Stat 1;
BA_ "U_P702_MY2021_Tx" SG_ 545 SndImmrsnLvl_D_Stat 1;
BA_ "U_T6_MCA_MY2020_Tx" SG_ 545 SndImmrsnLvl_D_Stat 1;
BA_ "U_CD542_MY2021_Tx" SG_ 545 SndImmrsnLvl_D_Stat 1;
BA_ "U_U55X_MY2022_Tx" SG_ 545 SndImmrsnLvl_D_Stat 1;
BA_ "U_CD764_MY2022_Tx" SG_ 545 SndImmrsnLvl_D_Stat 1;
BA_ "GenSigSendType" SG_ 545 DSP_Sur_Sound_st 3;
BA_ "U_P702_MY2021_Rx" SG_ 545 DSP_Sur_Sound_st 1;
BA_ "U_T6_MCA_MY2020_Rx" SG_ 545 DSP_Sur_Sound_st 1;
BA_ "U_CD542_MY2021_Rx" SG_ 545 DSP_Sur_Sound_st 1;
BA_ "U_U55X_MY2022_Rx" SG_ 545 DSP_Sur_Sound_st 1;
BA_ "U_CD764_MY2022_Rx" SG_ 545 DSP_Sur_Sound_st 1;
BA_ "U_P702_MY2021_Tx" SG_ 545 DSP_Sur_Sound_st 1;
BA_ "U_T6_MCA_MY2020_Tx" SG_ 545 DSP_Sur_Sound_st 1;
BA_ "U_CD542_MY2021_Tx" SG_ 545 DSP_Sur_Sound_st 1;
BA_ "U_U55X_MY2022_Tx" SG_ 545 DSP_Sur_Sound_st 1;
BA_ "U_CD764_MY2022_Tx" SG_ 545 DSP_Sur_Sound_st 1;
BA_ "GenSigSendType" SG_ 545 DSP_MyKeyVolLimitUp_St 3;
BA_ "U_P702_MY2021_Rx" SG_ 545 DSP_MyKeyVolLimitUp_St 1;
BA_ "U_T6_MCA_MY2020_Rx" SG_ 545 DSP_MyKeyVolLimitUp_St 1;
BA_ "U_CD542_MY2021_Rx" SG_ 545 DSP_MyKeyVolLimitUp_St 1;
BA_ "U_U55X_MY2022_Rx" SG_ 545 DSP_MyKeyVolLimitUp_St 1;
BA_ "U_P702_MY2021_Tx" SG_ 545 DSP_MyKeyVolLimitUp_St 1;
BA_ "U_T6_MCA_MY2020_Tx" SG_ 545 DSP_MyKeyVolLimitUp_St 1;
BA_ "U_CD542_MY2021_Tx" SG_ 545 DSP_MyKeyVolLimitUp_St 1;
BA_ "U_U55X_MY2022_Tx" SG_ 545 DSP_MyKeyVolLimitUp_St 1;
BA_ "U_CD764_MY2022_Tx" SG_ 545 DSP_MyKeyVolLimitUp_St 1;
BA_ "GenSigSendType" SG_ 545 DSP_MyKeyVolLim_St 3;
BA_ "U_P702_MY2021_Rx" SG_ 545 DSP_MyKeyVolLim_St 1;
BA_ "U_T6_MCA_MY2020_Rx" SG_ 545 DSP_MyKeyVolLim_St 1;
BA_ "U_CD542_MY2021_Rx" SG_ 545 DSP_MyKeyVolLim_St 1;
BA_ "U_U55X_MY2022_Rx" SG_ 545 DSP_MyKeyVolLim_St 1;
BA_ "U_P702_MY2021_Tx" SG_ 545 DSP_MyKeyVolLim_St 1;
BA_ "U_T6_MCA_MY2020_Tx" SG_ 545 DSP_MyKeyVolLim_St 1;
BA_ "U_CD542_MY2021_Tx" SG_ 545 DSP_MyKeyVolLim_St 1;
BA_ "U_U55X_MY2022_Tx" SG_ 545 DSP_MyKeyVolLim_St 1;
BA_ "U_CD764_MY2022_Tx" SG_ 545 DSP_MyKeyVolLim_St 1;
BA_ "GenSigSendType" SG_ 545 DSP_BeltminderAudio_St 3;
BA_ "U_P702_MY2021_Rx" SG_ 545 DSP_BeltminderAudio_St 1;
BA_ "U_T6_MCA_MY2020_Rx" SG_ 545 DSP_BeltminderAudio_St 1;
BA_ "U_CD542_MY2021_Rx" SG_ 545 DSP_BeltminderAudio_St 1;
BA_ "U_U55X_MY2022_Rx" SG_ 545 DSP_BeltminderAudio_St 1;
BA_ "U_P702_MY2021_Tx" SG_ 545 DSP_BeltminderAudio_St 1;
BA_ "U_T6_MCA_MY2020_Tx" SG_ 545 DSP_BeltminderAudio_St 1;
BA_ "U_CD542_MY2021_Tx" SG_ 545 DSP_BeltminderAudio_St 1;
BA_ "U_U55X_MY2022_Tx" SG_ 545 DSP_BeltminderAudio_St 1;
BA_ "U_CD764_MY2022_Tx" SG_ 545 DSP_BeltminderAudio_St 1;
BA_ "GenSigSendType" SG_ 545 DSP_Audio_Volume_Up_St 3;
BA_ "U_T6_MCA_MY2020_Rx" SG_ 545 DSP_Audio_Volume_Up_St 1;
BA_ "U_U55X_MY2022_Rx" SG_ 545 DSP_Audio_Volume_Up_St 1;
BA_ "U_CD764_MY2022_Rx" SG_ 545 DSP_Audio_Volume_Up_St 1;
BA_ "U_P702_MY2021_Rx" SG_ 545 DSP_Audio_Volume_Up_St 1;
BA_ "U_CD542_MY2021_Rx" SG_ 545 DSP_Audio_Volume_Up_St 1;
BA_ "ECGUsedRxSignal" SG_ 545 DSP_Audio_Volume_Up_St 1;
BA_ "U_P702_MY2021_Tx" SG_ 545 DSP_Audio_Volume_Up_St 1;
BA_ "U_T6_MCA_MY2020_Tx" SG_ 545 DSP_Audio_Volume_Up_St 1;
BA_ "U_CD542_MY2021_Tx" SG_ 545 DSP_Audio_Volume_Up_St 1;
BA_ "U_U55X_MY2022_Tx" SG_ 545 DSP_Audio_Volume_Up_St 1;
BA_ "U_CD764_MY2022_Tx" SG_ 545 DSP_Audio_Volume_Up_St 1;
BA_ "GenSigSendType" SG_ 545 DSP_Audio_Vol_Level_St 3;
BA_ "U_T6_MCA_MY2020_Rx" SG_ 545 DSP_Audio_Vol_Level_St 1;
BA_ "U_U55X_MY2022_Rx" SG_ 545 DSP_Audio_Vol_Level_St 1;
BA_ "U_CD764_MY2022_Rx" SG_ 545 DSP_Audio_Vol_Level_St 1;
BA_ "U_P702_MY2021_Rx" SG_ 545 DSP_Audio_Vol_Level_St 1;
BA_ "U_CD542_MY2021_Rx" SG_ 545 DSP_Audio_Vol_Level_St 1;
BA_ "U_P702_MY2021_Tx" SG_ 545 DSP_Audio_Vol_Level_St 1;
BA_ "U_T6_MCA_MY2020_Tx" SG_ 545 DSP_Audio_Vol_Level_St 1;
BA_ "U_CD542_MY2021_Tx" SG_ 545 DSP_Audio_Vol_Level_St 1;
BA_ "U_U55X_MY2022_Tx" SG_ 545 DSP_Audio_Vol_Level_St 1;
BA_ "U_CD764_MY2022_Tx" SG_ 545 DSP_Audio_Vol_Level_St 1;
BA_ "GenSigSendType" SG_ 545 AutoConfigOcc_Rear 3;
BA_ "U_T6_MCA_MY2020_Rx" SG_ 545 AutoConfigOcc_Rear 1;
BA_ "U_CD542_MY2021_Rx" SG_ 545 AutoConfigOcc_Rear 1;
BA_ "U_U55X_MY2022_Rx" SG_ 545 AutoConfigOcc_Rear 1;
BA_ "U_CD764_MY2022_Rx" SG_ 545 AutoConfigOcc_Rear 1;
BA_ "U_CD542_MY2021_Tx" SG_ 545 AutoConfigOcc_Rear 1;
BA_ "U_CD764_MY2022_Tx" SG_ 545 AutoConfigOcc_Rear 1;
BA_ "GenSigSendType" SG_ 545 AutoConfigOcc_Front 3;
BA_ "U_T6_MCA_MY2020_Rx" SG_ 545 AutoConfigOcc_Front 1;
BA_ "U_CD542_MY2021_Rx" SG_ 545 AutoConfigOcc_Front 1;
BA_ "U_U55X_MY2022_Rx" SG_ 545 AutoConfigOcc_Front 1;
BA_ "U_CD764_MY2022_Rx" SG_ 545 AutoConfigOcc_Front 1;
BA_ "U_CD542_MY2021_Tx" SG_ 545 AutoConfigOcc_Front 1;
BA_ "U_CD764_MY2022_Tx" SG_ 545 AutoConfigOcc_Front 1;
BA_ "GenSigSendType" SG_ 545 AutoConfigOcc_Driver 3;
BA_ "U_T6_MCA_MY2020_Rx" SG_ 545 AutoConfigOcc_Driver 1;
BA_ "U_CD542_MY2021_Rx" SG_ 545 AutoConfigOcc_Driver 1;
BA_ "U_U55X_MY2022_Rx" SG_ 545 AutoConfigOcc_Driver 1;
BA_ "U_CD764_MY2022_Rx" SG_ 545 AutoConfigOcc_Driver 1;
BA_ "U_CD542_MY2021_Tx" SG_ 545 AutoConfigOcc_Driver 1;
BA_ "U_CD764_MY2022_Tx" SG_ 545 AutoConfigOcc_Driver 1;
BA_ "GenSigSendType" SG_ 545 AutoConfigOcc_AllSeats 3;
BA_ "U_T6_MCA_MY2020_Rx" SG_ 545 AutoConfigOcc_AllSeats 1;
BA_ "U_CD542_MY2021_Rx" SG_ 545 AutoConfigOcc_AllSeats 1;
BA_ "U_U55X_MY2022_Rx" SG_ 545 AutoConfigOcc_AllSeats 1;
BA_ "U_CD764_MY2022_Rx" SG_ 545 AutoConfigOcc_AllSeats 1;
BA_ "U_CD542_MY2021_Tx" SG_ 545 AutoConfigOcc_AllSeats 1;
BA_ "U_CD764_MY2022_Tx" SG_ 545 AutoConfigOcc_AllSeats 1;
BA_ "GenSigSendType" SG_ 545 AudioOccMde_D_Stat 3;
BA_ "U_T6_MCA_MY2020_Rx" SG_ 545 AudioOccMde_D_Stat 1;
BA_ "U_CD542_MY2021_Rx" SG_ 545 AudioOccMde_D_Stat 1;
BA_ "U_U55X_MY2022_Rx" SG_ 545 AudioOccMde_D_Stat 1;
BA_ "U_CD764_MY2022_Rx" SG_ 545 AudioOccMde_D_Stat 1;
BA_ "U_T6_MCA_MY2020_Tx" SG_ 545 AudioOccMde_D_Stat 1;
BA_ "U_CD542_MY2021_Tx" SG_ 545 AudioOccMde_D_Stat 1;
BA_ "U_U55X_MY2022_Tx" SG_ 545 AudioOccMde_D_Stat 1;
BA_ "U_CD764_MY2022_Tx" SG_ 545 AudioOccMde_D_Stat 1;
BA_ "U_T6_MCA_MY2020_Rx" SG_ 1058 StopStrtVThres_D_Stat_UB 1;
BA_ "U_CD542_MY2021_Rx" SG_ 1058 StopStrtVThres_D_Stat_UB 1;
BA_ "GenSigStartValueInteger" SG_ 1058 StopStrtVThres_D_Stat 1;
BA_ "GenSigStartValue" SG_ 1058 StopStrtVThres_D_Stat 1;
BA_ "GenSigSendType" SG_ 1058 StopStrtVThres_D_Stat 3;
BA_ "U_T6_MCA_MY2020_Rx" SG_ 1058 StopStrtVThres_D_Stat 1;
BA_ "U_CD542_MY2021_Rx" SG_ 1058 StopStrtVThres_D_Stat 1;
BA_ "GenSigSendType" SG_ 1058 ChrgPortDrOpen_B_Stat 3;
BA_ "U_T6_MCA_MY2020_Rx" SG_ 1058 ChrgPortDrOpen_B_Stat 1;
BA_ "U_CD542_MY2021_Rx" SG_ 1058 ChrgPortDrOpen_B_Stat 1;
BA_ "U_T6_MCA_MY2020_Rx" SG_ 1058 ChrgPortDrOpen_B_Stat_UB 1;
BA_ "U_CD542_MY2021_Rx" SG_ 1058 ChrgPortDrOpen_B_Stat_UB 1;
BA_ "U_T6_MCA_MY2020_Rx" SG_ 633 RearDiffLckMsg2_D_Rq_UB 1;
BA_ "GenSigSendType" SG_ 633 RearDiffLckMsg2_D_Rq 3;
BA_ "U_T6_MCA_MY2020_Rx" SG_ 633 RearDiffLckMsg2_D_Rq 1;
BA_ "U_T6_MCA_MY2020_Rx" SG_ 633 PwStepMsgTxt_D_Rq_UB 1;
BA_ "U_U55X_MY2022_Rx" SG_ 633 PwStepMsgTxt_D_Rq_UB 1;
BA_ "GenSigSendType" SG_ 633 PwStepMsgTxt_D_Rq 3;
BA_ "U_T6_MCA_MY2020_Rx" SG_ 633 PwStepMsgTxt_D_Rq 1;
BA_ "U_U55X_MY2022_Rx" SG_ 633 PwStepMsgTxt_D_Rq 1;
BA_ "GenSigStartValueInteger" SG_ 633 RearDiffLck_D_RqDrv 2;
BA_ "GenSigStartValue" SG_ 633 RearDiffLck_D_RqDrv 2;
BA_ "GenSigSendType" SG_ 633 RearDiffLck_D_RqDrv 3;
BA_ "U_T6_MCA_MY2020_Rx" SG_ 633 RearDiffLck_D_RqDrv 1;
BA_ "GenSigStartValueInteger" SG_ 633 AwdMde_D_RqDrv 5;
BA_ "GenSigStartValue" SG_ 633 AwdMde_D_RqDrv 5;
BA_ "GenSigSendType" SG_ 633 AwdMde_D_RqDrv 3;
BA_ "U_T6_MCA_MY2020_Rx" SG_ 633 AwdMde_D_RqDrv 1;
BA_ "U_T6_MCA_MY2020_Rx" SG_ 633 RearDiffLck_D_RqDrv_UB 1;
BA_ "U_T6_MCA_MY2020_Rx" SG_ 633 TsrRegionTxt_D_Stat_UB 1;
BA_ "U_U55X_MY2022_Rx" SG_ 633 TsrRegionTxt_D_Stat_UB 1;
BA_ "U_CD764_MY2022_Rx" SG_ 633 TsrRegionTxt_D_Stat_UB 1;
BA_ "U_T6_MCA_MY2020_Rx" SG_ 633 AwdMde_D_RqDrv_UB 1;
BA_ "GenSigSendType" SG_ 633 TsrRegionTxt_D_Stat 3;
BA_ "U_T6_MCA_MY2020_Rx" SG_ 633 TsrRegionTxt_D_Stat 1;
BA_ "U_U55X_MY2022_Rx" SG_ 633 TsrRegionTxt_D_Stat 1;
BA_ "U_CD764_MY2022_Rx" SG_ 633 TsrRegionTxt_D_Stat 1;
BA_ "U_P702_MY2021_Rx" SG_ 633 GsmGearMsgTxt_D_Rq_UB 1;
BA_ "U_T6_MCA_MY2020_Rx" SG_ 633 GsmGearMsgTxt_D_Rq_UB 1;
BA_ "U_CD542_MY2021_Rx" SG_ 633 GsmGearMsgTxt_D_Rq_UB 1;
BA_ "U_U55X_MY2022_Rx" SG_ 633 GsmGearMsgTxt_D_Rq_UB 1;
BA_ "GenSigSendType" SG_ 633 GsmGearMsgTxt_D_Rq 3;
BA_ "U_P702_MY2021_Rx" SG_ 633 GsmGearMsgTxt_D_Rq 1;
BA_ "U_T6_MCA_MY2020_Rx" SG_ 633 GsmGearMsgTxt_D_Rq 1;
BA_ "U_CD542_MY2021_Rx" SG_ 633 GsmGearMsgTxt_D_Rq 1;
BA_ "U_U55X_MY2022_Rx" SG_ 633 GsmGearMsgTxt_D_Rq 1;
BA_ "U_T6_MCA_MY2020_Rx" SG_ 633 RearDiffLckLamp_D_Rq2_UB 1;
BA_ "GenSigSendType" SG_ 633 RearDiffLckLamp_D_Rq2 3;
BA_ "U_T6_MCA_MY2020_Rx" SG_ 633 RearDiffLckLamp_D_Rq2 1;
BA_ "U_P702_MY2021_Rx" SG_ 633 DasAlrtInfo_D_Dsply_UB 1;
BA_ "U_T6_MCA_MY2020_Rx" SG_ 633 DasAlrtInfo_D_Dsply_UB 1;
BA_ "U_CD542_MY2021_Rx" SG_ 633 DasAlrtInfo_D_Dsply_UB 1;
BA_ "U_U55X_MY2022_Rx" SG_ 633 DasAlrtInfo_D_Dsply_UB 1;
BA_ "GenSigSendType" SG_ 633 DasAlrtInfo_D_Dsply 3;
BA_ "U_P702_MY2021_Rx" SG_ 633 DasAlrtInfo_D_Dsply 1;
BA_ "U_T6_MCA_MY2020_Rx" SG_ 633 DasAlrtInfo_D_Dsply 1;
BA_ "U_CD542_MY2021_Rx" SG_ 633 DasAlrtInfo_D_Dsply 1;
BA_ "U_U55X_MY2022_Rx" SG_ 633 DasAlrtInfo_D_Dsply 1;
BA_ "U_P702_MY2021_Rx" SG_ 633 Shed_Feature_Group_ID_UB 1;
BA_ "U_T6_MCA_MY2020_Rx" SG_ 633 Shed_Feature_Group_ID_UB 1;
BA_ "U_U55X_MY2022_Rx" SG_ 633 Shed_Feature_Group_ID_UB 1;
BA_ "WakeupSignal" SG_ 633 Shed_Feature_Group_ID 1;
BA_ "GenSigSendType" SG_ 633 Shed_Feature_Group_ID 3;
BA_ "U_P702_MY2021_Rx" SG_ 633 Shed_Feature_Group_ID 1;
BA_ "U_T6_MCA_MY2020_Rx" SG_ 633 Shed_Feature_Group_ID 1;
BA_ "U_U55X_MY2022_Rx" SG_ 633 Shed_Feature_Group_ID 1;
BA_ "U_CD764_MY2022_Rx" SG_ 936 SAPPStatusCoding 1;
BA_ "GenSigSendType" SG_ 936 ApaSys_D_Stat 3;
BA_ "U_P702_MY2021_Rx" SG_ 936 ApaSys_D_Stat 1;
BA_ "U_T6_MCA_MY2020_Rx" SG_ 936 ApaSys_D_Stat 1;
BA_ "U_CD542_MY2021_Rx" SG_ 936 ApaSys_D_Stat 1;
BA_ "U_CD764_MY2022_Rx" SG_ 936 ApaSys_D_Stat 1;
BA_ "GenSigSendType" SG_ 936 ApaSteWhl_D_RqDrv 3;
BA_ "U_P702_MY2021_Rx" SG_ 936 ApaSteWhl_D_RqDrv 1;
BA_ "U_T6_MCA_MY2020_Rx" SG_ 936 ApaSteWhl_D_RqDrv 1;
BA_ "U_CD542_MY2021_Rx" SG_ 936 ApaSteWhl_D_RqDrv 1;
BA_ "U_CD764_MY2022_Rx" SG_ 936 ApaSteWhl_D_RqDrv 1;
BA_ "GenSigSendType" SG_ 936 ApaSteScanMde_D_Stat 3;
BA_ "U_P702_MY2021_Rx" SG_ 936 ApaSteScanMde_D_Stat 1;
BA_ "U_T6_MCA_MY2020_Rx" SG_ 936 ApaSteScanMde_D_Stat 1;
BA_ "U_CD542_MY2021_Rx" SG_ 936 ApaSteScanMde_D_Stat 1;
BA_ "U_CD764_MY2022_Rx" SG_ 936 ApaSteScanMde_D_Stat 1;
BA_ "GenSigSendType" SG_ 936 ApaSelSapp_D_Stat 3;
BA_ "U_P702_MY2021_Rx" SG_ 936 ApaSelSapp_D_Stat 1;
BA_ "U_T6_MCA_MY2020_Rx" SG_ 936 ApaSelSapp_D_Stat 1;
BA_ "U_CD542_MY2021_Rx" SG_ 936 ApaSelSapp_D_Stat 1;
BA_ "U_CD764_MY2022_Rx" SG_ 936 ApaSelSapp_D_Stat 1;
BA_ "GenSigSendType" SG_ 936 ApaSelPpa_D_Stat 3;
BA_ "U_P702_MY2021_Rx" SG_ 936 ApaSelPpa_D_Stat 1;
BA_ "U_T6_MCA_MY2020_Rx" SG_ 936 ApaSelPpa_D_Stat 1;
BA_ "U_CD542_MY2021_Rx" SG_ 936 ApaSelPpa_D_Stat 1;
BA_ "U_CD764_MY2022_Rx" SG_ 936 ApaSelPpa_D_Stat 1;
BA_ "GenSigSendType" SG_ 936 ApaSelPoa_D_Stat 3;
BA_ "U_P702_MY2021_Rx" SG_ 936 ApaSelPoa_D_Stat 1;
BA_ "U_T6_MCA_MY2020_Rx" SG_ 936 ApaSelPoa_D_Stat 1;
BA_ "U_CD542_MY2021_Rx" SG_ 936 ApaSelPoa_D_Stat 1;
BA_ "U_CD764_MY2022_Rx" SG_ 936 ApaSelPoa_D_Stat 1;
BA_ "GenSigSendType" SG_ 936 ApaScan_D_Stat 3;
BA_ "U_P702_MY2021_Rx" SG_ 936 ApaScan_D_Stat 1;
BA_ "U_T6_MCA_MY2020_Rx" SG_ 936 ApaScan_D_Stat 1;
BA_ "U_CD542_MY2021_Rx" SG_ 936 ApaScan_D_Stat 1;
BA_ "U_CD764_MY2022_Rx" SG_ 936 ApaScan_D_Stat 1;
BA_ "GenSigSendType" SG_ 936 ApaLongCtl_D_RqDrv 3;
BA_ "U_P702_MY2021_Rx" SG_ 936 ApaLongCtl_D_RqDrv 1;
BA_ "U_T6_MCA_MY2020_Rx" SG_ 936 ApaLongCtl_D_RqDrv 1;
BA_ "U_CD542_MY2021_Rx" SG_ 936 ApaLongCtl_D_RqDrv 1;
BA_ "U_CD764_MY2022_Rx" SG_ 936 ApaLongCtl_D_RqDrv 1;
BA_ "GenSigSendType" SG_ 936 ApaGearShif_D_RqDrv 3;
BA_ "U_P702_MY2021_Rx" SG_ 936 ApaGearShif_D_RqDrv 1;
BA_ "U_T6_MCA_MY2020_Rx" SG_ 936 ApaGearShif_D_RqDrv 1;
BA_ "U_CD542_MY2021_Rx" SG_ 936 ApaGearShif_D_RqDrv 1;
BA_ "U_CD764_MY2022_Rx" SG_ 936 ApaGearShif_D_RqDrv 1;
BA_ "GenSigSendType" SG_ 936 ApaActvSide2_D_Stat 3;
BA_ "U_P702_MY2021_Rx" SG_ 936 ApaActvSide2_D_Stat 1;
BA_ "U_T6_MCA_MY2020_Rx" SG_ 936 ApaActvSide2_D_Stat 1;
BA_ "U_CD542_MY2021_Rx" SG_ 936 ApaActvSide2_D_Stat 1;
BA_ "U_CD764_MY2022_Rx" SG_ 936 ApaActvSide2_D_Stat 1;
BA_ "GenSigSendType" SG_ 936 ApaAcsy_D_RqDrv 3;
BA_ "U_P702_MY2021_Rx" SG_ 936 ApaAcsy_D_RqDrv 1;
BA_ "U_T6_MCA_MY2020_Rx" SG_ 936 ApaAcsy_D_RqDrv 1;
BA_ "U_CD542_MY2021_Rx" SG_ 936 ApaAcsy_D_RqDrv 1;
BA_ "U_CD764_MY2022_Rx" SG_ 936 ApaAcsy_D_RqDrv 1;
BA_ "GenSigSendType" SG_ 936 ApaChime_D_Rq 3;
BA_ "U_T6_MCA_MY2020_Rx" SG_ 936 ApaChime_D_Rq 1;
BA_ "U_CD542_MY2021_Rx" SG_ 936 ApaChime_D_Rq 1;
BA_ "U_U55X_MY2022_Rx" SG_ 936 ApaChime_D_Rq 1;
BA_ "U_CD764_MY2022_Rx" SG_ 936 ApaChime_D_Rq 1;
BA_ "GenSigSendType" SG_ 936 EPASExtAngleStatReq 3;
BA_ "U_P702_MY2021_Rx" SG_ 936 ApaTrgtDist_D_Stat 1;
BA_ "U_T6_MCA_MY2020_Rx" SG_ 936 ApaTrgtDist_D_Stat 1;
BA_ "U_CD542_MY2021_Rx" SG_ 936 ApaTrgtDist_D_Stat 1;
BA_ "U_U55X_MY2022_Rx" SG_ 936 ApaTrgtDist_D_Stat 1;
BA_ "U_CD764_MY2022_Rx" SG_ 936 ApaTrgtDist_D_Stat 1;
BA_ "U_P702_MY2021_Rx" SG_ 936 ApaMsgTxt_D_Rq 1;
BA_ "U_T6_MCA_MY2020_Rx" SG_ 936 ApaMsgTxt_D_Rq 1;
BA_ "U_CD542_MY2021_Rx" SG_ 936 ApaMsgTxt_D_Rq 1;
BA_ "U_U55X_MY2022_Rx" SG_ 936 ApaMsgTxt_D_Rq 1;
BA_ "U_CD764_MY2022_Rx" SG_ 936 ApaMsgTxt_D_Rq 1;
BA_ "GenSigSendType" SG_ 75 VedsPasKneeBag_D_Ltchd 3;
BA_ "U_P702_MY2021_Rx" SG_ 75 VedsPasKneeBag_D_Ltchd 1;
BA_ "U_T6_MCA_MY2020_Rx" SG_ 75 VedsPasKneeBag_D_Ltchd 1;
BA_ "U_CD542_MY2021_Rx" SG_ 75 VedsPasKneeBag_D_Ltchd 1;
BA_ "U_U55X_MY2022_Rx" SG_ 75 VedsPasKneeBag_D_Ltchd 1;
BA_ "U_CD764_MY2022_Rx" SG_ 75 VedsPasKneeBag_D_Ltchd 1;
BA_ "GenSigSendType" SG_ 75 VedsRw1mBckl_D_Ltchd 3;
BA_ "U_P702_MY2021_Rx" SG_ 75 VedsRw1mBckl_D_Ltchd 1;
BA_ "U_T6_MCA_MY2020_Rx" SG_ 75 VedsRw1mBckl_D_Ltchd 1;
BA_ "U_CD542_MY2021_Rx" SG_ 75 VedsRw1mBckl_D_Ltchd 1;
BA_ "U_U55X_MY2022_Rx" SG_ 75 VedsRw1mBckl_D_Ltchd 1;
BA_ "U_CD764_MY2022_Rx" SG_ 75 VedsRw1mBckl_D_Ltchd 1;
BA_ "GenSigSendType" SG_ 75 VedsRw1mBelt_D_Ltchd 3;
BA_ "U_P702_MY2021_Rx" SG_ 75 VedsRw1mBelt_D_Ltchd 1;
BA_ "U_T6_MCA_MY2020_Rx" SG_ 75 VedsRw1mBelt_D_Ltchd 1;
BA_ "U_CD542_MY2021_Rx" SG_ 75 VedsRw1mBelt_D_Ltchd 1;
BA_ "U_U55X_MY2022_Rx" SG_ 75 VedsRw1mBelt_D_Ltchd 1;
BA_ "U_CD764_MY2022_Rx" SG_ 75 VedsRw1mBelt_D_Ltchd 1;
BA_ "GenSigSendType" SG_ 75 VedsRw2pRib_D_Ltchd 3;
BA_ "U_P702_MY2021_Rx" SG_ 75 VedsRw2pRib_D_Ltchd 1;
BA_ "U_T6_MCA_MY2020_Rx" SG_ 75 VedsRw2pRib_D_Ltchd 1;
BA_ "U_CD542_MY2021_Rx" SG_ 75 VedsRw2pRib_D_Ltchd 1;
BA_ "U_U55X_MY2022_Rx" SG_ 75 VedsRw2pRib_D_Ltchd 1;
BA_ "U_CD764_MY2022_Rx" SG_ 75 VedsRw2pRib_D_Ltchd 1;
BA_ "GenSigSendType" SG_ 75 VedsRw2dRib_D_Ltchd 3;
BA_ "U_P702_MY2021_Rx" SG_ 75 VedsRw2dRib_D_Ltchd 1;
BA_ "U_T6_MCA_MY2020_Rx" SG_ 75 VedsRw2dRib_D_Ltchd 1;
BA_ "U_CD542_MY2021_Rx" SG_ 75 VedsRw2dRib_D_Ltchd 1;
BA_ "U_U55X_MY2022_Rx" SG_ 75 VedsRw2dRib_D_Ltchd 1;
BA_ "U_CD764_MY2022_Rx" SG_ 75 VedsRw2dRib_D_Ltchd 1;
BA_ "GenSigSendType" SG_ 75 VedsRw3pBckl_D_Ltchd 3;
BA_ "U_P702_MY2021_Rx" SG_ 75 VedsRw3pBckl_D_Ltchd 1;
BA_ "U_T6_MCA_MY2020_Rx" SG_ 75 VedsRw3pBckl_D_Ltchd 1;
BA_ "U_CD542_MY2021_Rx" SG_ 75 VedsRw3pBckl_D_Ltchd 1;
BA_ "U_U55X_MY2022_Rx" SG_ 75 VedsRw3pBckl_D_Ltchd 1;
BA_ "U_CD764_MY2022_Rx" SG_ 75 VedsRw3pBckl_D_Ltchd 1;
BA_ "GenSigSendType" SG_ 75 VedsRw3mBckl_D_Ltchd 3;
BA_ "U_P702_MY2021_Rx" SG_ 75 VedsRw3mBckl_D_Ltchd 1;
BA_ "U_T6_MCA_MY2020_Rx" SG_ 75 VedsRw3mBckl_D_Ltchd 1;
BA_ "U_CD542_MY2021_Rx" SG_ 75 VedsRw3mBckl_D_Ltchd 1;
BA_ "U_U55X_MY2022_Rx" SG_ 75 VedsRw3mBckl_D_Ltchd 1;
BA_ "U_CD764_MY2022_Rx" SG_ 75 VedsRw3mBckl_D_Ltchd 1;
BA_ "GenSigSendType" SG_ 75 VedsRw3dBckl_D_Ltchd 3;
BA_ "U_P702_MY2021_Rx" SG_ 75 VedsRw3dBckl_D_Ltchd 1;
BA_ "U_T6_MCA_MY2020_Rx" SG_ 75 VedsRw3dBckl_D_Ltchd 1;
BA_ "U_CD542_MY2021_Rx" SG_ 75 VedsRw3dBckl_D_Ltchd 1;
BA_ "U_U55X_MY2022_Rx" SG_ 75 VedsRw3dBckl_D_Ltchd 1;
BA_ "U_CD764_MY2022_Rx" SG_ 75 VedsRw3dBckl_D_Ltchd 1;
BA_ "GenSigSendType" SG_ 75 VedsRw2pBckl_D_Ltchd 3;
BA_ "U_P702_MY2021_Rx" SG_ 75 VedsRw2pBckl_D_Ltchd 1;
BA_ "U_T6_MCA_MY2020_Rx" SG_ 75 VedsRw2pBckl_D_Ltchd 1;
BA_ "U_CD542_MY2021_Rx" SG_ 75 VedsRw2pBckl_D_Ltchd 1;
BA_ "U_U55X_MY2022_Rx" SG_ 75 VedsRw2pBckl_D_Ltchd 1;
BA_ "U_CD764_MY2022_Rx" SG_ 75 VedsRw2pBckl_D_Ltchd 1;
BA_ "GenSigSendType" SG_ 75 VedsRw2mBckl_D_Ltchd 3;
BA_ "U_P702_MY2021_Rx" SG_ 75 VedsRw2mBckl_D_Ltchd 1;
BA_ "U_T6_MCA_MY2020_Rx" SG_ 75 VedsRw2mBckl_D_Ltchd 1;
BA_ "U_CD542_MY2021_Rx" SG_ 75 VedsRw2mBckl_D_Ltchd 1;
BA_ "U_U55X_MY2022_Rx" SG_ 75 VedsRw2mBckl_D_Ltchd 1;
BA_ "U_CD764_MY2022_Rx" SG_ 75 VedsRw2mBckl_D_Ltchd 1;
BA_ "GenSigSendType" SG_ 75 VedsRw2dBckl_D_Ltchd 3;
BA_ "U_P702_MY2021_Rx" SG_ 75 VedsRw2dBckl_D_Ltchd 1;
BA_ "U_T6_MCA_MY2020_Rx" SG_ 75 VedsRw2dBckl_D_Ltchd 1;
BA_ "U_CD542_MY2021_Rx" SG_ 75 VedsRw2dBckl_D_Ltchd 1;
BA_ "U_U55X_MY2022_Rx" SG_ 75 VedsRw2dBckl_D_Ltchd 1;
BA_ "U_CD764_MY2022_Rx" SG_ 75 VedsRw2dBckl_D_Ltchd 1;
BA_ "GenSigSendType" SG_ 75 VedsRw1PasChld_D_Ltchd 3;
BA_ "U_P702_MY2021_Rx" SG_ 75 VedsRw1PasChld_D_Ltchd 1;
BA_ "U_T6_MCA_MY2020_Rx" SG_ 75 VedsRw1PasChld_D_Ltchd 1;
BA_ "U_CD542_MY2021_Rx" SG_ 75 VedsRw1PasChld_D_Ltchd 1;
BA_ "U_U55X_MY2022_Rx" SG_ 75 VedsRw1PasChld_D_Ltchd 1;
BA_ "U_CD764_MY2022_Rx" SG_ 75 VedsRw1PasChld_D_Ltchd 1;
BA_ "GenSigSendType" SG_ 75 VedsRw1PasBckl_D_Ltchd 3;
BA_ "U_P702_MY2021_Rx" SG_ 75 VedsRw1PasBckl_D_Ltchd 1;
BA_ "U_T6_MCA_MY2020_Rx" SG_ 75 VedsRw1PasBckl_D_Ltchd 1;
BA_ "U_CD542_MY2021_Rx" SG_ 75 VedsRw1PasBckl_D_Ltchd 1;
BA_ "U_U55X_MY2022_Rx" SG_ 75 VedsRw1PasBckl_D_Ltchd 1;
BA_ "U_CD764_MY2022_Rx" SG_ 75 VedsRw1PasBckl_D_Ltchd 1;
BA_ "GenSigSendType" SG_ 75 VedsRw1DrvBckl_D_Ltchd 3;
BA_ "U_P702_MY2021_Rx" SG_ 75 VedsRw1DrvBckl_D_Ltchd 1;
BA_ "U_T6_MCA_MY2020_Rx" SG_ 75 VedsRw1DrvBckl_D_Ltchd 1;
BA_ "U_CD542_MY2021_Rx" SG_ 75 VedsRw1DrvBckl_D_Ltchd 1;
BA_ "U_U55X_MY2022_Rx" SG_ 75 VedsRw1DrvBckl_D_Ltchd 1;
BA_ "U_CD764_MY2022_Rx" SG_ 75 VedsRw1DrvBckl_D_Ltchd 1;
BA_ "GenSigSendType" SG_ 75 VedsRw3pRib_D_Ltchd 3;
BA_ "U_P702_MY2021_Rx" SG_ 75 VedsRw3pRib_D_Ltchd 1;
BA_ "U_T6_MCA_MY2020_Rx" SG_ 75 VedsRw3pRib_D_Ltchd 1;
BA_ "U_CD542_MY2021_Rx" SG_ 75 VedsRw3pRib_D_Ltchd 1;
BA_ "U_U55X_MY2022_Rx" SG_ 75 VedsRw3pRib_D_Ltchd 1;
BA_ "U_CD764_MY2022_Rx" SG_ 75 VedsRw3pRib_D_Ltchd 1;
BA_ "GenSigSendType" SG_ 75 VedsRw3dRib_D_Ltchd 3;
BA_ "U_P702_MY2021_Rx" SG_ 75 VedsRw3dRib_D_Ltchd 1;
BA_ "U_T6_MCA_MY2020_Rx" SG_ 75 VedsRw3dRib_D_Ltchd 1;
BA_ "U_CD542_MY2021_Rx" SG_ 75 VedsRw3dRib_D_Ltchd 1;
BA_ "U_U55X_MY2022_Rx" SG_ 75 VedsRw3dRib_D_Ltchd 1;
BA_ "U_CD764_MY2022_Rx" SG_ 75 VedsRw3dRib_D_Ltchd 1;
BA_ "GenSigSendType" SG_ 74 VedsPasSideBag_D_Ltchd 3;
BA_ "U_T6_MCA_MY2020_Rx" SG_ 74 VedsPasSideBag_D_Ltchd 1;
BA_ "U_U55X_MY2022_Rx" SG_ 74 VedsPasSideBag_D_Ltchd 1;
BA_ "U_CD542_MY2021_Rx" SG_ 74 VedsPasSideBag_D_Ltchd 1;
BA_ "U_CD764_MY2022_Rx" SG_ 74 VedsPasSideBag_D_Ltchd 1;
BA_ "GenSigSendType" SG_ 74 VedsPasCrtnBag_D_Ltchd 3;
BA_ "U_T6_MCA_MY2020_Rx" SG_ 74 VedsPasCrtnBag_D_Ltchd 1;
BA_ "U_U55X_MY2022_Rx" SG_ 74 VedsPasCrtnBag_D_Ltchd 1;
BA_ "U_CD542_MY2021_Rx" SG_ 74 VedsPasCrtnBag_D_Ltchd 1;
BA_ "U_CD764_MY2022_Rx" SG_ 74 VedsPasCrtnBag_D_Ltchd 1;
BA_ "GenSigSendType" SG_ 74 VedsPasBelt_D_Ltchd 3;
BA_ "U_T6_MCA_MY2020_Rx" SG_ 74 VedsPasBelt_D_Ltchd 1;
BA_ "U_U55X_MY2022_Rx" SG_ 74 VedsPasBelt_D_Ltchd 1;
BA_ "U_CD542_MY2021_Rx" SG_ 74 VedsPasBelt_D_Ltchd 1;
BA_ "U_CD764_MY2022_Rx" SG_ 74 VedsPasBelt_D_Ltchd 1;
BA_ "GenSigSendType" SG_ 74 VedsPasBag_D_Ltchd 3;
BA_ "U_T6_MCA_MY2020_Rx" SG_ 74 VedsPasBag_D_Ltchd 1;
BA_ "U_U55X_MY2022_Rx" SG_ 74 VedsPasBag_D_Ltchd 1;
BA_ "U_CD542_MY2021_Rx" SG_ 74 VedsPasBag_D_Ltchd 1;
BA_ "U_CD764_MY2022_Rx" SG_ 74 VedsPasBag_D_Ltchd 1;
BA_ "GenSigSendType" SG_ 74 VedsMultiEvnt_D_Ltchd 3;
BA_ "U_T6_MCA_MY2020_Rx" SG_ 74 VedsMultiEvnt_D_Ltchd 1;
BA_ "U_U55X_MY2022_Rx" SG_ 74 VedsMultiEvnt_D_Ltchd 1;
BA_ "U_CD542_MY2021_Rx" SG_ 74 VedsMultiEvnt_D_Ltchd 1;
BA_ "U_CD764_MY2022_Rx" SG_ 74 VedsMultiEvnt_D_Ltchd 1;
BA_ "U_T6_MCA_MY2020_Rx" SG_ 74 VedsMaxDeltaV_D_Ltchd 1;
BA_ "U_U55X_MY2022_Rx" SG_ 74 VedsMaxDeltaV_D_Ltchd 1;
BA_ "U_CD542_MY2021_Rx" SG_ 74 VedsMaxDeltaV_D_Ltchd 1;
BA_ "U_CD764_MY2022_Rx" SG_ 74 VedsMaxDeltaV_D_Ltchd 1;
BA_ "GenSigSendType" SG_ 74 VedsDrvKneeBag_D_Ltchd 3;
BA_ "U_T6_MCA_MY2020_Rx" SG_ 74 VedsDrvKneeBag_D_Ltchd 1;
BA_ "U_U55X_MY2022_Rx" SG_ 74 VedsDrvKneeBag_D_Ltchd 1;
BA_ "U_CD542_MY2021_Rx" SG_ 74 VedsDrvKneeBag_D_Ltchd 1;
BA_ "U_CD764_MY2022_Rx" SG_ 74 VedsDrvKneeBag_D_Ltchd 1;
BA_ "GenSigSendType" SG_ 74 VedsEvntType_D_Ltchd 3;
BA_ "U_T6_MCA_MY2020_Rx" SG_ 74 VedsEvntType_D_Ltchd 1;
BA_ "U_U55X_MY2022_Rx" SG_ 74 VedsEvntType_D_Ltchd 1;
BA_ "U_CD542_MY2021_Rx" SG_ 74 VedsEvntType_D_Ltchd 1;
BA_ "U_CD764_MY2022_Rx" SG_ 74 VedsEvntType_D_Ltchd 1;
BA_ "GenSigSendType" SG_ 74 VedsEvntRoll_D_Ltchd 3;
BA_ "U_T6_MCA_MY2020_Rx" SG_ 74 VedsEvntRoll_D_Ltchd 1;
BA_ "U_U55X_MY2022_Rx" SG_ 74 VedsEvntRoll_D_Ltchd 1;
BA_ "U_CD542_MY2021_Rx" SG_ 74 VedsEvntRoll_D_Ltchd 1;
BA_ "U_CD764_MY2022_Rx" SG_ 74 VedsEvntRoll_D_Ltchd 1;
BA_ "GenSigSendType" SG_ 74 VedsDrvSideBag_D_Ltchd 3;
BA_ "U_T6_MCA_MY2020_Rx" SG_ 74 VedsDrvSideBag_D_Ltchd 1;
BA_ "U_U55X_MY2022_Rx" SG_ 74 VedsDrvSideBag_D_Ltchd 1;
BA_ "U_CD542_MY2021_Rx" SG_ 74 VedsDrvSideBag_D_Ltchd 1;
BA_ "U_CD764_MY2022_Rx" SG_ 74 VedsDrvSideBag_D_Ltchd 1;
BA_ "GenSigSendType" SG_ 74 VedsDrvCrtnBag_D_Ltchd 3;
BA_ "U_T6_MCA_MY2020_Rx" SG_ 74 VedsDrvCrtnBag_D_Ltchd 1;
BA_ "U_U55X_MY2022_Rx" SG_ 74 VedsDrvCrtnBag_D_Ltchd 1;
BA_ "U_CD542_MY2021_Rx" SG_ 74 VedsDrvCrtnBag_D_Ltchd 1;
BA_ "U_CD764_MY2022_Rx" SG_ 74 VedsDrvCrtnBag_D_Ltchd 1;
BA_ "GenSigSendType" SG_ 74 VedsDrvBelt_D_Ltchd 3;
BA_ "U_CD542_MY2021_Rx" SG_ 74 VedsDrvBelt_D_Ltchd 1;
BA_ "U_CD764_MY2022_Rx" SG_ 74 VedsDrvBelt_D_Ltchd 1;
BA_ "U_T6_MCA_MY2020_Rx" SG_ 74 VedsDrvBelt_D_Ltchd 1;
BA_ "U_U55X_MY2022_Rx" SG_ 74 VedsDrvBelt_D_Ltchd 1;
BA_ "GenSigSendType" SG_ 74 VedsDrvBag_D_Ltchd 3;
BA_ "U_P702_MY2021_Rx" SG_ 74 VedsDrvBag_D_Ltchd 1;
BA_ "U_T6_MCA_MY2020_Rx" SG_ 74 VedsDrvBag_D_Ltchd 1;
BA_ "U_CD542_MY2021_Rx" SG_ 74 VedsDrvBag_D_Ltchd 1;
BA_ "U_U55X_MY2022_Rx" SG_ 74 VedsDrvBag_D_Ltchd 1;
BA_ "U_CD764_MY2022_Rx" SG_ 74 VedsDrvBag_D_Ltchd 1;
BA_ "GenSigStartValueInteger" SG_ 74 eCallNotification 1;
BA_ "GenSigStartValue" SG_ 74 eCallNotification 1;
BA_ "GenSigSendType" SG_ 74 eCallNotification 3;
BA_ "U_CD542_MY2021_Rx" SG_ 74 eCallNotification 1;
BA_ "U_CD764_MY2022_Rx" SG_ 74 eCallNotification 1;
BA_ "U_T6_MCA_MY2020_Rx" SG_ 74 eCallNotification 1;
BA_ "U_U55X_MY2022_Rx" SG_ 74 eCallNotification 1;
BA_ "U_CD542_MY2021_Rx" SG_ 638 EmgcyCallHmi_D_Stat 1;
BA_ "U_P702_MY2021_Rx" SG_ 638 EmgcyCallHmi_D_Stat 1;
BA_ "U_T6_MCA_MY2020_Rx" SG_ 638 EmgcyCallHmi_D_Stat 1;
BA_ "U_U55X_MY2022_Rx" SG_ 638 EmgcyCallHmi_D_Stat 1;
BA_ "U_T6_MCA_MY2020_Rx" SG_ 638 EmgcyCallFalt_B_Dsply 1;
BA_ "U_CD542_MY2021_Rx" SG_ 638 EmgcyCallFalt_B_Dsply 1;
BA_ "U_U55X_MY2022_Rx" SG_ 638 EmgcyCallFalt_B_Dsply 1;
BA_ "U_CD764_MY2022_Rx" SG_ 638 EmgcyCallFalt_B_Dsply 1;
BA_ "U_CD542_MY2021_Rx" SG_ 638 EmgcyCallCancl_T_Actl 1;
BA_ "U_P702_MY2021_Rx" SG_ 638 EmgcyCallCancl_T_Actl 1;
BA_ "U_T6_MCA_MY2020_Rx" SG_ 638 EmgcyCallCancl_T_Actl 1;
BA_ "U_U55X_MY2022_Rx" SG_ 638 EmgcyCallCancl_T_Actl 1;
BA_ "U_CD542_MY2021_Rx" SG_ 638 EmgcyCall_D_Stat 1;
BA_ "U_P702_MY2021_Rx" SG_ 638 EmgcyCall_D_Stat 1;
BA_ "U_T6_MCA_MY2020_Rx" SG_ 638 EmgcyCall_D_Stat 1;
BA_ "U_U55X_MY2022_Rx" SG_ 638 EmgcyCall_D_Stat 1;
BA_ "GenSigSendType" SG_ 555 HudVertSzMnuOn_B_Stat 3;
BA_ "U_T6_MCA_MY2020_Rx" SG_ 555 HudVertSzMnuOn_B_Stat 1;
BA_ "U_CD542_MY2021_Rx" SG_ 555 HudVertSzMnuOn_B_Stat 1;
BA_ "U_U55X_MY2022_Rx" SG_ 555 HudVertSzMnuOn_B_Stat 1;
BA_ "U_CD764_MY2022_Rx" SG_ 555 HudVertSzMnuOn_B_Stat 1;
BA_ "U_T6_MCA_MY2020_Tx" SG_ 555 HudVertSzMnuOn_B_Stat 1;
BA_ "U_U55X_MY2022_Tx" SG_ 555 HudVertSzMnuOn_B_Stat 1;
BA_ "U_CD764_MY2022_Tx" SG_ 555 HudVertSzMnuOn_B_Stat 1;
BA_ "GenSigSendType" SG_ 555 HudVertMnuOn_B_Stat 3;
BA_ "U_T6_MCA_MY2020_Rx" SG_ 555 HudVertMnuOn_B_Stat 1;
BA_ "U_CD542_MY2021_Rx" SG_ 555 HudVertMnuOn_B_Stat 1;
BA_ "U_U55X_MY2022_Rx" SG_ 555 HudVertMnuOn_B_Stat 1;
BA_ "U_CD764_MY2022_Rx" SG_ 555 HudVertMnuOn_B_Stat 1;
BA_ "U_T6_MCA_MY2020_Tx" SG_ 555 HudVertMnuOn_B_Stat 1;
BA_ "U_U55X_MY2022_Tx" SG_ 555 HudVertMnuOn_B_Stat 1;
BA_ "U_CD764_MY2022_Tx" SG_ 555 HudVertMnuOn_B_Stat 1;
BA_ "GenSigSendType" SG_ 555 HudTestMdeActv_B_Stat 3;
BA_ "U_T6_MCA_MY2020_Rx" SG_ 555 HudTestMdeActv_B_Stat 1;
BA_ "U_CD542_MY2021_Rx" SG_ 555 HudTestMdeActv_B_Stat 1;
BA_ "U_U55X_MY2022_Rx" SG_ 555 HudTestMdeActv_B_Stat 1;
BA_ "U_CD764_MY2022_Rx" SG_ 555 HudTestMdeActv_B_Stat 1;
BA_ "U_T6_MCA_MY2020_Tx" SG_ 555 HudTestMdeActv_B_Stat 1;
BA_ "U_U55X_MY2022_Tx" SG_ 555 HudTestMdeActv_B_Stat 1;
BA_ "U_CD764_MY2022_Tx" SG_ 555 HudTestMdeActv_B_Stat 1;
BA_ "GenSigSendType" SG_ 555 HudSwtch_B_Stat 3;
BA_ "U_T6_MCA_MY2020_Rx" SG_ 555 HudSwtch_B_Stat 1;
BA_ "U_U55X_MY2022_Rx" SG_ 555 HudSwtch_B_Stat 1;
BA_ "U_CD764_MY2022_Rx" SG_ 555 HudSwtch_B_Stat 1;
BA_ "U_T6_MCA_MY2020_Tx" SG_ 555 HudSwtch_B_Stat 1;
BA_ "U_U55X_MY2022_Tx" SG_ 555 HudSwtch_B_Stat 1;
BA_ "U_CD764_MY2022_Tx" SG_ 555 HudSwtch_B_Stat 1;
BA_ "GenSigSendType" SG_ 555 HudRotatMnuOn_B_Stat 3;
BA_ "U_T6_MCA_MY2020_Rx" SG_ 555 HudRotatMnuOn_B_Stat 1;
BA_ "U_U55X_MY2022_Rx" SG_ 555 HudRotatMnuOn_B_Stat 1;
BA_ "U_CD764_MY2022_Rx" SG_ 555 HudRotatMnuOn_B_Stat 1;
BA_ "U_T6_MCA_MY2020_Tx" SG_ 555 HudRotatMnuOn_B_Stat 1;
BA_ "U_U55X_MY2022_Tx" SG_ 555 HudRotatMnuOn_B_Stat 1;
BA_ "U_CD764_MY2022_Tx" SG_ 555 HudRotatMnuOn_B_Stat 1;
BA_ "GenSigSendType" SG_ 555 HudMsgTxt_D_Rq 3;
BA_ "U_T6_MCA_MY2020_Rx" SG_ 555 HudMsgTxt_D_Rq 1;
BA_ "U_U55X_MY2022_Rx" SG_ 555 HudMsgTxt_D_Rq 1;
BA_ "U_CD764_MY2022_Rx" SG_ 555 HudMsgTxt_D_Rq 1;
BA_ "U_T6_MCA_MY2020_Tx" SG_ 555 HudMsgTxt_D_Rq 1;
BA_ "U_U55X_MY2022_Tx" SG_ 555 HudMsgTxt_D_Rq 1;
BA_ "U_CD764_MY2022_Tx" SG_ 555 HudMsgTxt_D_Rq 1;
BA_ "GenSigSendType" SG_ 555 HudHzntlMnuOn_B_Stat 3;
BA_ "U_T6_MCA_MY2020_Rx" SG_ 555 HudHzntlMnuOn_B_Stat 1;
BA_ "U_U55X_MY2022_Rx" SG_ 555 HudHzntlMnuOn_B_Stat 1;
BA_ "U_CD764_MY2022_Rx" SG_ 555 HudHzntlMnuOn_B_Stat 1;
BA_ "U_T6_MCA_MY2020_Tx" SG_ 555 HudHzntlMnuOn_B_Stat 1;
BA_ "U_U55X_MY2022_Tx" SG_ 555 HudHzntlMnuOn_B_Stat 1;
BA_ "U_CD764_MY2022_Tx" SG_ 555 HudHzntlMnuOn_B_Stat 1;
BA_ "GenSigSendType" SG_ 555 HudBrightMnuOn_B_Stat 3;
BA_ "U_T6_MCA_MY2020_Rx" SG_ 555 HudBrightMnuOn_B_Stat 1;
BA_ "U_CD542_MY2021_Rx" SG_ 555 HudBrightMnuOn_B_Stat 1;
BA_ "U_U55X_MY2022_Rx" SG_ 555 HudBrightMnuOn_B_Stat 1;
BA_ "U_CD764_MY2022_Rx" SG_ 555 HudBrightMnuOn_B_Stat 1;
BA_ "U_T6_MCA_MY2020_Tx" SG_ 555 HudBrightMnuOn_B_Stat 1;
BA_ "U_U55X_MY2022_Tx" SG_ 555 HudBrightMnuOn_B_Stat 1;
BA_ "U_CD764_MY2022_Tx" SG_ 555 HudBrightMnuOn_B_Stat 1;
BA_ "GenSigSendType" SG_ 555 HudActv_D_Stat 3;
BA_ "U_T6_MCA_MY2020_Rx" SG_ 555 HudActv_D_Stat 1;
BA_ "U_U55X_MY2022_Rx" SG_ 555 HudActv_D_Stat 1;
BA_ "U_CD764_MY2022_Rx" SG_ 555 HudActv_D_Stat 1;
BA_ "U_T6_MCA_MY2020_Tx" SG_ 555 HudActv_D_Stat 1;
BA_ "U_U55X_MY2022_Tx" SG_ 555 HudActv_D_Stat 1;
BA_ "U_CD764_MY2022_Tx" SG_ 555 HudActv_D_Stat 1;
BA_ "GenSigStartValueInteger" SG_ 124 VehTrvlDir_D_Stat 6;
BA_ "GenSigStartValue" SG_ 124 VehTrvlDir_D_Stat 6;
BA_ "U_T6_MCA_MY2020_Rx" SG_ 124 VehOverGnd_V_Est 1;
BA_ "U_P702_MY2021_Rx" SG_ 124 VehOverGnd_V_Est 1;
BA_ "U_CD542_MY2021_Rx" SG_ 124 VehOverGnd_V_Est 1;
BA_ "U_U55X_MY2022_Rx" SG_ 124 VehOverGnd_V_Est 1;
BA_ "GenSigStartValueInteger" SG_ 124 VehLongComp_A_Actl 1022;
BA_ "GenSigStartValue" SG_ 124 VehLongComp_A_Actl 1022;
BA_ "U_T6_MCA_MY2020_Rx" SG_ 124 VehLongComp_A_Actl 1;
BA_ "U_CD542_MY2021_Rx" SG_ 124 VehLongComp_A_Actl 1;
BA_ "U_P702_MY2021_Rx" SG_ 124 VehLongComp_A_Actl 1;
BA_ "U_U55X_MY2022_Rx" SG_ 124 VehLongComp_A_Actl 1;
BA_ "GenSigStartValueInteger" SG_ 124 VehLatComp_A_Actl 1022;
BA_ "GenSigStartValue" SG_ 124 VehLatComp_A_Actl 1022;
BA_ "U_T6_MCA_MY2020_Rx" SG_ 124 VehLatComp_A_Actl 1;
BA_ "U_CD542_MY2021_Rx" SG_ 124 VehLatComp_A_Actl 1;
BA_ "U_P702_MY2021_Rx" SG_ 124 VehLatComp_A_Actl 1;
BA_ "U_U55X_MY2022_Rx" SG_ 124 VehLatComp_A_Actl 1;
BA_ "GenSigStartValueInteger" SG_ 124 VehYawComp_W_Actl 4094;
BA_ "GenSigStartValue" SG_ 124 VehYawComp_W_Actl 4094;
BA_ "U_T6_MCA_MY2020_Rx" SG_ 124 VehYawComp_W_Actl 1;
BA_ "U_P702_MY2021_Rx" SG_ 124 VehYawComp_W_Actl 1;
BA_ "U_CD542_MY2021_Rx" SG_ 124 VehYawComp_W_Actl 1;
BA_ "U_U55X_MY2022_Rx" SG_ 124 VehYawComp_W_Actl 1;
BA_ "GenSigSendType" SG_ 736 TextMessage_Rsp 3;
BA_ "U_T6_MCA_MY2020_Rx" SG_ 736 TextMessage_Rsp 1;
BA_ "U_CD542_MY2021_Rx" SG_ 736 TextMessage_Rsp 1;
BA_ "U_CD764_MY2022_Rx" SG_ 736 TextMessage_Rsp 1;
BA_ "U_U55X_MY2022_Rx" SG_ 736 TextMessage_Rsp 1;
BA_ "U_T6_MCA_MY2020_Tx" SG_ 736 TextMessage_Rsp 1;
BA_ "U_CD542_MY2021_Tx" SG_ 736 TextMessage_Rsp 1;
BA_ "U_U55X_MY2022_Tx" SG_ 736 TextMessage_Rsp 1;
BA_ "GenSigSendType" SG_ 736 VRM_IncCallOption_St 3;
BA_ "U_T6_MCA_MY2020_Tx" SG_ 736 VRM_IncCallOption_St 1;
BA_ "U_CD542_MY2021_Tx" SG_ 736 VRM_IncCallOption_St 1;
BA_ "U_U55X_MY2022_Tx" SG_ 736 VRM_IncCallOption_St 1;
BA_ "U_T6_MCA_MY2020_Tx" SG_ 736 VRM_PhonesSts_Rsp 1;
BA_ "U_CD542_MY2021_Tx" SG_ 736 VRM_PhonesSts_Rsp 1;
BA_ "U_U55X_MY2022_Tx" SG_ 736 VRM_PhonesSts_Rsp 1;
BA_ "U_T6_MCA_MY2020_Rx" SG_ 736 VRM_CallDuration_St 1;
BA_ "U_CD542_MY2021_Rx" SG_ 736 VRM_CallDuration_St 1;
BA_ "U_U55X_MY2022_Rx" SG_ 736 VRM_CallDuration_St 1;
BA_ "U_CD764_MY2022_Rx" SG_ 736 VRM_CallDuration_St 1;
BA_ "U_T6_MCA_MY2020_Tx" SG_ 736 VRM_CallDuration_St 1;
BA_ "U_CD542_MY2021_Tx" SG_ 736 VRM_CallDuration_St 1;
BA_ "U_U55X_MY2022_Tx" SG_ 736 VRM_CallDuration_St 1;
BA_ "U_CD764_MY2022_Tx" SG_ 736 VRM_CallDuration_St 1;
BA_ "GenSigSendType" SG_ 736 BTInCallOptions_St 3;
BA_ "U_T6_MCA_MY2020_Rx" SG_ 736 BTInCallOptions_St 1;
BA_ "U_CD542_MY2021_Rx" SG_ 736 BTInCallOptions_St 1;
BA_ "U_U55X_MY2022_Rx" SG_ 736 BTInCallOptions_St 1;
BA_ "U_CD764_MY2022_Rx" SG_ 736 BTInCallOptions_St 1;
BA_ "U_T6_MCA_MY2020_Tx" SG_ 736 BTInCallOptions_St 1;
BA_ "U_CD542_MY2021_Tx" SG_ 736 BTInCallOptions_St 1;
BA_ "U_U55X_MY2022_Tx" SG_ 736 BTInCallOptions_St 1;
BA_ "U_CD764_MY2022_Tx" SG_ 736 BTInCallOptions_St 1;
BA_ "GenSigSendType" SG_ 722 VRM_ComShuffleTrack_St 3;
BA_ "U_CD542_MY2021_Tx" SG_ 722 VRM_ComShuffleTrack_St 1;
BA_ "U_U55X_MY2022_Tx" SG_ 722 VRM_ComShuffleTrack_St 1;
BA_ "U_T6_MCA_MY2020_Tx" SG_ 722 VRM_ComShuffleTrack_St 1;
BA_ "GenSigSendType" SG_ 722 VRM_ComCompression_St 3;
BA_ "U_CD542_MY2021_Tx" SG_ 722 VRM_ComCompression_St 1;
BA_ "U_U55X_MY2022_Tx" SG_ 722 VRM_ComCompression_St 1;
BA_ "U_T6_MCA_MY2020_Tx" SG_ 722 VRM_ComCompression_St 1;
BA_ "GenSigSendType" SG_ 722 VRM_ComStFreqMode_St 3;
BA_ "U_CD542_MY2021_Tx" SG_ 722 VRM_ComStFreqMode_St 1;
BA_ "U_U55X_MY2022_Tx" SG_ 722 VRM_ComStFreqMode_St 1;
BA_ "U_T6_MCA_MY2020_Tx" SG_ 722 VRM_ComStFreqMode_St 1;
BA_ "GenSigSendType" SG_ 722 VRM_ComAutostore_St 3;
BA_ "U_T6_MCA_MY2020_Tx" SG_ 722 VRM_ComAutostore_St 1;
BA_ "U_CD542_MY2021_Tx" SG_ 722 VRM_ComAutostore_St 1;
BA_ "U_U55X_MY2022_Tx" SG_ 722 VRM_ComAutostore_St 1;
BA_ "GenSigSendType" SG_ 722 VRM_ComBand_St 3;
BA_ "U_T6_MCA_MY2020_Tx" SG_ 722 VRM_ComBand_St 1;
BA_ "U_CD542_MY2021_Tx" SG_ 722 VRM_ComBand_St 1;
BA_ "U_U55X_MY2022_Tx" SG_ 722 VRM_ComBand_St 1;
BA_ "GenSigSendType" SG_ 722 VRM_TMCVoice 3;
BA_ "U_T6_MCA_MY2020_Tx" SG_ 722 VRM_TMCVoice 1;
BA_ "U_CD542_MY2021_Tx" SG_ 722 VRM_TMCVoice 1;
BA_ "U_U55X_MY2022_Tx" SG_ 722 VRM_TMCVoice 1;
BA_ "GenSigSendType" SG_ 722 VRM_NewSMS 3;
BA_ "U_T6_MCA_MY2020_Rx" SG_ 722 VRM_NewSMS 1;
BA_ "U_CD542_MY2021_Rx" SG_ 722 VRM_NewSMS 1;
BA_ "U_U55X_MY2022_Rx" SG_ 722 VRM_NewSMS 1;
BA_ "U_CD764_MY2022_Rx" SG_ 722 VRM_NewSMS 1;
BA_ "U_T6_MCA_MY2020_Tx" SG_ 722 VRM_NewSMS 1;
BA_ "U_CD542_MY2021_Tx" SG_ 722 VRM_NewSMS 1;
BA_ "U_U55X_MY2022_Tx" SG_ 722 VRM_NewSMS 1;
BA_ "GenSigSendType" SG_ 722 VRM_ComRSEDisplay_St 3;
BA_ "U_T6_MCA_MY2020_Tx" SG_ 722 VRM_ComRSEDisplay_St 1;
BA_ "U_CD542_MY2021_Tx" SG_ 722 VRM_ComRSEDisplay_St 1;
BA_ "U_U55X_MY2022_Tx" SG_ 722 VRM_ComRSEDisplay_St 1;
BA_ "U_T6_MCA_MY2020_Tx" SG_ 722 VRM_ComPICode_St 1;
BA_ "U_CD542_MY2021_Tx" SG_ 722 VRM_ComPICode_St 1;
BA_ "U_U55X_MY2022_Tx" SG_ 722 VRM_ComPICode_St 1;
BA_ "GenSigSendType" SG_ 722 VRM_ComPresetCall_St 3;
BA_ "U_T6_MCA_MY2020_Tx" SG_ 722 VRM_ComPresetCall_St 1;
BA_ "U_CD542_MY2021_Tx" SG_ 722 VRM_ComPresetCall_St 1;
BA_ "U_U55X_MY2022_Tx" SG_ 722 VRM_ComPresetCall_St 1;
BA_ "GenSigSendType" SG_ 722 VRM_ComTape_St 3;
BA_ "U_T6_MCA_MY2020_Tx" SG_ 722 VRM_ComTape_St 1;
BA_ "U_CD542_MY2021_Tx" SG_ 722 VRM_ComTape_St 1;
BA_ "U_U55X_MY2022_Tx" SG_ 722 VRM_ComTape_St 1;
BA_ "GenSigSendType" SG_ 722 VRM_ComShuffleDiscs_St 3;
BA_ "U_T6_MCA_MY2020_Tx" SG_ 722 VRM_ComShuffleDiscs_St 1;
BA_ "U_CD542_MY2021_Tx" SG_ 722 VRM_ComShuffleDiscs_St 1;
BA_ "U_U55X_MY2022_Tx" SG_ 722 VRM_ComShuffleDiscs_St 1;
BA_ "GenSigSendType" SG_ 722 VRM_ComDolbyNR_St 3;
BA_ "U_T6_MCA_MY2020_Tx" SG_ 722 VRM_ComDolbyNR_St 1;
BA_ "U_CD542_MY2021_Tx" SG_ 722 VRM_ComDolbyNR_St 1;
BA_ "U_U55X_MY2022_Tx" SG_ 722 VRM_ComDolbyNR_St 1;
BA_ "GenSigSendType" SG_ 722 VRM_ComSourceSelect_St 3;
BA_ "U_T6_MCA_MY2020_Tx" SG_ 722 VRM_ComSourceSelect_St 1;
BA_ "U_CD542_MY2021_Tx" SG_ 722 VRM_ComSourceSelect_St 1;
BA_ "U_U55X_MY2022_Tx" SG_ 722 VRM_ComSourceSelect_St 1;
BA_ "U_T6_MCA_MY2020_Tx" SG_ 722 VRM_ComStFreq_St 1;
BA_ "U_CD542_MY2021_Tx" SG_ 722 VRM_ComStFreq_St 1;
BA_ "U_U55X_MY2022_Tx" SG_ 722 VRM_ComStFreq_St 1;
BA_ "GenSigSendType" SG_ 722 VRM_ComRouteStrategy_St 3;
BA_ "U_T6_MCA_MY2020_Tx" SG_ 722 VRM_ComRouteStrategy_St 1;
BA_ "U_CD542_MY2021_Tx" SG_ 722 VRM_ComRouteStrategy_St 1;
BA_ "U_U55X_MY2022_Tx" SG_ 722 VRM_ComRouteStrategy_St 1;
BA_ "GenSigSendType" SG_ 721 VRM_BTDefaultPhone_St 3;
BA_ "U_T6_MCA_MY2020_Rx" SG_ 721 VRM_BTDefaultPhone_St 1;
BA_ "U_CD542_MY2021_Rx" SG_ 721 VRM_BTDefaultPhone_St 1;
BA_ "U_U55X_MY2022_Rx" SG_ 721 VRM_BTDefaultPhone_St 1;
BA_ "U_CD764_MY2022_Rx" SG_ 721 VRM_BTDefaultPhone_St 1;
BA_ "U_T6_MCA_MY2020_Tx" SG_ 721 VRM_BTDefaultPhone_St 1;
BA_ "U_CD542_MY2021_Tx" SG_ 721 VRM_BTDefaultPhone_St 1;
BA_ "U_U55X_MY2022_Tx" SG_ 721 VRM_BTDefaultPhone_St 1;
BA_ "U_CD764_MY2022_Tx" SG_ 721 VRM_BTDefaultPhone_St 1;
BA_ "GenSigSendType" SG_ 721 VRM_DetourUnit_st 3;
BA_ "U_T6_MCA_MY2020_Tx" SG_ 721 VRM_DetourUnit_st 1;
BA_ "U_CD542_MY2021_Tx" SG_ 721 VRM_DetourUnit_st 1;
BA_ "U_U55X_MY2022_Tx" SG_ 721 VRM_DetourUnit_st 1;
BA_ "GenSigSendType" SG_ 721 VRM_Zoom_Option_St 3;
BA_ "U_T6_MCA_MY2020_Tx" SG_ 721 VRM_Zoom_Option_St 1;
BA_ "U_CD542_MY2021_Tx" SG_ 721 VRM_Zoom_Option_St 1;
BA_ "U_U55X_MY2022_Tx" SG_ 721 VRM_Zoom_Option_St 1;
BA_ "GenSigSendType" SG_ 721 VRM_ComBTDTMFTone_St 3;
BA_ "U_T6_MCA_MY2020_Tx" SG_ 721 VRM_ComBTDTMFTone_St 1;
BA_ "U_CD542_MY2021_Tx" SG_ 721 VRM_ComBTDTMFTone_St 1;
BA_ "U_U55X_MY2022_Tx" SG_ 721 VRM_ComBTDTMFTone_St 1;
BA_ "GenSigSendType" SG_ 721 VRM_SuggestedRoute_St 3;
BA_ "U_T6_MCA_MY2020_Tx" SG_ 721 VRM_SuggestedRoute_St 1;
BA_ "U_CD542_MY2021_Tx" SG_ 721 VRM_SuggestedRoute_St 1;
BA_ "U_U55X_MY2022_Tx" SG_ 721 VRM_SuggestedRoute_St 1;
BA_ "GenSigSendType" SG_ 721 VRM_ComDelWaypoint_St 3;
BA_ "U_T6_MCA_MY2020_Tx" SG_ 721 VRM_ComDelWaypoint_St 1;
BA_ "U_CD542_MY2021_Tx" SG_ 721 VRM_ComDelWaypoint_St 1;
BA_ "U_U55X_MY2022_Tx" SG_ 721 VRM_ComDelWaypoint_St 1;
BA_ "GenSigSendType" SG_ 721 VRM_ComSelectDisc_St 3;
BA_ "U_T6_MCA_MY2020_Tx" SG_ 721 VRM_ComSelectDisc_St 1;
BA_ "U_CD542_MY2021_Tx" SG_ 721 VRM_ComSelectDisc_St 1;
BA_ "U_U55X_MY2022_Tx" SG_ 721 VRM_ComSelectDisc_St 1;
BA_ "GenSigSendType" SG_ 721 VRM_ComTelService_St 3;
BA_ "U_T6_MCA_MY2020_Tx" SG_ 721 VRM_ComTelService_St 1;
BA_ "U_CD542_MY2021_Tx" SG_ 721 VRM_ComTelService_St 1;
BA_ "U_U55X_MY2022_Tx" SG_ 721 VRM_ComTelService_St 1;
BA_ "GenSigSendType" SG_ 721 VRM_ComDestHome_St 3;
BA_ "U_T6_MCA_MY2020_Tx" SG_ 721 VRM_ComDestHome_St 1;
BA_ "U_CD542_MY2021_Tx" SG_ 721 VRM_ComDestHome_St 1;
BA_ "U_U55X_MY2022_Tx" SG_ 721 VRM_ComDestHome_St 1;
BA_ "U_T6_MCA_MY2020_Tx" SG_ 721 VRM_ComSelectTrack_St 1;
BA_ "U_CD542_MY2021_Tx" SG_ 721 VRM_ComSelectTrack_St 1;
BA_ "U_U55X_MY2022_Tx" SG_ 721 VRM_ComSelectTrack_St 1;
BA_ "GenSigSendType" SG_ 721 VRM_ComShowNavInfo_St 3;
BA_ "U_T6_MCA_MY2020_Tx" SG_ 721 VRM_ComShowNavInfo_St 1;
BA_ "U_CD542_MY2021_Tx" SG_ 721 VRM_ComShowNavInfo_St 1;
BA_ "U_U55X_MY2022_Tx" SG_ 721 VRM_ComShowNavInfo_St 1;
BA_ "GenSigSendType" SG_ 721 VRM_VoiceRecStatus_St 3;
BA_ "U_CD764_MY2022_Rx" SG_ 721 VRM_VoiceRecStatus_St 1;
BA_ "U_T6_MCA_MY2020_Tx" SG_ 721 VRM_VoiceRecStatus_St 1;
BA_ "U_CD542_MY2021_Tx" SG_ 721 VRM_VoiceRecStatus_St 1;
BA_ "U_U55X_MY2022_Tx" SG_ 721 VRM_VoiceRecStatus_St 1;
BA_ "GenSigSendType" SG_ 721 VRM_ComSelTrackSource_St 3;
BA_ "U_T6_MCA_MY2020_Tx" SG_ 721 VRM_ComSelTrackSource_St 1;
BA_ "U_CD542_MY2021_Tx" SG_ 721 VRM_ComSelTrackSource_St 1;
BA_ "U_U55X_MY2022_Tx" SG_ 721 VRM_ComSelTrackSource_St 1;
BA_ "GenSigSendType" SG_ 721 VRM_ComDetour_St 3;
BA_ "U_T6_MCA_MY2020_Tx" SG_ 721 VRM_ComDetour_St 1;
BA_ "U_CD542_MY2021_Tx" SG_ 721 VRM_ComDetour_St 1;
BA_ "U_U55X_MY2022_Tx" SG_ 721 VRM_ComDetour_St 1;
BA_ "GenSigSendType" SG_ 721 VRM_ComDisplay_St 3;
BA_ "U_T6_MCA_MY2020_Tx" SG_ 721 VRM_ComDisplay_St 1;
BA_ "U_CD542_MY2021_Tx" SG_ 721 VRM_ComDisplay_St 1;
BA_ "U_U55X_MY2022_Tx" SG_ 721 VRM_ComDisplay_St 1;
BA_ "GenSigSendType" SG_ 721 VRM_ComDynamicGuidande_St 3;
BA_ "U_T6_MCA_MY2020_Tx" SG_ 721 VRM_ComDynamicGuidande_St 1;
BA_ "U_CD542_MY2021_Tx" SG_ 721 VRM_ComDynamicGuidande_St 1;
BA_ "U_U55X_MY2022_Tx" SG_ 721 VRM_ComDynamicGuidande_St 1;
BA_ "GenSigSendType" SG_ 721 VRM_ComZoom_St 3;
BA_ "U_T6_MCA_MY2020_Tx" SG_ 721 VRM_ComZoom_St 1;
BA_ "U_CD542_MY2021_Tx" SG_ 721 VRM_ComZoom_St 1;
BA_ "U_U55X_MY2022_Tx" SG_ 721 VRM_ComZoom_St 1;
BA_ "GenSigSendType" SG_ 721 VRM_ComCallControl_St 3;
BA_ "U_T6_MCA_MY2020_Tx" SG_ 721 VRM_ComCallControl_St 1;
BA_ "U_CD542_MY2021_Tx" SG_ 721 VRM_ComCallControl_St 1;
BA_ "U_U55X_MY2022_Tx" SG_ 721 VRM_ComCallControl_St 1;
BA_ "GenSigSendType" SG_ 721 VRM_ComGuidance_St 3;
BA_ "U_T6_MCA_MY2020_Tx" SG_ 721 VRM_ComGuidance_St 1;
BA_ "U_CD542_MY2021_Tx" SG_ 721 VRM_ComGuidance_St 1;
BA_ "U_U55X_MY2022_Tx" SG_ 721 VRM_ComGuidance_St 1;
BA_ "GenSigSendType" SG_ 721 VRM_ComTrafficInfDsp_St 3;
BA_ "U_T6_MCA_MY2020_Tx" SG_ 721 VRM_ComTrafficInfDsp_St 1;
BA_ "U_CD542_MY2021_Tx" SG_ 721 VRM_ComTrafficInfDsp_St 1;
BA_ "U_U55X_MY2022_Tx" SG_ 721 VRM_ComTrafficInfDsp_St 1;
BA_ "GenSigSendType" SG_ 720 VRM_PhMicrophoneMute_St 3;
BA_ "U_T6_MCA_MY2020_Rx" SG_ 720 VRM_PhMicrophoneMute_St 1;
BA_ "U_CD542_MY2021_Rx" SG_ 720 VRM_PhMicrophoneMute_St 1;
BA_ "U_U55X_MY2022_Rx" SG_ 720 VRM_PhMicrophoneMute_St 1;
BA_ "U_CD764_MY2022_Rx" SG_ 720 VRM_PhMicrophoneMute_St 1;
BA_ "U_T6_MCA_MY2020_Tx" SG_ 720 VRM_PhMicrophoneMute_St 1;
BA_ "U_CD542_MY2021_Tx" SG_ 720 VRM_PhMicrophoneMute_St 1;
BA_ "U_U55X_MY2022_Tx" SG_ 720 VRM_PhMicrophoneMute_St 1;
BA_ "U_CD764_MY2022_Tx" SG_ 720 VRM_PhMicrophoneMute_St 1;
BA_ "GenSigSendType" SG_ 720 Aioc_ExtSrcOutpMode_St 3;
BA_ "U_T6_MCA_MY2020_Tx" SG_ 720 Aioc_ExtSrcOutpMode_St 1;
BA_ "U_CD542_MY2021_Tx" SG_ 720 Aioc_ExtSrcOutpMode_St 1;
BA_ "U_U55X_MY2022_Tx" SG_ 720 Aioc_ExtSrcOutpMode_St 1;
BA_ "GenSigSendType" SG_ 720 VRM_BTPhoneSts_St 3;
BA_ "U_T6_MCA_MY2020_Rx" SG_ 720 VRM_BTPhoneSts_St 1;
BA_ "U_U55X_MY2022_Rx" SG_ 720 VRM_BTPhoneSts_St 1;
BA_ "U_CD764_MY2022_Rx" SG_ 720 VRM_BTPhoneSts_St 1;
BA_ "U_CD542_MY2021_Rx" SG_ 720 VRM_BTPhoneSts_St 1;
BA_ "ECGUsedRxSignal" SG_ 720 VRM_BTPhoneSts_St 1;
BA_ "U_T6_MCA_MY2020_Tx" SG_ 720 VRM_BTPhoneSts_St 1;
BA_ "U_CD542_MY2021_Tx" SG_ 720 VRM_BTPhoneSts_St 1;
BA_ "U_U55X_MY2022_Tx" SG_ 720 VRM_BTPhoneSts_St 1;
BA_ "U_CD764_MY2022_Tx" SG_ 720 VRM_BTPhoneSts_St 1;
BA_ "GenSigSendType" SG_ 720 VRM_SubscribeStatus_St 3;
BA_ "U_T6_MCA_MY2020_Tx" SG_ 720 VRM_SubscribeStatus_St 1;
BA_ "U_CD542_MY2021_Tx" SG_ 720 VRM_SubscribeStatus_St 1;
BA_ "U_U55X_MY2022_Tx" SG_ 720 VRM_SubscribeStatus_St 1;
BA_ "GenSigSendType" SG_ 720 VRM_BlutoothStatus_St 3;
BA_ "U_T6_MCA_MY2020_Rx" SG_ 720 VRM_BlutoothStatus_St 1;
BA_ "U_CD542_MY2021_Rx" SG_ 720 VRM_BlutoothStatus_St 1;
BA_ "U_U55X_MY2022_Rx" SG_ 720 VRM_BlutoothStatus_St 1;
BA_ "U_CD764_MY2022_Rx" SG_ 720 VRM_BlutoothStatus_St 1;
BA_ "U_T6_MCA_MY2020_Tx" SG_ 720 VRM_BlutoothStatus_St 1;
BA_ "U_CD542_MY2021_Tx" SG_ 720 VRM_BlutoothStatus_St 1;
BA_ "U_U55X_MY2022_Tx" SG_ 720 VRM_BlutoothStatus_St 1;
BA_ "U_CD764_MY2022_Tx" SG_ 720 VRM_BlutoothStatus_St 1;
BA_ "GenSigSendType" SG_ 720 VRM_BondRequest_St 3;
BA_ "U_T6_MCA_MY2020_Tx" SG_ 720 VRM_BondRequest_St 1;
BA_ "U_CD542_MY2021_Tx" SG_ 720 VRM_BondRequest_St 1;
BA_ "U_U55X_MY2022_Tx" SG_ 720 VRM_BondRequest_St 1;
BA_ "GenSigSendType" SG_ 720 VRM_VRMMonoOutMode_St 3;
BA_ "U_T6_MCA_MY2020_Tx" SG_ 720 VRM_VRMMonoOutMode_St 1;
BA_ "U_CD542_MY2021_Tx" SG_ 720 VRM_VRMMonoOutMode_St 1;
BA_ "U_U55X_MY2022_Tx" SG_ 720 VRM_VRMMonoOutMode_St 1;
BA_ "GenSigSendType" SG_ 720 VRM_BTNetworkStatus_St 3;
BA_ "U_T6_MCA_MY2020_Rx" SG_ 720 VRM_BTNetworkStatus_St 1;
BA_ "U_CD542_MY2021_Rx" SG_ 720 VRM_BTNetworkStatus_St 1;
BA_ "U_U55X_MY2022_Rx" SG_ 720 VRM_BTNetworkStatus_St 1;
BA_ "U_CD764_MY2022_Rx" SG_ 720 VRM_BTNetworkStatus_St 1;
BA_ "U_T6_MCA_MY2020_Tx" SG_ 720 VRM_BTNetworkStatus_St 1;
BA_ "U_CD542_MY2021_Tx" SG_ 720 VRM_BTNetworkStatus_St 1;
BA_ "U_U55X_MY2022_Tx" SG_ 720 VRM_BTNetworkStatus_St 1;
BA_ "U_CD764_MY2022_Tx" SG_ 720 VRM_BTNetworkStatus_St 1;
BA_ "GenSigSendType" SG_ 720 VRM_BTSignalStrength_St 3;
BA_ "U_T6_MCA_MY2020_Rx" SG_ 720 VRM_BTSignalStrength_St 1;
BA_ "U_CD542_MY2021_Rx" SG_ 720 VRM_BTSignalStrength_St 1;
BA_ "U_CD764_MY2022_Rx" SG_ 720 VRM_BTSignalStrength_St 1;
BA_ "U_T6_MCA_MY2020_Tx" SG_ 720 VRM_BTSignalStrength_St 1;
BA_ "U_CD542_MY2021_Tx" SG_ 720 VRM_BTSignalStrength_St 1;
BA_ "U_U55X_MY2022_Tx" SG_ 720 VRM_BTSignalStrength_St 1;
BA_ "U_CD764_MY2022_Tx" SG_ 720 VRM_BTSignalStrength_St 1;
BA_ "GenSigSendType" SG_ 720 VRM_BTBatteryLevel_St 3;
BA_ "U_T6_MCA_MY2020_Rx" SG_ 720 VRM_BTBatteryLevel_St 1;
BA_ "U_CD542_MY2021_Rx" SG_ 720 VRM_BTBatteryLevel_St 1;
BA_ "U_CD764_MY2022_Rx" SG_ 720 VRM_BTBatteryLevel_St 1;
BA_ "U_T6_MCA_MY2020_Tx" SG_ 720 VRM_BTBatteryLevel_St 1;
BA_ "U_CD542_MY2021_Tx" SG_ 720 VRM_BTBatteryLevel_St 1;
BA_ "U_U55X_MY2022_Tx" SG_ 720 VRM_BTBatteryLevel_St 1;
BA_ "U_CD764_MY2022_Tx" SG_ 720 VRM_BTBatteryLevel_St 1;
BA_ "GenSigSendType" SG_ 470 VRM_BTIncomingCall_Rsp 3;
BA_ "U_T6_MCA_MY2020_Rx" SG_ 470 VRM_BTIncomingCall_Rsp 1;
BA_ "U_CD542_MY2021_Rx" SG_ 470 VRM_BTIncomingCall_Rsp 1;
BA_ "U_U55X_MY2022_Rx" SG_ 470 VRM_BTIncomingCall_Rsp 1;
BA_ "U_CD764_MY2022_Rx" SG_ 470 VRM_BTIncomingCall_Rsp 1;
BA_ "U_T6_MCA_MY2020_Tx" SG_ 470 VRM_BTIncomingCall_Rsp 1;
BA_ "U_CD542_MY2021_Tx" SG_ 470 VRM_BTIncomingCall_Rsp 1;
BA_ "U_U55X_MY2022_Tx" SG_ 470 VRM_BTIncomingCall_Rsp 1;
BA_ "U_CD764_MY2022_Tx" SG_ 470 VRM_BTIncomingCall_Rsp 1;
BA_ "GenSigSendType" SG_ 470 VRM_BTEndTelService_Rsp 3;
BA_ "U_T6_MCA_MY2020_Rx" SG_ 470 VRM_BTEndTelService_Rsp 1;
BA_ "U_CD542_MY2021_Rx" SG_ 470 VRM_BTEndTelService_Rsp 1;
BA_ "U_U55X_MY2022_Rx" SG_ 470 VRM_BTEndTelService_Rsp 1;
BA_ "U_CD764_MY2022_Rx" SG_ 470 VRM_BTEndTelService_Rsp 1;
BA_ "U_T6_MCA_MY2020_Tx" SG_ 470 VRM_BTEndTelService_Rsp 1;
BA_ "U_CD542_MY2021_Tx" SG_ 470 VRM_BTEndTelService_Rsp 1;
BA_ "U_U55X_MY2022_Tx" SG_ 470 VRM_BTEndTelService_Rsp 1;
BA_ "U_CD764_MY2022_Tx" SG_ 470 VRM_BTEndTelService_Rsp 1;
BA_ "GenSigSendType" SG_ 1978 TesterPhysicalResHUD_ADV 3;
BA_ "U_T6_MCA_MY2020_Tx" SG_ 1978 TesterPhysicalResHUD_ADV 1;
BA_ "U_U55X_MY2022_Tx" SG_ 1978 TesterPhysicalResHUD_ADV 1;
BA_ "U_CD764_MY2022_Tx" SG_ 1978 TesterPhysicalResHUD_ADV 1;
BA_ "GenSigSendType" SG_ 1970 TesterPhysicalReqHUD_ADV 3;
BA_ "U_T6_MCA_MY2020_Rx" SG_ 1970 TesterPhysicalReqHUD_ADV 1;
BA_ "U_U55X_MY2022_Rx" SG_ 1970 TesterPhysicalReqHUD_ADV 1;
BA_ "U_CD764_MY2022_Rx" SG_ 1970 TesterPhysicalReqHUD_ADV 1;
VAL_ 629 GearPos_D_Actl_UB 1 "Fresh_data" 0 "Unchanged_data" ;
VAL_ 629 GearPos_D_Actl 15 "Unknown" 14 "Reverse" 13 "Undefined_5" 12 "Undefined_4" 11 "Undefined_3" 10 "Tenth" 9 "Ninth" 8 "Eighth" 7 "Seventh" 6 "Sixth" 5 "Fifth" 4 "Fourth" 3 "Third" 2 "Second" 1 "First" 0 "Neutral" ;
VAL_ 629 BattTrac2_E_Max_UB 1 "Fresh_data" 0 "Unchanged_data" ;
VAL_ 629 BattTrac2_E_Avail_UB 1 "Fresh_data" 0 "Unchanged_data" ;
VAL_ 629 BattTrac2_E_Max 4095 "Faulty" 4094 "NoDataExists" ;
VAL_ 629 BattTrac2_E_Avail 4095 "Faulty" 4094 "NoDataExists" ;
VAL_ 629 BattULoChrgHyb_D_Stat_UB 1 "Fresh_data" 0 "Unchanged_data" ;
VAL_ 629 TrnRng_D_Rq_UB 1 "Fresh_data" 0 "Unchanged_data" ;
VAL_ 629 TrnRng_D_Rq 15 "Fault" 14 "Unknown_Position" 13 "NotUsed_2" 12 "NotUsed_1" 11 "Range6" 10 "Range5" 9 "Range4" 8 "Range3_M3_L3" 7 "Range2_M2_L2" 6 "Range1_M1_L1" 5 "Low" 4 "Sport_DriveSport_Mposition" 3 "Drive" 2 "Neutral" 1 "Reverse" 0 "Park" ;
VAL_ 629 BattULoChrgHyb_D_Stat 7 "NotUsed_4" 6 "NotUsed_3" 5 "NotUsed_2" 4 "NotUsed_1" 3 "VehicleServiceRequired" 2 "EvRangeLossDueToLoadActive" 1 "BatteryServiceRequired" 0 "Null" ;
VAL_ 629 BattTracHazrd_D_Stat_UB 1 "Fresh_data" 0 "Unchanged_data" ;
VAL_ 629 BattTracHazrd_D_Stat 3 "Disabled" 2 "HazardConfirmed" 1 "ExternalMonitoringRequired" 0 "NoHazardDetected" ;
VAL_ 672 BCP_Audible_Beep_Rq 1 "Active" 0 "Inactive" ;
VAL_ 672 Coding_BtnID_D 1 "Pressed" 0 "Not_Pressed" ;
VAL_ 672 Coding_BtnID_C 1 "Pressed" 0 "Not_Pressed" ;
VAL_ 672 Coding_BtnID_B 1 "Pressed" 0 "Not_Pressed" ;
VAL_ 672 Coding_BtnID_A 1 "Pressed" 0 "Not_Pressed" ;
VAL_ 816 Dimming_Lvl_RqMnu 0 "NotPressed" 1 "Night_1" 2 "Night_2" 3 "Night_3" 4 "Night_4" 5 "Night_5" 6 "Night_6" 7 "Night_7" 8 "Night_8" 9 "Night_9" 10 "Night_10" 11 "Night_11" 12 "Night_12" 13 "Day_1" 14 "Day_2" 15 "Day_3" 16 "Day_4" 17 "Day_5" 18 "Day_6" 19 "Down" 20 "Up" 21 "NotUsed_1" 22 "NotUsed_2" 23 "NotUsed_3" 24 "NotUsed_4" 25 "NotUsed_5" 26 "NotUsed_6" 27 "NotUsed_7" 28 "NotUsed_8" 29 "NotUsed_9" 30 "NotUsed_10" 31 "NotUsed_11" ;
VAL_ 816 DcacZone3Pw_D_Rq 0 "Null" 1 "Off" 2 "On" 3 "NotUsed" ;
VAL_ 816 DcacZone2Pw_D_Rq 0 "Null" 1 "Off" 2 "On" 3 "NotUsed" ;
VAL_ 816 DcacPwScnd_D_Rq 0 "Null" 1 "Off" 2 "Low" 3 "High" ;
VAL_ 816 DcacPwResetScnd_B_Rq 0 "Null" 1 "Reset" ;
VAL_ 816 DcacLoFuelLim_L_RqMnu 510 "NoDataExists" 511 "Faulty" ;
VAL_ 816 DcacAllZone_D_Rq 0 "Null" 1 "Off" 2 "On" 3 "NotUsed" ;
VAL_ 816 HybMdeSel_D_Rq 7 "NotUsed_2" 6 "NotUsed_1" 5 "EV_Override_Mode" 4 "EV_Charge_Mode" 3 "EV_Later_Mode" 2 "EV_Now_Mode" 1 "EV_Auto_Mode" 0 "Null" ;
VAL_ 816 KeylessIdl_D_Rq 3 "Cancel" 2 "IgnitionOff" 1 "Active" 0 "Inactive" ;
VAL_ 816 KeyPadCodeDgt7_D_Stat 15 "NotUsed_4" 14 "NotUsed_3" 13 "NotUsed_2" 12 "NotUsed_1" 11 "Button7_8and9_0" 10 "Button0" 9 "Button9_0or9" 8 "Button8" 7 "Button7_8or7" 6 "Button6" 5 "Button5_6or5" 4 "Button4" 3 "Button3_4or3" 2 "Button2" 1 "Button1_2or1" 0 "EndofString" ;
VAL_ 816 KeyPadCodeDgt6_D_Stat 15 "NotUsed_4" 14 "NotUsed_3" 13 "NotUsed_2" 12 "NotUsed_1" 11 "Button7_8and9_0" 10 "Button0" 9 "Button9_0or9" 8 "Button8" 7 "Button7_8or7" 6 "Button6" 5 "Button5_6or5" 4 "Button4" 3 "Button3_4or3" 2 "Button2" 1 "Button1_2or1" 0 "EndofString" ;
VAL_ 816 KeyPadCodeDgt5_D_Stat 15 "NotUsed_4" 14 "NotUsed_3" 13 "NotUsed_2" 12 "NotUsed_1" 11 "Button7_8and9_0" 10 "Button0" 9 "Button9_0or9" 8 "Button8" 7 "Button7_8or7" 6 "Button6" 5 "Button5_6or5" 4 "Button4" 3 "Button3_4or3" 2 "Button2" 1 "Button1_2or1" 0 "EndofString" ;
VAL_ 816 KeyPadCodeDgt4_D_Stat 15 "NotUsed_4" 14 "NotUsed_3" 13 "NotUsed_2" 12 "NotUsed_1" 11 "Button7_8and9_0" 10 "Button0" 9 "Button9_0or9" 8 "Button8" 7 "Button7_8or7" 6 "Button6" 5 "Button5_6or5" 4 "Button4" 3 "Button3_4or3" 2 "Button2" 1 "Button1_2or1" 0 "EndofString" ;
VAL_ 816 KeyPadCodeDgt3_D_Stat 15 "NotUsed_4" 14 "NotUsed_3" 13 "NotUsed_2" 12 "NotUsed_1" 11 "Button7_8and9_0" 10 "Button0" 9 "Button9_0or9" 8 "Button8" 7 "Button7_8or7" 6 "Button6" 5 "Button5_6or5" 4 "Button4" 3 "Button3_4or3" 2 "Button2" 1 "Button1_2or1" 0 "EndofString" ;
VAL_ 816 KeyPadCodeDgt2_D_Stat 15 "NotUsed_4" 14 "NotUsed_3" 13 "NotUsed_2" 12 "NotUsed_1" 11 "Button7_8and9_0" 10 "Button0" 9 "Button9_0or9" 8 "Button8" 7 "Button7_8or7" 6 "Button6" 5 "Button5_6or5" 4 "Button4" 3 "Button3_4or3" 2 "Button2" 1 "Button1_2or1" 0 "EndofString" ;
VAL_ 816 KeyPadCodeDgt1_D_Stat 15 "NotUsed_4" 14 "NotUsed_3" 13 "NotUsed_2" 12 "NotUsed_1" 11 "Button7_8and9_0" 10 "Button0" 9 "Button9_0or9" 8 "Button8" 7 "Button7_8or7" 6 "Button6" 5 "Button5_6or5" 4 "Button4" 3 "Button3_4or3" 2 "Button2" 1 "Button1_2or1" 0 "EndofString" ;
VAL_ 816 CntrStk2_D_RqAssoc 7 "Unused_2" 6 "Cancel" 5 "Set_Keycode" 4 "RKE" 3 "Null" 2 "Key" 1 "Erase_KeyCode" 0 "Check_KeyCode" ;
VAL_ 636 WifiHtsptFqBand_D_Stat 3 "NotUsed_1" 2 "Band_2" 1 "Band_1" 0 "Null" ;
VAL_ 636 WifiHtspt_D_Falt 15 "Error15" 14 "Error14" 13 "Error13" 12 "Error12" 11 "Error11" 10 "Error10" 9 "Error9" 8 "Error8" 7 "Error7" 6 "Error6" 5 "Error5" 4 "Error4" 3 "Error3" 2 "Error2" 1 "Error1" 0 "Null" ;
VAL_ 636 WifiHtsptCnnct_D_Stat 3 "NotUsed" 2 "Connected" 1 "NotConnected" 0 "Null" ;
VAL_ 636 Telematics_D_Falt 7 "NotUsed_5" 6 "NotUsed_4" 5 "NotUsed_3" 4 "NotUsed_2" 3 "NotUsed_1" 2 "RunTimeError" 1 "ChipsetInitializationFailu" 0 "Null" ;
VAL_ 636 WifiEnbl_D_Stat 3 "NotUsed" 2 "Enable" 1 "Disable" 0 "Null" ;
VAL_ 636 WifiHtsptVisbl_D_Stat 3 "Not  used" 2 "On" 1 "Off" 0 "Null" ;
VAL_ 636 WifiHtsptScrty_D_Stat 3 "NotUsed_1" 2 "Wapi" 1 "Wpa2_Wpa" 0 "Null" ;
VAL_ 636 WifiHtsptEnbl_D_Stat 3 "OnDisabled" 2 "On" 1 "Off" 0 "Null" ;
VAL_ 636 WifiDevcListNew_B_Stat 1 "Available" 0 "NotAvailable" ;
VAL_ 636 WifiDataUsage_D_Stat 3 "PercentDataUsed" 2 "DataPlanExpired" 1 "FreeTrialPeriodWaiting" 0 "Null" ;
VAL_ 636 ModemSigStren_D_Stat 7 "NotUsed_1" 6 "NotDetermined" 5 "FiveBars" 4 "FourBars" 3 "ThreeBars" 2 "TwoBars" 1 "OneBar" 0 "ZeroBars" ;
VAL_ 636 ModemTechnology_D2_Stat 7 "Lte" 6 "HspaPlus" 5 "Umts" 4 "Edge" 3 "Gprs" 2 "Gsm" 1 "NoNetwork" 0 "Null" ;
VAL_ 636 WifiHtsptCrdntl_B_Stat 1 "Available" 0 "NotAvailable" ;
VAL_ 636 WifiHtsptFq_D_Avail 7 "NotUsed_3" 6 "NotUsed_2" 5 "NotUsed_1" 4 "AllAvailable" 3 "Band_2_Only" 2 "Band_1_Only" 1 "AllRestricted" 0 "Null" ;
VAL_ 636 WifiDataUsageOn_D_Stat 3 "NotUsed" 2 "On" 1 "Off" 0 "Null" ;
VAL_ 807 ElDistTripCur_No_Dsply 0 "0 second" ;
VAL_ 807 ElDistTripUnit_D_Stat 3 "NotUsed" 2 "Miles" 1 "Kilometers" 0 "Inactive" ;
VAL_ 974 EngExhMdeHrStrt_D_Stat 31 "NotUsed_7" 30 "NotUsed_6" 29 "NotUsed_5" 28 "NotUsed_4" 27 "NotUsed_3" 26 "NotUsed_2" 25 "NotUsed_1" 24 "Hour23_11pm" 23 "Hour22_10pm" 22 "Hour21_9pm" 21 "Hour20_8pm" 20 "Hour19_7pm" 19 "Hour18_6pm" 18 "Hour17_5pm" 17 "Hour16_4pm" 16 "Hour15_3pm" 15 "Hour14_2pm" 14 "Hour13_1pm" 13 "Hour12_12pm" 12 "Hour11_11am" 11 "Hour10_10am" 10 "Hour9_9am" 9 "Hour8_8am" 8 "Hour7_7am" 7 "Hour6_6am" 6 "Hour5_5am" 5 "Hour4_4am" 4 "Hour3_3am" 3 "Hour2_2am" 2 "Hour1_1am" 1 "Hour0_12am" 0 "Null" ;
VAL_ 974 EngExhMdeHrEnd_D_Stat 31 "NotUsed_7" 30 "NotUsed_6" 29 "NotUsed_5" 28 "NotUsed_4" 27 "NotUsed_3" 26 "NotUsed_2" 25 "NotUsed_1" 24 "Hour23_11pm" 23 "Hour22_10pm" 22 "Hour21_9pm" 21 "Hour20_8pm" 20 "Hour19_7pm" 19 "Hour18_6pm" 18 "Hour17_5pm" 17 "Hour16_4pm" 16 "Hour15_3pm" 15 "Hour14_2pm" 14 "Hour13_1pm" 13 "Hour12_12pm" 12 "Hour11_11am" 11 "Hour10_10am" 10 "Hour9_9am" 9 "Hour8_8am" 8 "Hour7_7am" 7 "Hour6_6am" 6 "Hour5_5am" 5 "Hour4_4am" 4 "Hour3_3am" 3 "Hour2_2am" 2 "Hour1_1am" 1 "Hour0_12am" 0 "Null" ;
VAL_ 974 EngExhMdeHrEnbl_D_Stat 3 "NotUsed" 2 "Enabled" 1 "Disabled" 0 "Null" ;
VAL_ 974 DcacOut_Pw_DsplyMx 1023 "Faulty" ;
VAL_ 974 DcacOut1_Pw_Dsply 63 "Faulty" ;
VAL_ 974 DcacOut2_Pw_Dsply 63 "Faulty" ;
VAL_ 974 DcacHw_D_Confg 15 "NotUsed_11" 14 "NotUsed_10" 13 "NotUsed_9" 12 "NotUsed_8" 11 "NotUsed_7" 10 "NotUsed_6" 9 "NotUsed_5" 8 "NotUsed_4" 7 "NotUsed_3" 6 "NotUsed_2" 5 "NotUsed_1" 4 "Power_2300W" 3 "Power_7200W" 2 "Power_2400W" 1 "Power_2000W" 0 "NoDcacHardware" ;
VAL_ 974 DcacFaltMsgTxt_D_Rq 15 "HvacOn" 14 "OvercurrentLP" 13 "EngineRun" 12 "Service" 11 "NotAvailable" 10 "PlugWarn" 9 "PlugWarnDrive" 8 "BreakerC" 7 "BreakerB" 6 "BreakerA" 5 "FuelLow" 4 "AcOnOutput" 3 "Temperature" 2 "Gfci" 1 "Overcurrent" 0 "Ok" ;
VAL_ 974 DcacLoFuelMsgTxt_D_Rq 31 "Minute_31" 30 "Minute_30" 29 "Minute_29" 28 "Minute_28" 27 "Minute_27" 26 "Minute_26" 25 "Minute_25" 24 "Minute_24" 23 "Minute_23" 22 "Minute_22" 21 "Minute_21" 20 "Minute_20" 19 "Minute_19" 18 "Minute_18" 17 "Minute_17" 16 "Minute_16" 15 "Minute_15" 14 "Minute_14" 13 "Minute_13" 12 "Minute_12" 11 "Minute_11" 10 "Minute_10" 9 "Minute_9" 8 "Minute_8" 7 "Minute_7" 6 "Minute_6" 5 "Minute_5" 4 "Minute_4" 3 "Minute_3" 2 "Minute_2" 1 "Minute_1" 0 "Ok" ;
VAL_ 974 DcacEngOnMsgTxt_D_Rq 3 "NotUsed" 2 "DisplayQuestion" 1 "DisplayWarning" 0 "Ok" ;
VAL_ 974 DcacElPw_D_Stat 3 "NotUsed" 2 "High" 1 "Low" 0 "Off" ;
VAL_ 974 PwBedPnlEnbl_B_Rq 1 "Enable" 0 "Disable" ;
VAL_ 974 DcacOn_B_Rq 1 "Enable" 0 "Disable" ;
VAL_ 974 DcacSys_B_Falt 1 "Yes" 0 "No" ;
VAL_ 974 DcacLedCtl_D_Rq 3 "Fast_Flash" 2 "Slow_Flash" 1 "On" 0 "Off" ;
VAL_ 805 InstFeTripUnit_D_Stat 15 "NotUsed_12" 14 "NotUsed_11" 13 "NotUsed_10" 12 "NotUsed_9" 11 "NotUsed_8" 10 "NotUsed_7" 9 "NotUsed_6" 8 "NotUsed_5" 7 "NotUsed_4" 6 "NotUsed_3" 5 "NotUsed_2" 4 "NotUsed_1" 3 "LiterPer100kilometer" 2 "KilometerPerLiter" 1 "MilePerGallon" 0 "Inactive" ;
VAL_ 804 ConsInstActv_B_Dsply 1 "Active" 0 "Inactive" ;
VAL_ 804 ConsInstUnit_D_Stat 3 "NotUsed" 2 "LiterPerHour" 1 "GallonPerHour" 0 "Inactive" ;
VAL_ 803 DistTripUnit_D_Stat 3 "NotUsed" 2 "Miles" 1 "Kilometers" 0 "Inactive" ;
VAL_ 802 AvgFeTripUnit_D_Stat 15 "NotUsed_12" 14 "NotUsed_11" 13 "NotUsed_10" 12 "NotUsed_9" 11 "NotUsed_8" 10 "NotUsed_7" 9 "NotUsed_6" 8 "NotUsed_5" 7 "NotUsed_4" 6 "NotUsed_3" 5 "NotUsed_2" 4 "NotUsed_1" 3 "LiterPer100kilometer" 2 "KilometerPerLiter" 1 "MilePerGallon" 0 "Inactive" ;
VAL_ 802 AvgFeTrip2Actv_B_Dsply 1 "Active" 0 "Inactive" ;
VAL_ 802 AvgFeTrip1Actv_B_Dsply 1 "Active" 0 "Inactive" ;
VAL_ 802 AvgFeActv_B_Dsply 1 "Active" 0 "Inactive" ;
VAL_ 812 TimerTrip2_T_Dsply 0 "0 second" ;
VAL_ 812 TimerTrip1_T_Dsply 0 "0 second" ;
VAL_ 885 VehStrtInhbt_D_Dsply 15 "NotUsed_12" 14 "NotUsed_11" 13 "NotUsed_10" 12 "NotUsed_9" 11 "NotUsed_8" 10 "NotUsed_7" 9 "NotUsed_6" 8 "NotUsed_5" 7 "NotUsed_4" 6 "FleetPhoneNumber" 5 "FleetGeneral" 4 "OtaSuccess" 3 "PostOtaActivatePermFail" 2 "PostOtaActivateWarning" 1 "DuringOtaActivate" 0 "NoMessage" ;
VAL_ 885 OtaActv_D_Stat 15 "NotUsed_10" 14 "NotUsed_9" 13 "NotUsed_8" 12 "NotUsed_7" 11 "NotUsed_6" 10 "NotUsed_5" 9 "NotUsed_4" 8 "NotUsed_3" 7 "NotUsed_2" 6 "NotUsed_1" 5 "NonInterruptible_Pending" 4 "NonInterruptible_Config" 3 "NonInterruptible_ER" 2 "NonInterruptible_AB" 1 "Interruptible_AB" 0 "NoInVehicleOta" ;
VAL_ 290 WifiHtsptFqBand_D_Rq 3 "NotUsed_1" 2 "Band_2" 1 "Band_1" 0 "Null" ;
VAL_ 290 WifiHtsptTrial_D_RqDrv 3 "NotUsed_1" 2 "StopReminders" 1 "RemindMeLater" 0 "Null" ;
VAL_ 290 WifiHtsptEnbl_D_Rq 3 "Not used" 2 "On" 1 "Off" 0 "Null" ;
VAL_ 290 WifiRemoveDevc_D_Rq 3 "NotUsed_1" 2 "FromBlockedList" 1 "FromConnectedList" 0 "Null" ;
VAL_ 290 WifiHtsptVisbl_D_Rq 3 "Not used" 2 "On" 1 "Off" 0 "Null" ;
VAL_ 290 WifiHtsptMacAddr_B_Rq 1 "Request" 0 "No request" ;
VAL_ 290 WifiDevcList_D_Rq 3 "NoEntry" 2 "BlockedList" 1 "ConnectedList" 0 "Null" ;
VAL_ 290 WifiDataUsage_D_Rq 3 "RetriveDataFromBackend" 2 "RefreshData" 1 "CurrentData" 0 "Null" ;
VAL_ 290 WifiCarrierInfo_B_Rq 1 "Request" 0 "No  request" ;
VAL_ 290 WifiHtsptScrty_D_Rq 3 "NotUsed_1" 2 "Wapi" 1 "Wpa2_Wpa" 0 "Null" ;
VAL_ 639 OfbChrgPrflUpdate_B_Rq 1 "Request" 0 "NoRequest" ;
VAL_ 639 OfbChrgClearAll_B_Rq 1 "Request" 0 "NoRequest" ;
VAL_ 639 OfbChrgGoTTouch_D_Rq 3 "NotUsed" 2 "On" 1 "Off" 0 "Null" ;
VAL_ 639 OfbChrgGoTPrcond_D_Rq 3 "High" 2 "Medium" 1 "Low" 0 "Off" ;
VAL_ 639 OfbChrgGoTOn_D_Rq 3 "NotUsed" 2 "On" 1 "Off" 0 "Null" ;
VAL_ 639 OfbChrgGoTMnte_D_Rq 15 "NotUsed_4" 14 "NotUsed_3" 13 "NotUsed_2" 12 "NotUsed_1" 11 "Minute_55" 10 "Minute_50" 9 "Minute_45" 8 "Minute_40" 7 "Minute_35" 6 "Minute_30" 5 "Minute_25" 4 "Minute_20" 3 "Minute_15" 2 "Minute_10" 1 "Minute_5" 0 "Minute_0" ;
VAL_ 639 OfbChrgGoTHr_T_Rq 31 "Faulty" 30 "NoDataExists" ;
VAL_ 639 OfbChrgGoTExtHtr_D_Rq 3 "NotUsed" 2 "On" 1 "Off" 0 "Null" ;
VAL_ 639 OfbChrgGoTDelete_B_Rq 1 "Request" 0 "NoRequest" ;
VAL_ 639 OfbChrgGoTUpdate_B_Rq 1 "Request" 0 "NoRequest" ;
VAL_ 419 MK_SpeedValue_Rq 31 "mph90" 30 "mph85" 29 "mph80" 28 "mph75" 27 "mph70" 26 "mph65" 25 "mph60" 24 "mph55" 23 "mph50" 22 "mph45" 21 "mph40" 20 "Kmh165" 19 "Kmh160" 18 "Kmh155" 17 "Kmh150" 16 "Kmh145" 15 "Kmh140" 14 "Kmh135" 13 "Kmh130" 12 "Kmh125" 11 "Kmh120" 10 "Kmh115" 9 "Kmh110" 8 "Kmh105" 7 "Kmh100" 6 "kmh95" 5 "kmh90" 4 "kmh85" 3 "kmh80" 2 "kmh75" 1 "kmh70" 0 "Off" ;
VAL_ 419 MK_SpeedSetting_Rq 15 "Reserved_last" 3 "Reserved" 2 "SpeedMinder" 1 "SpeedLimit" 0 "Inactive" ;
VAL_ 419 MK_ResetAllUserKeys_Rq 1 "ResetAllKeys" 0 "Inactive" ;
VAL_ 419 MK_MyKeySystemInfo_Rq 1 "GetData" 0 "Inactive" ;
VAL_ 419 MK_ESCRestrictConf_Rq 2 "On" 1 "Off" 0 "Inactive" ;
VAL_ 419 MK_ECalRestrictConf_Rq 2 "On" 1 "Off" 0 "Inactive" ;
VAL_ 419 MK_DNDRestrictConf_Rq 2 "On" 1 "Off" 0 "Inactive" ;
VAL_ 419 MK_CreateMyKey_Rq 1 "Create" 0 "Inactive" ;
VAL_ 419 MK_AudioLimitConfig_Rq 2 "On" 1 "Off" 0 "Inactive" ;
VAL_ 419 MK_ACSRestrictConf_Rq 2 "On" 1 "Off" 0 "Inactive" ;
VAL_ 554 SeatOccRearMsgTxt_B_Rq 1 "Active" 0 "Null" ;
VAL_ 554 DrvHazrdModel_D_St 15 "NotUsed_13" 14 "NotUsed_12" 13 "NotUsed_11" 12 "NotUsed_10" 11 "NotUsed_9" 10 "NotUsed_8" 9 "NotUsed_7" 8 "NotUsed_6" 7 "NotUsed_5" 6 "NotUsed_4" 5 "NotUsed_3" 4 "NotUsed_2" 3 "NotUsed_1" 2 "TpegTec" 1 "DenmEm" 0 "None" ;
VAL_ 554 PtWakeupActv1_B_Rq 1 "Wake_up_Powertrain_via_HW" 0 "Don_t_Wake_Up_Powertrain" ;
VAL_ 554 DrvHazrd_D_St 7 "NotUsed_1" 6 "Suspended" 5 "Available" 4 "NoService" 3 "NoSession" 2 "bAllowOff" 1 "bSAllowOff" 0 "NoStatus" ;
VAL_ 494 HEC_TUPresetArea_Rq 13 "reserved" 12 "GetSAT3PresetData" 11 "GetSAT2PresetData" 15 "reserved_last" 10 "GetSAT1PresetData" 9 "GetDAB2PresetData" 8 "GetDAB1PresetData" 7 "Reserved1" 6 "GetAmPresetData" 5 "GetAmAstPresetData" 4 "GetFmAstPresetData" 3 "GetFm3PresetData" 2 "GetFm2PresetData" 1 "GetFm1PresetData" 0 "Inactive" ;
VAL_ 494 HEC_SetCurrTUBand_Rq 12 "reserved" 11 "SAT3" 10 "SAT2" 15 "reserved_last" 9 "SAT1" 8 "DAB2" 7 "DAB1" 6 "AmAst" 5 "Am" 4 "FmAst" 3 "Fm3" 2 "Fm2" 1 "Fm1" 0 "Inactive" ;
VAL_ 498 HEC_ARReqstrPriority_Rq 0 "EmergencyServ" 1 "TelService" 2 "AutoAnswer" 3 "Ta" 4 "PttMutevoice" 5 "NavUserVoiceCmd" 6 "NavSysVoiceCmd" 7 "Radio" 8 "Disc" 9 "Alarm" 10 "Ptynews" 11 "Aux_ExtSource" 12 "BT_BTNavAndTelMute" 13 "ManualAudioMute" 14 "NotReq" ;
VAL_ 498 HEC_AROperationType_Rq 0 "Inactive" 1 "Requestaudioresource" 2 "Releaseaudioresource" 3 "Releaseallaudioresouces" 4 "Getresourceupdate" 5 "Getallresourceupdates" ;
VAL_ 498 HEC_ARReqstrSystem_Rq 0 "FrontRequester" 1 "RearRequester" ;
VAL_ 498 HEC_ARAudioSource_Rq 15 "iPod" 14 "USB" 13 "BTAudio" 0 "AmfmRadio" 1 "FrontDisc" 2 "SDARS_DAB" 3 "InDashCdChanger" 4 "VoiceRecogniser" 5 "TelematicUnit" 6 "BluetoothPhone" 7 "RearDisc" 8 "APIM" 9 "FrontAuxInput" 10 "Navigation" 11 "RearAux" 12 "NotReq" ;
VAL_ 644 VehOnSrc_D_Stat_UB 1 "Fresh_data" 0 "Unchanged_data" ;
VAL_ 644 VehOnSrc_D_Stat 15 "NotUsed_11" 14 "NotUsed_10" 13 "NotUsed_9" 12 "NotUsed_8" 11 "NotUsed_7" 10 "NotUsed_6" 9 "EsclRssd" 8 "AutonomousVehicle" 7 "SecureIdle" 6 "FleetVehicleInhibit" 5 "StolenVehicleInhibit" 4 "OverTheAir" 3 "RemoteParkAssist" 2 "RemoteStart" 1 "Manual" 0 "Off" ;
VAL_ 643 StrtInGearMsgTxt_D_Rq_UB 1 "Fresh_data" 0 "Unchanged_data" ;
VAL_ 643 StrtInGearMsgTxt_D_Rq 15 "Message15" 14 "Message14" 13 "Message13" 12 "Message12" 11 "Message11" 10 "Message10" 9 "Message9" 8 "Message8" 7 "Message7" 6 "Message6" 5 "Message5" 4 "Message4" 3 "Message3" 2 "Message2" 1 "Message1" 0 "NoMessage" ;
VAL_ 643 StabBarCnnct_D_Stat_UB 1 "Fresh_data" 0 "Unchanged_data" ;
VAL_ 643 StabBarCnnct_D_Stat 15 "Faulty" 14 "NotUsed_7" 13 "NotUsed_6" 12 "NotUsed_5" 11 "NotUsed_4" 10 "NotUsed_3" 9 "NotUsed_2" 8 "NotUsed_1" 7 "SbdFailure2" 6 "SbdFailure1" 5 "Shutdown" 4 "NormalClosing" 3 "NormalOpen" 2 "NormalOpening" 1 "NormalClosed" 0 "Initialize" ;
VAL_ 643 GearPos_D_Trg_UB 1 "Fresh_data" 0 "Unchanged_data" ;
VAL_ 643 GearPos_D_Trg 15 "Unknown" 14 "Reverse" 13 "Undefined_5" 12 "Undefined_4" 11 "Undefined_3" 10 "Tenth" 9 "Ninth" 8 "Eighth" 7 "Seventh" 6 "Sixth" 5 "Fifth" 4 "Fourth" 3 "Third" 2 "Second" 1 "First" 0 "Neutral" ;
VAL_ 643 PwTgateStepMsgTxt_B_Rq 1 "DisplayMessage" 0 "NoMessage" ;
VAL_ 643 PwTgateStepMsgTxt_B_Rq_UB 1 "Fresh_data" 0 "Unchanged_data" ;
VAL_ 643 PwTgateMsgTxt_B_Rq_UB 1 "Fresh_data" 0 "Unchanged_data" ;
VAL_ 643 PwTgateLamp_B_Rq_UB 1 "Fresh_data" 0 "Unchanged_data" ;
VAL_ 643 PwTgateMsgTxt_B_Rq 1 "DisplayMessage" 0 "NoMessage" ;
VAL_ 643 PwTgateLamp_B_Rq 1 "On" 0 "Off" ;
VAL_ 643 PwRnngBoardSwtch_D_Stat_UB 1 "Fresh_data" 0 "Unchanged_data" ;
VAL_ 643 PwRnngBoardT_D_Stat_UB 1 "Fresh_data" 0 "Unchanged_data" ;
VAL_ 643 PwRnngBoardT_D_Stat 3 "NotUsed" 2 "Timer2" 1 "Timer1" 0 "Inactive" ;
VAL_ 643 PwRnngBoardSwtch_D_Stat 3 "NotUsed" 2 "DeployUnlocked" 1 "AlwaysActive" 0 "Inactive" ;
VAL_ 643 OnePdlDrvLamp_B_Rq_UB 1 "Fresh_data" 0 "Unchanged_data" ;
VAL_ 643 OnePdlDrv_D_Dsply_UB 1 "Fresh_data" 0 "Unchanged_data" ;
VAL_ 643 OnePdlDrvLamp_B_Rq 1 "On" 0 "Off" ;
VAL_ 643 OnePdlDrv_D_Dsply 3 "Faulty" 2 "Suspended" 1 "On" 0 "Off" ;
VAL_ 643 SeatSlprPosMsgTxt_B_Rq_UB 1 "Fresh_data" 0 "Unchanged_data" ;
VAL_ 643 SeatSlprPosMsgTxt_B_Rq 1 "On" 0 "Off" ;
VAL_ 643 DrPrsntRearPsngr_D_Stat_UB 1 "Fresh_data" 0 "Unchanged_data" ;
VAL_ 643 DrPrsntPsngr_D_Stat_UB 1 "Fresh_data" 0 "Unchanged_data" ;
VAL_ 643 DrPsngrMsgTxt_B_Rq_UB 1 "Fresh_data" 0 "Unchanged_data" ;
VAL_ 643 DrPsngrMsgTxt_B_Rq 1 "Yes" 0 "No" ;
VAL_ 643 DrPrsntRearPsngr_D_Stat 3 "Faulty" 2 "Present" 1 "NotPresent" 0 "NotDetermined" ;
VAL_ 643 DrPrsntPsngr_D_Stat 3 "Faulty" 2 "Present" 1 "NotPresent" 0 "NotDetermined" ;
VAL_ 643 DrPrsntRearDrv_D_Stat_UB 1 "Fresh_data" 0 "Unchanged_data" ;
VAL_ 643 DrDrvMsgTxt_B_Rq_UB 1 "Fresh_data" 0 "Unchanged_data" ;
VAL_ 643 DrPrsntDrv_D_Stat_UB 1 "Fresh_data" 0 "Unchanged_data" ;
VAL_ 643 DrPrsntDrv_D_Stat 3 "Faulty" 2 "Present" 1 "NotPresent" 0 "NotDetermined" ;
VAL_ 643 DrPrsntRearDrv_D_Stat 3 "Faulty" 2 "Present" 1 "NotPresent" 0 "NotDetermined" ;
VAL_ 643 DrDrvMsgTxt_B_Rq 1 "Yes" 0 "No" ;
VAL_ 643 FstChrgCmplt_T_Est_UB 1 "Fresh_data" 0 "Unchanged_data" ;
VAL_ 643 TrunkFrontOpen_D_Stat_UB 1 "Fresh_data" 0 "Unchanged_data" ;
VAL_ 643 TrunkFrontOpen_D_Stat 3 "NotUsed" 2 "NotRestricted" 1 "Restricted" 0 "Null" ;
VAL_ 841 FohAddHeater_D_Stat 3 "NotUsed" 2 "On" 1 "Off" 0 "NoModeSelected" ;
VAL_ 545 SpkrDgtlRight_D_Stat 3 "Faulty" 2 "Normal" 1 "NotPresent" 0 "Null" ;
VAL_ 545 SpkrDgtlLeft_D_Stat 3 "Faulty" 2 "Normal" 1 "NotPresent" 0 "Null" ;
VAL_ 545 SpkrDgtlCntr_D_Stat 3 "Faulty" 2 "Normal" 1 "NotPresent" 0 "Null" ;
VAL_ 545 SurndSndUpmix2_D_Stat 4 "Audience" 3 "On_Stage" 2 "Surround" 1 "Stereo" 0 "Inactive" ;
VAL_ 545 DSP_Bezel_Diag_St 15 "NotUsed_11" 14 "NotUsed_10" 13 "NotUsed_9" 12 "NotUsed_8" 11 "NotUsed_7" 10 "NotUsed_6" 9 "NotUsed_5" 8 "NotUsed_4" 7 "NotUsed_3" 6 "NotUsed_2" 5 "NotUsed_1" 4 "SpeakerWalkAround" 3 "CalibrationPartNumber" 2 "HardwarePartNumber" 1 "SoftwarePartNumber" 0 "Inactive_NOP" ;
VAL_ 545 SndImmrsnLvl_D_Stat 255 "NotUsed_127" 254 "NotUsed_126" 253 "NotUsed_125" 252 "NotUsed_124" 251 "NotUsed_123" 250 "NotUsed_122" 249 "NotUsed_121" 248 "NotUsed_120" 247 "NotUsed_119" 246 "NotUsed_118" 245 "NotUsed_117" 244 "NotUsed_116" 243 "NotUsed_115" 242 "NotUsed_114" 241 "NotUsed_113" 240 "NotUsed_112" 239 "NotUsed_111" 238 "NotUsed_110" 237 "NotUsed_109" 236 "NotUsed_108" 235 "NotUsed_107" 234 "NotUsed_106" 233 "NotUsed_105" 232 "NotUsed_104" 231 "NotUsed_103" 230 "NotUsed_102" 229 "NotUsed_101" 228 "NotUsed_100" 227 "NotUsed_99" 226 "NotUsed_98" 225 "NotUsed_97" 224 "NotUsed_96" 223 "NotUsed_95" 222 "NotUsed_94" 221 "NotUsed_93" 220 "NotUsed_92" 219 "NotUsed_91" 218 "NotUsed_90" 217 "NotUsed_89" 216 "NotUsed_88" 215 "NotUsed_87" 214 "NotUsed_86" 213 "NotUsed_85" 212 "NotUsed_84" 211 "NotUsed_83" 210 "NotUsed_82" 209 "NotUsed_81" 208 "NotUsed_80" 207 "NotUsed_79" 206 "NotUsed_78" 205 "NotUsed_77" 204 "NotUsed_76" 203 "NotUsed_75" 202 "NotUsed_74" 201 "NotUsed_73" 200 "NotUsed_72" 199 "NotUsed_71" 198 "NotUsed_70" 197 "NotUsed_69" 196 "NotUsed_68" 195 "NotUsed_67" 194 "NotUsed_66" 193 "NotUsed_65" 192 "NotUsed_64" 191 "NotUsed_63" 190 "NotUsed_62" 189 "NotUsed_61" 188 "NotUsed_60" 187 "NotUsed_59" 186 "NotUsed_58" 185 "NotUsed_57" 184 "NotUsed_56" 183 "NotUsed_55" 182 "NotUsed_54" 181 "NotUsed_53" 180 "NotUsed_52" 179 "NotUsed_51" 178 "NotUsed_50" 177 "NotUsed_49" 176 "NotUsed_48" 175 "NotUsed_47" 174 "NotUsed_46" 173 "NotUsed_45" 172 "NotUsed_44" 171 "NotUsed_43" 170 "NotUsed_42" 169 "NotUsed_41" 168 "NotUsed_40" 167 "NotUsed_39" 166 "NotUsed_38" 165 "NotUsed_37" 164 "NotUsed_36" 163 "NotUsed_35" 162 "NotUsed_34" 161 "NotUsed_33" 160 "NotUsed_32" 159 "NotUsed_31" 158 "NotUsed_30" 157 "NotUsed_29" 156 "NotUsed_28" 155 "NotUsed_27" 154 "NotUsed_26" 153 "NotUsed_25" 152 "NotUsed_24" 151 "NotUsed_23" 150 "NotUsed_22" 149 "NotUsed_21" 148 "NotUsed_20" 147 "NotUsed_19" 146 "NotUsed_18" 145 "NotUsed_17" 144 "NotUsed_16" 143 "NotUsed_15" 142 "NotUsed_14" 141 "NotUsed_13" 140 "NotUsed_12" 139 "NotUsed_11" 138 "NotUsed_10" 137 "NotUsed_9" 136 "NotUsed_8" 135 "NotUsed_7" 134 "NotUsed_6" 133 "NotUsed_5" 132 "NotUsed_4" 131 "NotUsed_3" 130 "NotUsed_2" 129 "NotUsed_1" 128 "Level127" 127 "Level126" 126 "Level125" 125 "Level124" 124 "Level123" 123 "Level122" 122 "Level121" 121 "Level120" 120 "Level119" 119 "Level118" 118 "Level117" 117 "Level116" 116 "Level115" 115 "Level114" 114 "Level113" 113 "Level112" 112 "Level111" 111 "Level110" 110 "Level109" 109 "Level108" 108 "Level107" 107 "Level106" 106 "Level105" 105 "Level104" 104 "Level103" 103 "Level102" 102 "Level101" 101 "Level100" 100 "Level99" 99 "Level98" 98 "Level97" 97 "Level96" 96 "Level95" 95 "Level94" 94 "Level93" 93 "Level92" 92 "Level91" 91 "Level90" 90 "Level89" 89 "Level88" 88 "Level87" 87 "Level86" 86 "Level85" 85 "Level84" 84 "Level83" 83 "Level82" 82 "Level81" 81 "Level80" 80 "Level79" 79 "Level78" 78 "Level77" 77 "Level76" 76 "Level75" 75 "Level74" 74 "Level73" 73 "Level72" 72 "Level71" 71 "Level70" 70 "Level69" 69 "Level68" 68 "Level67" 67 "Level66" 66 "Level65" 65 "Level64" 64 "Level63" 63 "Level62" 62 "Level61" 61 "Level60" 60 "Level59" 59 "Level58" 58 "Level57" 57 "Level56" 56 "Level55" 55 "Level54" 54 "Level53" 53 "Level52" 52 "Level51" 51 "Level50" 50 "Level49" 49 "Level48" 48 "Level47" 47 "Level46" 46 "Level45" 45 "Level44" 44 "Level43" 43 "Level42" 42 "Level41" 41 "Level40" 40 "Level39" 39 "Level38" 38 "Level37" 37 "Level36" 36 "Level35" 35 "Level34" 34 "Level33" 33 "Level32" 32 "Level31" 31 "Level30" 30 "Level29" 29 "Level28" 28 "Level27" 27 "Level26" 26 "Level25" 25 "Level24" 24 "Level23" 23 "Level22" 22 "Level21" 21 "Level20" 20 "Level19" 19 "Level18" 18 "Level17" 17 "Level16" 16 "Level15" 15 "Level14" 14 "Level13" 13 "Level12" 12 "Level11" 11 "Level10" 10 "Level9" 9 "Level8" 8 "Level7" 7 "Level6" 6 "Level5" 5 "Level4" 4 "Level3" 3 "Level2" 2 "Level1" 1 "Level0" 0 "Inactive" ;
VAL_ 545 DSP_Sur_Sound_st 2 "Surround" 1 "Stereo" 0 "Inactive" ;
VAL_ 545 DSP_MyKeyVolLimitUp_St 2 "NotUpdated" 1 "Updated" 0 "Invalid" ;
VAL_ 545 DSP_MyKeyVolLim_St 0 "Invalid" 1 "Off" 2 "On" ;
VAL_ 545 DSP_BeltminderAudio_St 0 "Invalid" 1 "Off" 2 "On" ;
VAL_ 545 DSP_Audio_Volume_Up_St 1 "Update" 0 "NoUpdate" ;
VAL_ 545 AutoConfigOcc_Rear 1 "Supported" 0 "Not_Supported" ;
VAL_ 545 AutoConfigOcc_Front 1 "Supported" 0 "Not_Supported" ;
VAL_ 545 AutoConfigOcc_Driver 1 "Supported" 0 "Not_Supported" ;
VAL_ 545 AutoConfigOcc_AllSeats 1 "Supported" 0 "Not_Supported" ;
VAL_ 545 AudioOccMde_D_Stat 15 "Reserved9" 14 "Reserved8" 13 "Reserved7" 12 "Reserved6" 11 "Reserved5" 10 "Reserved4" 9 "Convertible" 8 "RearSeats" 7 "FrontSeats" 6 "Reserved3" 5 "Reserved2" 4 "Reserved1" 3 "Passenger" 2 "Driver" 1 "All" 0 "Invalid" ;
VAL_ 1058 StopStrtVThres_D_Stat_UB 1 "Fresh_data" 0 "Unchanged_data" ;
VAL_ 1058 StopStrtVThres_D_Stat 3 "High" 2 "Medium" 1 "Low" 0 "NoSelection" ;
VAL_ 1058 ChrgPortDrOpen_B_Stat 1 "True" 0 "False" ;
VAL_ 1058 ChrgPortDrOpen_B_Stat_UB 1 "Fresh_data" 0 "Unchanged_data" ;
VAL_ 633 RearDiffLckMsg2_D_Rq_UB 1 "Fresh_data" 0 "Unchanged_data" ;
VAL_ 633 RearDiffLckMsg2_D_Rq 15 "NotUsed_3" 14 "NotUsed_2" 13 "NotUsed_1" 12 "ElsdReduced" 11 "LockingFeatureNotAvailable" 10 "EsldOff" 9 "ElsdRestored" 8 "ElsdOverheated" 7 "Locker_Disabled" 6 "Locker_Enabled" 5 "LockerSpeed5" 4 "LockerSpeed4" 3 "LockerSpeed3" 2 "LockerSpeed2" 1 "LockerSpeed1" 0 "NormalNoMessage " ;
VAL_ 633 PwStepMsgTxt_D_Rq_UB 1 "Fresh_data" 0 "Unchanged_data" ;
VAL_ 633 PwStepMsgTxt_D_Rq 1 "DriveInhibited" 0 "NoMessage" 3 "NotUsed" 2 "Malfunction" ;
VAL_ 633 RearDiffLck_D_RqDrv 3 "Faulty" 2 "NoRequest" 1 "On" 0 "Off" ;
VAL_ 633 AwdMde_D_RqDrv 7 "Faulty" 6 "NotUsed2" 5 "NoRequest" 4 "Neutral" 3 "FourByFourLow" 2 "FourByFourHigh" 1 "FourByFourAuto" 0 "FourByTwo" ;
VAL_ 633 RearDiffLck_D_RqDrv_UB 1 "Fresh_data" 0 "Unchanged_data" ;
VAL_ 633 TsrRegionTxt_D_Stat_UB 1 "Fresh_data" 0 "Unchanged_data" ;
VAL_ 633 AwdMde_D_RqDrv_UB 1 "Fresh_data" 0 "Unchanged_data" ;
VAL_ 633 TsrRegionTxt_D_Stat 31 "Faulty" 30 "NotUsed_8" 29 "NotUsed_7" 28 "NotUsed_6" 27 "NotUsed_5" 26 "NotUsed_4" 25 "NotUsed_3" 24 "NotUsed_2" 23 "NotUsed_1" 22 "Region_22" 21 "Region_21" 20 "Region_20" 19 "Region_19" 18 "Region_18" 17 "Region_17" 16 "Region_16" 15 "Region_15" 14 "Region_14" 13 "Region_13" 12 "Region_12" 11 "Region_11" 10 "Region_10" 9 "Region_09" 8 "Region_08" 7 "Region_07" 6 "Region_06" 5 "Region_05" 4 "Region_04" 3 "Region_03" 2 "Region_02" 1 "Region_01" 0 "NotDetermined" ;
VAL_ 633 GsmGearMsgTxt_D_Rq_UB 1 "Fresh_data" 0 "Unchanged_data" ;
VAL_ 633 GsmGearMsgTxt_D_Rq 3 "Message3" 2 "Message2" 1 "Message1" 0 "NoMessage" ;
VAL_ 633 RearDiffLckLamp_D_Rq2_UB 1 "Fresh_data" 0 "Unchanged_data" ;
VAL_ 633 RearDiffLckLamp_D_Rq2 3 "Triggered" 2 "Flash" 1 "On" 0 "Off" ;
VAL_ 633 DasAlrtInfo_D_Dsply_UB 1 "Fresh_data" 0 "Unchanged_data" ;
VAL_ 633 DasAlrtInfo_D_Dsply 3 "NotUsed" 2 "On" 1 "Off" 0 "Null" ;
VAL_ 633 Shed_Feature_Group_ID_UB 1 "Fresh_data" 0 "Unchanged_data" ;
VAL_ 633 Shed_Feature_Group_ID 16 "PtcHeater" 30 "NotUsed_7" 29 "NotUsed_6" 28 "NotUsed_5" 27 "NotUsed_4" 26 "NotUsed_3" 25 "NotUsed_2" 24 "NotUsed_1" 23 "Dcac" 22 "UpFitter_6" 21 "UpFitter_5" 20 "UpFitter_4" 19 "UpFitter_3" 18 "UpFitter_2" 17 "UpFitter_1" 14 "HtdMirr" 13 "HvacRearBlwr_Third" 12 "HvacRearBlwr_Second" 11 "HvacRearBlwr_First" 31 "All LSHED1 Features" 10 "Htd_Windscrn" 9 "SpltHtdBcklight_HtdMirr" 8 "HtdBcklight_HtdMirr" 7 "HtdCoolSeat_FrtDriver" 6 "HtdCoolSeat_FrtPass" 5 "HtdCoolSeat_RearPass" 4 "HtdCoolSeat_RearDriver" 3 "SmartTrlrTowBattCharge" 2 "Htd_StrWhl" 1 "Htd_Washer_Fluid" 0 "No_LSHED1_Features" 15 "Engine_Coolant_Fan" ;
VAL_ 936 ApaButtnPrssd_B_Stat 1 "Pressed" 0 "Not_Pressed" ;
VAL_ 936 ApaSys_D_Stat 7 "Faulty" 6 "Finished" 5 "NotAccessible" 4 "ApaCancelled" 3 "Overspeed" 2 "On" 1 "Off" 0 "Null" ;
VAL_ 936 ApaSteWhl_D_RqDrv 3 "TakeControl" 2 "RemoveHands" 1 "NoRequest" 0 "Null" ;
VAL_ 936 ApaSteScanMde_D_Stat 3 "Steering" 2 "Scanning" 1 "NotScanning" 0 "Null" ;
VAL_ 936 ApaSelSapp_D_Stat 3 "NotConfigured" 2 "NotSelectable" 1 "Selectable" 0 "Null" ;
VAL_ 936 ApaSelPpa_D_Stat 3 "NotConfigured" 2 "NotSelectable" 1 "Selectable" 0 "Null" ;
VAL_ 936 ApaSelPoa_D_Stat 3 "NotConfigured" 2 "NotSelectable" 1 "Selectable" 0 "Null" ;
VAL_ 936 ApaScan_D_Stat 3 "ParkSlotReady" 2 "ParkSlotFound" 1 "NoParkSlot" 0 "Null" ;
VAL_ 936 ApaLongCtl_D_RqDrv 7 "NotUsed3" 6 "NotUsed2" 5 "ReleaseBrake" 4 "DriveBackward" 3 "DriveForward" 2 "Stop" 1 "NoRequest" 0 "Null" ;
VAL_ 936 ApaGearShif_D_RqDrv 7 "NotUSed2" 6 "NotUsed1" 5 "ShiftToP" 4 "ShiftToN" 3 "ShiftToD" 2 "ShiftToR" 1 "NoRequest" 0 "Null" ;
VAL_ 936 ApaActvSide2_D_Stat 3 "NoSide" 2 "Right" 1 "Left" 0 "Null" ;
VAL_ 936 ApaAcsy_D_RqDrv 7 "CloseDoor" 6 "SelectSideRight" 5 "SelectSideLeft" 4 "CheckForObject" 3 "PressApaButton" 2 "SelectSide" 1 "NoRequest" 0 "Null" ;
VAL_ 936 ApaChime_D_Rq 7 "NotUsed2" 6 "NotUsed1" 5 "Warning_Chime" 4 "Finish_Chime" 3 "Stop_Now_Chime" 2 "Spot_Ready_Chime" 1 "Spot_Found_Chime" 0 "No_Chime" ;
VAL_ 936 EPASExtAngleStatReq 1 "Request" 0 "NoRequest" ;
VAL_ 936 ExtSteeringAngleReq2 32767 "Invalid" 32766 "Unknown" ;
VAL_ 936 ApaTrgtDist_D_Stat 15 "Step15" 14 "Step14" 13 "Step13" 12 "Step12" 11 "Step11" 10 "Step10" 9 "Step9" 8 "Step8" 7 "Step7" 6 "Step6" 5 "Step5" 4 "Step4" 3 "Step3" 2 "Step2" 1 "Step1" 0 "Off" ;
VAL_ 936 ApaMsgTxt_D_Rq 15 "NotUsed_6" 14 "NotUsed_5" 13 "NotUsed_4" 12 "NotUsed_3" 11 "ReleaseEpb" 10 "TrailerFeatureNotAvailable" 9 "AccelPedalInactive" 8 "WrongDirection" 7 "SteeringInteraction" 6 "BrakingActive" 5 "HighInclination" 4 "SpeedLimitExceeded" 3 "TcsDisabled" 2 "WheelSlip" 1 "None" 0 "Null" ;
VAL_ 75 VedsPasKneeBag_D_Ltchd 7 "Fault" 6 "NotSupported" 5 "Unused_3" 4 "Unused_2" 3 "Unused_1" 2 "NotDeployed" 1 "Deployed" 0 "NoEvent" ;
VAL_ 75 VedsRw1mBckl_D_Ltchd 5 "Unused_3" 4 "Unused_2" 3 "Unused_1" 2 "NotBelted" 1 "Belted" 0 "NoEvent" 7 "Fault" 6 "NotSupported" ;
VAL_ 75 VedsRw1mBelt_D_Ltchd 7 "Fault" 6 "NotSupported" 5 "Unused_3" 4 "Unused_2" 3 "Unused_1" 2 "NotDeployed" 1 "Deployed" 0 "NoEvent" ;
VAL_ 75 VedsRw2pRib_D_Ltchd 7 "Fault" 6 "NotSupported" 5 "Unused_3" 4 "Unused_2" 3 "Unused_1" 2 "NotDeployed" 1 "Deployed" 0 "NoEvent" ;
VAL_ 75 VedsRw2dRib_D_Ltchd 7 "Fault" 6 "NotSupported" 5 "Unused_3" 4 "Unused_2" 3 "Unused_1" 2 "NotDeployed" 1 "Deployed" 0 "NoEvent" ;
VAL_ 75 VedsRw3pBckl_D_Ltchd 5 "Unused_3" 4 "Unused_2" 3 "Unused_1" 2 "NotBelted" 1 "Belted" 0 "NoEvent" 7 "Fault" 6 "NotSupported" ;
VAL_ 75 VedsRw3mBckl_D_Ltchd 5 "Unused_3" 4 "Unused_2" 3 "Unused_1" 2 "NotBelted" 1 "Belted" 0 "NoEvent" 7 "Fault" 6 "NotSupported" ;
VAL_ 75 VedsRw3dBckl_D_Ltchd 5 "Unused_3" 4 "Unused_2" 3 "Unused_1" 2 "NotBelted" 1 "Belted" 0 "NoEvent" 7 "Fault" 6 "NotSupported" ;
VAL_ 75 VedsRw2pBckl_D_Ltchd 5 "Unused_3" 4 "Unused_2" 3 "Unused_1" 2 "NotBelted" 1 "Belted" 0 "NoEvent" 7 "Fault" 6 "NotSupported" ;
VAL_ 75 VedsRw2mBckl_D_Ltchd 5 "Unused_3" 4 "Unused_2" 3 "Unused_1" 2 "NotBelted" 1 "Belted" 0 "NoEvent" 7 "Fault" 6 "NotSupported" ;
VAL_ 75 VedsRw2dBckl_D_Ltchd 5 "Unused_3" 4 "Unused_2" 3 "Unused_1" 2 "NotBelted" 1 "Belted" 0 "NoEvent" 7 "Fault" 6 "NotSupported" ;
VAL_ 75 VedsRw1PasChld_D_Ltchd 7 "Fault" 6 "NotSupported" 5 "Unused_3" 4 "Unused_2" 3 "Unused_1" 2 "ChildNotDetected" 1 "ChildDetected" 0 "NoEvent" ;
VAL_ 75 VedsRw1PasBckl_D_Ltchd 5 "Unused_3" 4 "Unused_2" 3 "Unused_1" 2 "NotBelted" 1 "Belted" 0 "NoEvent" 7 "Fault" 6 "NotSupported" ;
VAL_ 75 VedsRw1DrvBckl_D_Ltchd 5 "Unused_3" 4 "Unused_2" 3 "Unused_1" 2 "NotBelted" 1 "Belted" 0 "NoEvent" 7 "Fault" 6 "NotSupported" ;
VAL_ 75 VedsRw3pRib_D_Ltchd 7 "Fault" 6 "NotSupported" 5 "Unused_3" 4 "Unused_2" 3 "Unused_1" 2 "NotDeployed" 1 "Deployed" 0 "NoEvent" ;
VAL_ 75 VedsRw3dRib_D_Ltchd 7 "Fault" 6 "NotSupported" 5 "Unused_3" 4 "Unused_2" 3 "Unused_1" 2 "NotDeployed" 1 "Deployed" 0 "NoEvent" ;
VAL_ 74 VedsPasSideBag_D_Ltchd 7 "Fault" 6 "NotSupported" 5 "Unused_3" 4 "Unused_2" 3 "Unused_1" 2 "NotDeployed" 1 "Deployed" 0 "NoEvent" ;
VAL_ 74 VedsPasCrtnBag_D_Ltchd 7 "Fault" 6 "NotSupported" 5 "Unused_3" 4 "Unused_2" 3 "Unused_1" 2 "NotDeployed" 1 "Deployed" 0 "NoEvent" ;
VAL_ 74 VedsPasBelt_D_Ltchd 7 "Fault" 6 "NotSupported" 5 "Unused_3" 4 "Unused_2" 3 "Unused_1" 2 "NotDeployed" 1 "Deployed" 0 "NoEvent" ;
VAL_ 74 VedsPasBag_D_Ltchd 7 "Fault" 6 "NotSupported" 5 "Unused_3" 4 "Unused_2" 3 "Unused_1" 2 "NotDeployed" 1 "Deployed" 0 "NoEvent" ;
VAL_ 74 VedsMultiEvnt_D_Ltchd 7 "Fault" 6 "NotSupported" 5 "Unused_3" 4 "Unused_2" 3 "Unused_1" 2 "Yes" 1 "No" 0 "NoEvent" ;
VAL_ 74 VedsMaxDeltaV_D_Ltchd 0 "NoEvent" 255 "Fault" 254 "NotSupported" ;
VAL_ 74 VedsDrvKneeBag_D_Ltchd 7 "Fault" 6 "NotSupported" 5 "Unused_3" 4 "Unused_2" 3 "Unused_1" 2 "NotDeployed" 1 "Deployed" 0 "NoEvent" ;
VAL_ 74 VedsEvntType_D_Ltchd 7 "Fault" 6 "NotSupported" 5 "Unused" 4 "Rolllover" 3 "Rear" 2 "Side" 1 "Frontal" 0 "NoEvent" ;
VAL_ 74 VedsEvntRoll_D_Ltchd 7 "Fault" 6 "NotSupported" 5 "Unused_3" 4 "Unused_2" 3 "Unused_1" 2 "Yes" 1 "No" 0 "NoEvent" ;
VAL_ 74 VedsDrvSideBag_D_Ltchd 7 "Fault" 6 "NotSupported" 5 "Unused_3" 4 "Unused_2" 3 "Unused_1" 2 "NotDeployed" 1 "Deployed" 0 "NoEvent" ;
VAL_ 74 VedsDrvCrtnBag_D_Ltchd 7 "Fault" 6 "NotSupported" 5 "Unused_3" 4 "Unused_2" 3 "Unused_1" 2 "NotDeployed" 1 "Deployed" 0 "NoEvent" ;
VAL_ 74 VedsDrvBelt_D_Ltchd 7 "Fault" 6 "NotSupported" 5 "Unused_3" 4 "Unused_2" 3 "Unused_1" 2 "NotDeployed" 1 "Deployed" 0 "NoEvent" ;
VAL_ 74 VedsDrvBag_D_Ltchd 7 "Fault" 6 "NotSupported" 5 "Unused_3" 4 "Unused_2" 3 "Unused_1" 2 "NotDeployed" 1 "Deployed" 0 "NoEvent" ;
VAL_ 74 eCallNotification 3 "Not_Used" 2 "Active" 1 "Normal" 0 "Not_Supported" ;
VAL_ 638 EmgcyCallHmi_D_Stat 15 "NotUsed_1" 14 "Standby" 13 "Disabled" 12 "Malfunction" 11 "CallCompleted" 10 "CallDisconnected" 9 "CallNotPossible" 8 "CallCancelled" 7 "CallRetry" 6 "CallConnected" 5 "CallInProgress" 4 "CallMsdTransfer" 3 "CallDial" 2 "CallCancelTimer" 1 "NoEvent" 0 "Null" ;
VAL_ 638 EmgcyCallFalt_B_Dsply 1 "Yes" 0 "No" ;
VAL_ 638 EmgcyCall_D_Stat 7 "NotUsed_3" 6 "NotUsed_2" 5 "NotUsed_1" 4 "ManualEmergencyCall" 3 "AutoEmergencyCall" 2 "NoEvent" 1 "EmergencyCallNotSupported" 0 "Null" ;
VAL_ 555 HudVertSzMnuOn_B_Stat 1 "On" 0 "Off" ;
VAL_ 555 HudVertMnuOn_B_Stat 1 "Yes" 0 "No" ;
VAL_ 555 HudTestMdeActv_B_Stat 1 "Active" 0 "Inactive" ;
VAL_ 555 HudSwtch_B_Stat 1 "Pressed" 0 "Not_Pressed" ;
VAL_ 555 HudRotatMnuOn_B_Stat 1 "Yes" 0 "No" ;
VAL_ 555 HudMsgTxt_D_Rq 7 "Message7" 6 "Message6" 5 "Message5" 4 "Message4" 3 "Message3" 2 "Message2" 1 "Message1" 0 "NoMessage" ;
VAL_ 555 HudHzntlMnuOn_B_Stat 1 "Yes" 0 "No" ;
VAL_ 555 HudBrightMnuOn_B_Stat 1 "Yes" 0 "No" ;
VAL_ 555 HudActv_D_Stat 7 "Faulty" 6 "NotUsed_2" 5 "NotUsed_1" 4 "Error" 3 "Active" 2 "Pending" 1 "Inactive" 0 "NoData" ;
VAL_ 124 VehTrvlDir_D_Stat 7 "Faulty" 6 "NoDataExists" 5 "NotUsed2" 4 "NotUsed1" 3 "Reverse" 2 "LikelyReverse" 1 "Forward" 0 "LikelyForward" ;
VAL_ 124 VehOverGnd_V_Est 65535 "Invalid" 65534 "Unknown" ;
VAL_ 124 VehLongComp_A_Actl 1023 "Fault" 1022 "NoDataExists" ;
VAL_ 124 VehLatComp_A_Actl 1023 "Fault" 1022 "NoDataExists" ;
VAL_ 124 VehYawComp_W_Actl 4095 "Fault" 4094 "NoDataExists" ;
VAL_ 736 TextMessage_Rsp 3 "Cancelled" 2 "MessageIgnored" 1 "Listening" 0 "Invalid" ;
VAL_ 736 VRM_IncCallOption_St 0 "Inactive" 1 "RejectAll" 2 "AcceptIncomingCall" 3 "Silent" ;
VAL_ 736 BTInCallOptions_St 6 "HoldModeoff" 5 "InHoldMode" 4 "InHandsFreeMode" 3 "InPrivacyMode" 2 "Joined" 1 "Switched" 0 "Inactive" ;
VAL_ 722 VRM_ComShuffleTrack_St 0 "Invalid" 1 "CommandNotIssued" 2 "On" 3 "Off" ;
VAL_ 722 VRM_ComCompression_St 0 "Invalid" 1 "CommandNotIssued" 2 "On" 3 "Off" ;
VAL_ 722 VRM_ComStFreqMode_St 0 "Invalid" 1 "CommandNotIssued" 2 "Fm" 3 "Am" 4 "Reserved" ;
VAL_ 722 VRM_ComAutostore_St 0 "Invalid" 1 "CommandNotIssued" 2 "PerfomAutostore" ;
VAL_ 722 VRM_ComBand_St 0 "Invalid" 1 "CommandNotIssued" 2 "Fm1" 3 "Fm2" 4 "Fmas" 5 "Am" 6 "Amas" 7 "AutostoreMode" ;
VAL_ 722 VRM_TMCVoice 0 "Invalid" 1 "CommandNotIssued" 2 "On" 3 "Off" ;
VAL_ 722 VRM_NewSMS 3 "UnreadSMSMessagesAvailable" 0 "Invalid" 1 "NewSmsAvailable" 2 "NoNewSmsAvailable" ;
VAL_ 722 VRM_ComRSEDisplay_St 0 "Invalid" 1 "CommandNotIssued" 2 "On" 3 "Off" ;
VAL_ 722 VRM_ComPresetCall_St 0 "Invalid" 1 "CommandNotIssued" 2 "Prescall1" 3 "Prescall2" 4 "Prescall3" 5 "Prescall4" 6 "Prescall5" 7 "Prescall6" ;
VAL_ 722 VRM_ComTape_St 0 "Invalid" 1 "CommandNotIssued" 2 "Play" 3 "Rewind" 4 "Forward" 5 "ChangeSide" 6 "AutosearchForward" 7 "AutosearchBackward" ;
VAL_ 722 VRM_ComShuffleDiscs_St 0 "Invalid" 1 "CommandNotIssued" 2 "On" 3 "Off" ;
VAL_ 722 VRM_ComDolbyNR_St 0 "Invalid" 1 "CommandNotIssued" 2 "On" 3 "Off" ;
VAL_ 722 VRM_ComSourceSelect_St 7 "BTAudio" 6 "Con" 0 "Invalid" 1 "CommandNotIssued" 2 "Radio" 3 "SDCard" 4 "SingleDisc" 5 "MultiDisc" ;
VAL_ 722 VRM_ComRouteStrategy_St 0 "Invalid" 1 "CommandNotIssued" 2 "Shortesttime" 3 "Shortestdistance" 4 "Majorroadsavoid" 5 "Majorroadsprefer" 6 "TollRoadsaviod" 7 "TollRoadsprefer" 8 "Ferriesavoid" 9 "Ferriesprefer" ;
VAL_ 721 VRM_BTDefaultPhone_St 0 "Invalid" 1 "PhoneIndex1" 2 "PhoneIndex2" 3 "PhoneIndex3" 4 "PhoneIndex4" 5 "PhoneIndex5" 6 "PhoneIndex6" 7 "CradlePhone" 8 "NoPhone" ;
VAL_ 721 VRM_DetourUnit_st 0 "Invalid" 1 "Miles" 2 "Kilometer" 3 "Nounitdefined" ;
VAL_ 721 VRM_Zoom_Option_St 0 "Invalid" 1 "AbsoluteValue" 2 "InrelativeValue" 3 "OutrelativeValue" ;
VAL_ 721 VRM_ComBTDTMFTone_St 14 "Dtmfplus" 0 "Invalid" 1 "CommandNotIssued" 2 "Dtmf0" 3 "Dtmf1" 4 "Dtmf2" 5 "Dtmf3" 6 "Dtmf4" 7 "Dtmf5" 8 "Dtmf6" 9 "Dtmf7" 10 "Dtmf8" 11 "Dtmf9" 12 "Dtmfstar" 13 "Dtmfcross" ;
VAL_ 721 VRM_SuggestedRoute_St 0 "Invalid" 1 "CommandNotIssued" 2 "Accept" 3 "Reject" ;
VAL_ 721 VRM_ComDelWaypoint_St 0 "Invalid" 1 "CommandNotIssued" 2 "DeleteNextWayptDestination" ;
VAL_ 721 VRM_ComSelectDisc_St 0 "Invalid" 1 "CommandNotIssued" 2 "Disc1" 3 "Disc2" 4 "Disc3" 5 "Disc4" 6 "Disc5" 7 "Disc6" ;
VAL_ 721 VRM_ComTelService_St 0 "Invalid" 1 "CommandNotIssued" 2 "InformationCall" 3 "TelephonyCall" 4 "RedialLastIncoming" ;
VAL_ 721 VRM_ComDestHome_St 0 "Invalid" 1 "CommandNotIssued" 2 "SetDestinationHome" ;
VAL_ 721 VRM_ComShowNavInfo_St 0 "Invalid" 1 "CommandNotIssued" 2 "CurrentPos" 3 "Destination" 4 "CompleteRoute" 5 "NorthDirectionToTop" 6 "CarDirectionToTop" 7 "TurnList" ;
VAL_ 721 VRM_VoiceRecStatus_St 0 "Invalid" 1 "Idle" 2 "Listening" 3 "Reserved" 4 "CommandNotAllowed" ;
VAL_ 721 VRM_ComSelTrackSource_St 0 "Invalid" 1 "CommandNotIssued" 2 "Cd" 3 "CdChanger" ;
VAL_ 721 VRM_ComDetour_St 0 "Invalid" 1 "CommandNotIssued" 2 "Detour1" 3 "Detour2" 4 "Detour3" 5 "Detour4" 6 "Detour5" 7 "Detour10" 8 "Detour15" 9 "Detour20" 10 "Detour25" 11 "Detour50" 12 "Detour100" ;
VAL_ 721 VRM_ComDisplay_St 0 "Invalid" 1 "CommandNotIssued" 2 "DisplayOn" 3 "DisplayOff" 4 "Day" 5 "Night" 6 "Auto" 7 "Twilight" ;
VAL_ 721 VRM_ComDynamicGuidande_St 0 "Invalid" 1 "CommandNotIssued" 2 "On" 3 "Off" ;
VAL_ 721 VRM_ComZoom_St 0 "Invalid" 1 "CommandNotIssued" 2 "Level1" 3 "Level2" 4 "Level3" 5 "Level4" 6 "Level5" 7 "Level6" 8 "Level7" 9 "Level8" 10 "Level9" 11 "Level10" 12 "Level11" 13 "Level12" 14 "Level13" ;
VAL_ 721 VRM_ComCallControl_St 0 "Invalid" 1 "CommandNotIssued" 2 "Pickup" 3 "Reject" 4 "EndOngoingCall" ;
VAL_ 721 VRM_ComGuidance_St 0 "Invalid" 1 "CommandNotIssued" 2 "VoiceGuidanceOn" 3 "VoiceGuidanceOff" 4 "CancelGuidance" 5 "RepeatLastVoiceGuidance" ;
VAL_ 721 VRM_ComTrafficInfDsp_St 0 "Invalid" 1 "CommandNotIssued" 2 "ShowTrafficInfoOnDisplay" 3 "HideTrafficInfoOnDisplay" ;
VAL_ 720 VRM_PhMicrophoneMute_St 3 "Reserved" 2 "MicrophoneIsUnmuted" 1 "MicrophoneIsMuted" 0 "Invalid" ;
VAL_ 720 Aioc_ExtSrcOutpMode_St 8 "NotAllocated" 4 "AllocatedBtAudio" 3 "AllocatedBtNavigation" 2 "AllocatedBtPhone" 1 "AllocatedVr" 0 "Invalid" 7 "AllocatedAUX3" 6 "AllocatediPod" 5 "AllocatedUSB" ;
VAL_ 720 VRM_BTPhoneSts_St 16 "Connected_Call_on_hold" 15 "Conference_OtherCallOnHold" 0 "Invalid" 1 "Idle" 2 "Dialing" 3 "Connected" 4 "CradlephNotReady" 5 "NumUnobtainable" 6 "IncomCall" 7 "NoLinkToBt" 8 "InitBtCon" 9 "PhoneBusy" 10 "PhoneVr" 11 "NotSupported" 12 "BtPhPriv" 13 "ConfCall" 14 "Conference_2ndIncCall" ;
VAL_ 720 VRM_SubscribeStatus_St 0 "Invalid" 1 "OnSubscribingInfo" 2 "OffNotSubscribingInfo" ;
VAL_ 720 VRM_BlutoothStatus_St 0 "Invalid" 1 "On" 2 "Off" ;
VAL_ 720 VRM_BondRequest_St 0 "Invalid" 1 "BondRequestExist" 2 "NoBondRequestExist" ;
VAL_ 720 VRM_VRMMonoOutMode_St 0 "Invalid" 1 "AllocatedVr" 2 "AllocatedBt" 3 "NotAllocated" ;
VAL_ 720 VRM_BTNetworkStatus_St 0 "Invalid" 1 "NoNetwork" 2 "InNetwork" 3 "Roaming" 4 "NoLinkToBtPhone" 5 "NotSupportedByBtPhone" ;
VAL_ 720 VRM_BTSignalStrength_St 0 "Invalid" 1 "SignalStrength0" 2 "SignalStrength1" 3 "SignalStrength2" 4 "SignalStrength3" 5 "SignalStrength4" 6 "SignalStrength5" 7 "NoLinkToBtPhone" 8 "NotSupportedByBtPhone" ;
VAL_ 720 VRM_BTBatteryLevel_St 0 "Invalid" 1 "Level0" 2 "Level1" 3 "Level2" 4 "Level3" 5 "Level4" 6 "Level5" 7 "NoLinkToBtPhone" 8 "NotSupportedByBtPhone" ;
VAL_ 470 VRM_BTIncomingCall_Rsp 0 "Inactive" 1 "Accepted" 2 "Declined" 3 "Failed" ;
VAL_ 470 VRM_BTEndTelService_Rsp 3 "Error" 0 "Inactive" 1 "IntermediateResult" 2 "FinalResult" ;
